VERSION ""

NS_ :

BS_:

BU_: PDCM EPB LBMS GW ExternalTool

BO_ 734 AC_OBD_alertMatrix1: 8 GW
 SG_ AC_OBD_f032_Reserved : 1|2@0+ (1,0) [0|2] ""  PDCM
 SG_ AC_OBD_f033_Reserved : 3|2@0+ (1,0) [0|2] ""  PDCM
 SG_ AC_OBD_f034_HVWHforHC_LostCom : 5|2@0+ (1,0) [0|2] ""  PDCM
 SG_ AC_OBD_f035_HVWHforHC_OveVol : 7|2@0+ (1,0) [0|2] ""  PDCM
 SG_ AC_OBD_f036_HVWHforHC_UndVol : 9|2@0+ (1,0) [0|2] ""  PDCM
 SG_ AC_OBD_f037_HVWHforHC_BoiErr : 11|2@0+ (1,0) [0|2] ""  PDCM
 SG_ AC_OBD_f038_HVWHforHC_CirErr : 13|2@0+ (1,0) [0|2] ""  PDCM
 SG_ AC_OBD_f039_WaterPumpHC : 15|2@0+ (1,0) [0|2] ""  PDCM
 SG_ AC_OBD_f040_3WayValForBat_LosCom : 17|2@0+ (1,0) [0|2] ""  PDCM
 SG_ AC_OBD_f041_3WayValForBat_ResErr : 19|2@0+ (1,0) [0|2] ""  PDCM
 SG_ AC_OBD_f042_3WayValForBat_ActErr : 21|2@0+ (1,0) [0|2] ""  PDCM
 SG_ AC_OBD_f043_3WayValForBat_VolErr : 23|2@0+ (1,0) [0|2] ""  PDCM
 SG_ AC_OBD_f044_ECU_IntFau : 25|2@0+ (1,0) [0|2] ""  PDCM
 SG_ AC_OBD_f045_AMBSensor_SBOL : 27|2@0+ (1,0) [0|2] ""  PDCM
 SG_ AC_OBD_f046_AMBSensor_SG : 29|2@0+ (1,0) [0|2] ""  PDCM
 SG_ AC_OBD_f047_AMBSensor_OutRanLo : 31|2@0+ (1,0) [0|2] ""  PDCM
 SG_ AC_OBD_f048_AMBSensor_OutRanHi : 33|2@0+ (1,0) [0|2] ""  PDCM
 SG_ AC_OBD_f049_AMBSensor_RatFau : 35|2@0+ (1,0) [0|2] ""  PDCM
 SG_ AC_OBD_f050_UnderBatVol : 37|2@0+ (1,0) [0|2] ""  PDCM
 SG_ AC_OBD_f051_OverBatVol : 39|2@0+ (1,0) [0|2] ""  PDCM
 SG_ AC_OBD_f052_ComCANBusOff : 41|2@0+ (1,0) [0|2] ""  PDCM
 SG_ AC_OBD_f053_GW_NoCom : 43|2@0+ (1,0) [0|2] ""  PDCM
 SG_ AC_OBD_FaultClrsts : 47|1@0+ (1,0) [0|1] ""  PDCM
 SG_ AC_EDC_HV_Voltage : 55|8@0+ (5,0) [0|1270] "V"  PDCM
 SG_ AC_HVWH_Bat_HV_Voltage : 63|8@0+ (5,0) [0|500] "V"  PDCM

BO_ 731 AC_OBD_CVN: 8 GW
 SG_ AC_OBDCVNByte0 : 7|8@0+ (1,0) [0|255] ""  PDCM
 SG_ AC_OBDCVNByte1 : 15|8@0+ (1,0) [0|255] ""  PDCM
 SG_ AC_OBDCVNByte2 : 23|8@0+ (1,0) [0|255] ""  PDCM
 SG_ AC_OBDCVNByte3 : 31|8@0+ (1,0) [0|255] ""  PDCM
 SG_ AC_OBD_Comp_OverpPhaseCurrentError : 33|2@0+ (1,0) [0|2] ""  PDCM
 SG_ AC_OBD_Comp_TemperatureSensorError : 35|2@0+ (1,0) [0|2] ""  PDCM
 SG_ AC_OBD_Comp_CurrentSamplingError : 37|2@0+ (1,0) [0|2] ""  PDCM
 SG_ AC_OBD_Comp_DriverError : 39|2@0+ (1,0) [0|2] ""  PDCM
 SG_ AC_OBD_Comp_StartupError : 41|2@0+ (1,0) [0|2] ""  PDCM
 SG_ AC_OBD_Comp_OvertemperatureError : 43|2@0+ (1,0) [0|2] ""  PDCM
 SG_ AC_OBD_Comp_ECU_InternalError : 45|2@0+ (1,0) [0|2] ""  PDCM
 SG_ AC_OBD_Comp_StallError : 47|2@0+ (1,0) [0|2] ""  PDCM
 SG_ AC_OBD_Comp_Hv_UnderVoltageError : 49|2@0+ (1,0) [0|2] ""  PDCM
 SG_ AC_OBD_Comp_Hv_OverVoltageError : 51|2@0+ (1,0) [0|2] ""  PDCM
 SG_ AC_OBD_Comp_Lv_VoltageError : 53|2@0+ (1,0) [0|2] ""  PDCM
 SG_ AC_OBD_EDCStopError : 54|1@0+ (1,0) [0|1] ""  PDCM
 SG_ AC_OBD_PTC_BStopError : 55|1@0+ (1,0) [0|1] ""  PDCM
 SG_ AC_OBD_PTC_CStopError : 56|1@0+ (1,0) [0|1] ""  PDCM

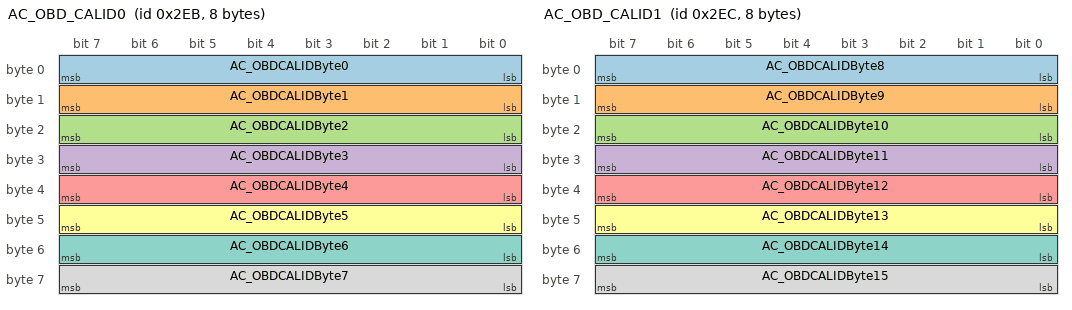
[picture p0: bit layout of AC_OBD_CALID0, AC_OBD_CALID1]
BO_ 747 AC_OBD_CALID0: 8 GW
 SG_ AC_OBDCALIDByte0 : 7|8@0+ (1,0) [0|255] ""  PDCM
 SG_ AC_OBDCALIDByte1 : 15|8@0+ (1,0) [0|255] ""  PDCM
 SG_ AC_OBDCALIDByte2 : 23|8@0+ (1,0) [0|255] ""  PDCM
 SG_ AC_OBDCALIDByte3 : 31|8@0+ (1,0) [0|255] ""  PDCM
 SG_ AC_OBDCALIDByte4 : 39|8@0+ (1,0) [0|255] ""  PDCM
 SG_ AC_OBDCALIDByte5 : 47|8@0+ (1,0) [0|255] ""  PDCM
 SG_ AC_OBDCALIDByte6 : 55|8@0+ (1,0) [0|255] ""  PDCM
 SG_ AC_OBDCALIDByte7 : 63|8@0+ (1,0) [0|255] ""  PDCM

BO_ 748 AC_OBD_CALID1: 8 GW
 SG_ AC_OBDCALIDByte8 : 7|8@0+ (1,0) [0|255] ""  PDCM
 SG_ AC_OBDCALIDByte9 : 15|8@0+ (1,0) [0|255] ""  PDCM
 SG_ AC_OBDCALIDByte10 : 23|8@0+ (1,0) [0|255] ""  PDCM
 SG_ AC_OBDCALIDByte11 : 31|8@0+ (1,0) [0|255] ""  PDCM
 SG_ AC_OBDCALIDByte12 : 39|8@0+ (1,0) [0|255] ""  PDCM
 SG_ AC_OBDCALIDByte13 : 47|8@0+ (1,0) [0|255] ""  PDCM
 SG_ AC_OBDCALIDByte14 : 55|8@0+ (1,0) [0|255] ""  PDCM
 SG_ AC_OBDCALIDByte15 : 63|8@0+ (1,0) [0|255] ""  PDCM

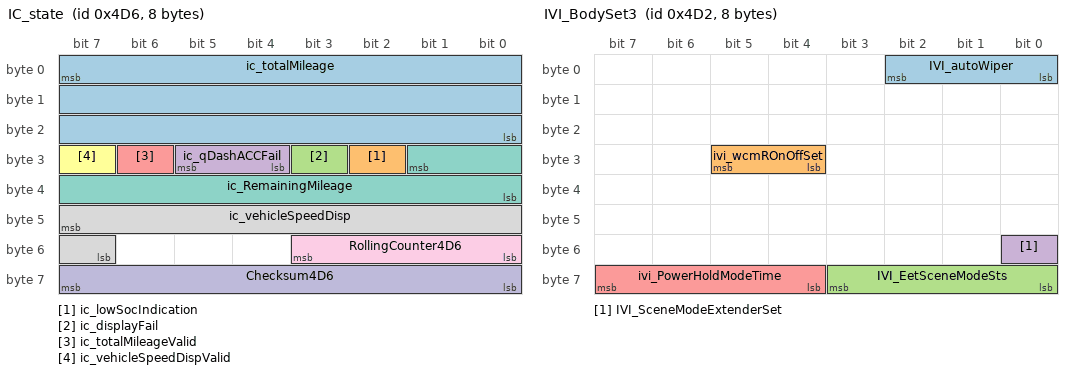
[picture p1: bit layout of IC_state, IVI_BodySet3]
BO_ 1238 IC_state: 8 PDCM
 SG_ ic_totalMileage : 7|24@0+ (0.1,0) [0|1677721.3] "km"  EPB,LBMS,GW
 SG_ ic_lowSocIndication : 26|1@0+ (1,0) [0|1] ""  GW
 SG_ ic_displayFail : 27|1@0+ (1,0) [0|1] ""  GW
 SG_ ic_qDashACCFail : 29|2@0+ (1,0) [0|3] ""  GW
 SG_ ic_totalMileageValid : 30|1@0+ (1,0) [0|1] ""  EPB,LBMS,GW
 SG_ ic_vehicleSpeedDispValid : 31|1@0+ (1,0) [0|1] ""  GW
 SG_ ic_RemainingMileage : 25|10@0+ (1,0) [0|1022] "km"  GW
 SG_ ic_vehicleSpeedDisp : 47|9@0+ (1,0) [0|280] "KPH"  GW
 SG_ RollingCounter4D6 : 51|4@0+ (1,0) [0|15] ""  EPB,LBMS,GW
 SG_ Checksum4D6 : 63|8@0+ (1,0) [0|255] ""  EPB,LBMS,GW

BO_ 1234 IVI_BodySet3: 8 GW
 SG_ IVI_autoWiper : 2|3@0+ (1,0) [0|7] ""  PDCM
 SG_ ivi_wcmROnOffSet : 29|2@0+ (1,0) [0|3] ""  PDCM
 SG_ IVI_EetSceneModeSts : 59|4@0+ (1,0) [0|15] ""  PDCM
 SG_ IVI_SceneModeExtenderSet : 48|1@0+ (1,0) [0|1] ""  PDCM
 SG_ ivi_PowerHoldModeTime : 63|4@0+ (1,0) [0|15] ""  PDCM

BO_ 896 ACU_state: 8 GW
 SG_ acu_warningLampSts : 1|2@0+ (1,0) [0|3] ""  Vector__XXX
 SG_ acu_crashOutputStsValid : 3|2@0+ (1,0) [0|3] ""  LBMS
 SG_ acu_driverSeatBeltSts : 8|1@0+ (1,0) [0|1] ""  Vector__XXX
 SG_ acu_driverSeatBeltStsValid : 9|1@0+ (1,0) [0|1] ""  Vector__XXX
 SG_ acu_passengerSeatBeltSts : 10|1@0+ (1,0) [0|1] ""  Vector__XXX
 SG_ acu_passengerSeatBeltStsValid : 11|1@0+ (1,0) [0|1] ""  Vector__XXX
 SG_ acu_passengerAirbagSts : 13|2@0+ (1,0) [0|3] ""  Vector__XXX
 SG_ acu_secondLeftSeatBeltSts : 14|1@0+ (1,0) [0|1] ""  Vector__XXX
 SG_ acu_secondMiddleSeatBeltSts : 15|1@0+ (1,0) [0|1] ""  Vector__XXX
 SG_ acu_secondRightSeatBeltSts : 16|1@0+ (1,0) [0|1] ""  Vector__XXX
 SG_ acu_passengerSts : 17|1@0+ (1,0) [0|1] ""  Vector__XXX
 SG_ acu_secondLeftSts : 18|1@0+ (1,0) [0|1] ""  Vector__XXX
 SG_ acu_secondMiddleSts : 19|1@0+ (1,0) [0|1] ""  Vector__XXX
 SG_ acu_secondRightSts : 20|1@0+ (1,0) [0|1] ""  Vector__XXX
 SG_ acu_crashOutputSts : 31|8@0+ (1,0) [0|255] ""  LBMS
 SG_ RollingCounter380 : 51|4@0+ (1,0) [0|15] ""  LBMS
 SG_ Checksum380 : 63|8@0+ (1,0) [0|255] ""  LBMS

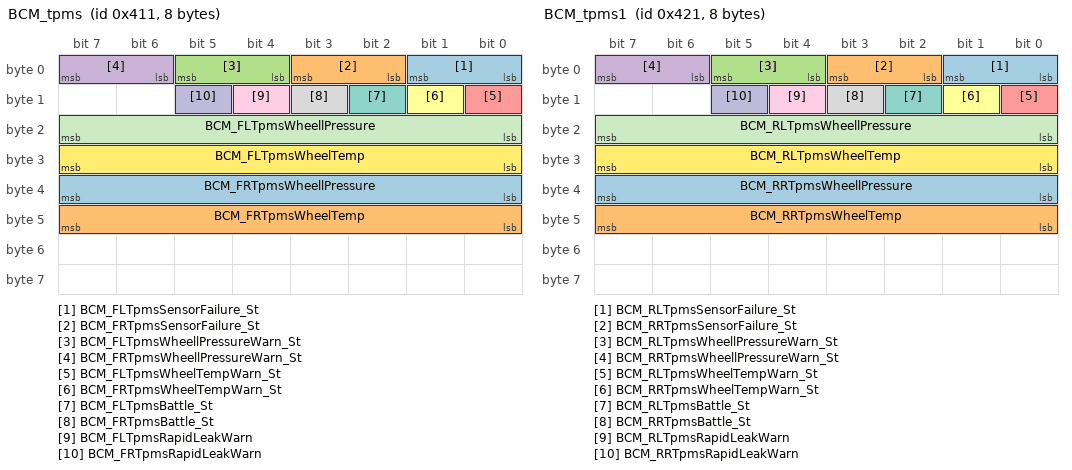
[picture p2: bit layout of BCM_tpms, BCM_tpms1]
BO_ 1041 BCM_tpms: 8 PDCM
 SG_ BCM_FLTpmsSensorFailure_St : 1|2@0+ (1,0) [0|3] ""  Vector__XXX
 SG_ BCM_FRTpmsSensorFailure_St : 3|2@0+ (1,0) [0|3] ""  Vector__XXX
 SG_ BCM_FLTpmsWheellPressureWarn_St : 5|2@0+ (1,0) [0|3] ""  Vector__XXX
 SG_ BCM_FRTpmsWheellPressureWarn_St : 7|2@0+ (1,0) [0|3] ""  Vector__XXX
 SG_ BCM_FLTpmsWheelTempWarn_St : 8|1@0+ (1,0) [0|1] ""  Vector__XXX
 SG_ BCM_FRTpmsWheelTempWarn_St : 9|1@0+ (1,0) [0|1] ""  Vector__XXX
 SG_ BCM_FLTpmsBattle_St : 10|1@0+ (1,0) [0|1] ""  Vector__XXX
 SG_ BCM_FRTpmsBattle_St : 11|1@0+ (1,0) [0|1] ""  Vector__XXX
 SG_ BCM_FLTpmsRapidLeakWarn : 12|1@0+ (1,0) [0|1] ""  Vector__XXX
 SG_ BCM_FRTpmsRapidLeakWarn : 13|1@0+ (1,0) [0|1] ""  Vector__XXX
 SG_ BCM_FLTpmsWheellPressure : 23|8@0+ (0.1,0) [0|7] ""  Vector__XXX
 SG_ BCM_FLTpmsWheelTemp : 31|8@0+ (1,-61) [-61|193] ""  Vector__XXX
 SG_ BCM_FRTpmsWheellPressure : 39|8@0+ (0.1,0) [0|7] ""  Vector__XXX
 SG_ BCM_FRTpmsWheelTemp : 47|8@0+ (1,-61) [-61|193] ""  Vector__XXX

BO_ 1057 BCM_tpms1: 8 PDCM
 SG_ BCM_RLTpmsSensorFailure_St : 1|2@0+ (1,0) [0|3] ""  Vector__XXX
 SG_ BCM_RRTpmsSensorFailure_St : 3|2@0+ (1,0) [0|3] ""  Vector__XXX
 SG_ BCM_RLTpmsWheellPressureWarn_St : 5|2@0+ (1,0) [0|3] ""  Vector__XXX
 SG_ BCM_RRTpmsWheellPressureWarn_St : 7|2@0+ (1,0) [0|3] ""  Vector__XXX
 SG_ BCM_RLTpmsWheelTempWarn_St : 8|1@0+ (1,0) [0|1] ""  Vector__XXX
 SG_ BCM_RRTpmsWheelTempWarn_St : 9|1@0+ (1,0) [0|1] ""  Vector__XXX
 SG_ BCM_RLTpmsBattle_St : 10|1@0+ (1,0) [0|1] ""  Vector__XXX
 SG_ BCM_RRTpmsBattle_St : 11|1@0+ (1,0) [0|1] ""  Vector__XXX
 SG_ BCM_RLTpmsRapidLeakWarn : 12|1@0+ (1,0) [0|1] ""  Vector__XXX
 SG_ BCM_RRTpmsRapidLeakWarn : 13|1@0+ (1,0) [0|1] ""  Vector__XXX
 SG_ BCM_RLTpmsWheellPressure : 23|8@0+ (0.1,0) [0|7] ""  Vector__XXX
 SG_ BCM_RLTpmsWheelTemp : 31|8@0+ (1,-61) [-61|193] ""  Vector__XXX
 SG_ BCM_RRTpmsWheellPressure : 39|8@0+ (0.1,0) [0|7] ""  Vector__XXX
 SG_ BCM_RRTpmsWheelTemp : 47|8@0+ (1,-61) [-61|193] ""  Vector__XXX

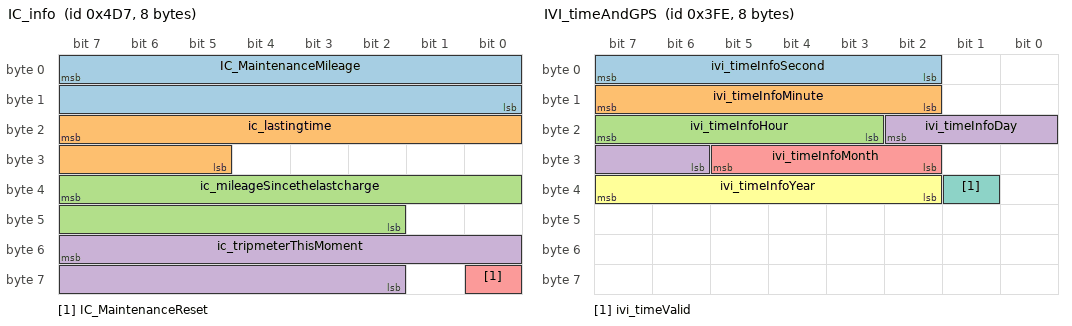
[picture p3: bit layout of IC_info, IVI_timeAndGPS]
BO_ 1239 IC_info: 8 PDCM
 SG_ IC_MaintenanceMileage : 7|16@0+ (1,0) [0|50000] "km"  GW
 SG_ ic_lastingtime : 23|11@0+ (1,0) [0|1440] "min"  GW
 SG_ ic_mileageSincethelastcharge : 39|14@0+ (0.1,0) [0|999.9] "km"  GW
 SG_ ic_tripmeterThisMoment : 55|14@0+ (0.1,0) [0|999.9] "km"  GW
 SG_ IC_MaintenanceReset : 56|1@0+ (1,0) [0|1] ""  GW

BO_ 1235 IC_info1: 8 PDCM
 SG_ ic_totalMileageRev : 7|24@0+ (0.1,0) [0|1677721.3] "km"  GW

BO_ 1022 IVI_timeAndGPS: 8 GW
 SG_ ivi_timeInfoSecond : 7|6@0+ (1,0) [0|59] ""  PDCM,EPB,LBMS
 SG_ ivi_timeInfoMinute : 15|6@0+ (1,0) [0|59] ""  PDCM,EPB,LBMS
 SG_ ivi_timeInfoHour : 23|5@0+ (1,0) [0|23] ""  PDCM,EPB,LBMS
 SG_ ivi_timeInfoDay : 18|5@0+ (1,0) [1|31] ""  PDCM,EPB,LBMS
 SG_ ivi_timeInfoMonth : 29|4@0+ (1,0) [1|12] ""  PDCM,EPB,LBMS
 SG_ ivi_timeInfoYear : 39|6@0+ (1,2000) [2000|2059] ""  PDCM,EPB,LBMS
 SG_ ivi_timeValid : 33|1@0+ (1,0) [0|1] ""  PDCM,EPB,LBMS

BO_ 117 IVI_control: 8 GW
 SG_ ivi_hoodUnlockCtrl : 1|2@0+ (1,0) [0|3] ""  Vector__XXX
 SG_ IVI_SOCmodeSet : 3|2@0+ (1,0) [0|3] ""  PDCM
 SG_ ivi_gloveBoxUnlockCtrl : 5|2@0+ (1,0) [0|3] ""  Vector__XXX
 SG_ IVI_EVonlymodereq_HW : 7|2@0+ (1,0) [0|3] ""  PDCM
 SG_ ivi_v2vChrgOnOffSet : 13|2@0+ (1,0) [0|3] ""  PDCM
 SG_ ivi_obcDschrgOnOffSet : 17|2@0+ (1,0) [0|3] ""  PDCM
 SG_ ivi_modememory : 19|2@0+ (1,0) [0|3] ""  Vector__XXX
 SG_ ivi_gunUnlockCtrlReq : 20|1@0+ (1,0) [0|1] ""  PDCM
 SG_ IVI_apaOnOffSet : 24|1@0+ (1,0) [0|1] ""  Vector__XXX
 SG_ IVI_AVMOnOffSet : 25|1@0+ (1,0) [0|1] ""  Vector__XXX
 SG_ IVI_PDCOnOffSet : 26|1@0+ (1,0) [0|1] ""  Vector__XXX
 SG_ IVI_V2LMinSocSet : 30|4@0+ (5,5) [5|60] "%"  PDCM
 SG_ IVI_UserPrivacyModeSts : 33|2@0+ (1,0) [0|3] ""  Vector__XXX
 SG_ IVI_SelfHeatingAllow : 35|2@0+ (1,0) [0|3] ""  PDCM
 SG_ ivi_ExhibitionSet : 38|3@0+ (1,0) [0|7] ""  PDCM
 SG_ ivi_v2vChrgOptCurntSet : 47|4@0+ (1,0) [0|15] "A"  PDCM
 SG_ ivi_BatteryCondition : 49|2@0+ (1,0) [0|3] ""  Vector__XXX
 SG_ IVI_SREVSOCset : 53|4@0+ (5,25) [25|80] "%"  PDCM
 SG_ IVI_SREVSOCset_HW : 59|4@0+ (1,0) [0|15] ""  PDCM
 SG_ IVI_EVonlymodereq : 61|1@0+ (1,0) [0|1] ""  PDCM
 SG_ ivi_lowVoltPowerCtrl : 63|2@0+ (1,0) [0|3] ""  Vector__XXX

BO_ 165 IVI_pwrSet: 8 GW
 SG_ ivi_MaxFuelConsumptionSW : 1|2@0+ (1,0) [0|3] ""  PDCM
 SG_ ivi_maxChargeCurrentSet : 7|6@0+ (1,5) [5|67] "A"  PDCM
 SG_ ivi_ChargeCancel : 8|1@0+ (1,0) [0|1] ""  PDCM
 SG_ ivi_RegenModeSet : 11|3@0+ (1,0) [0|7] ""  PDCM
 SG_ ivi_MaxFuelConsumptionModeSW : 13|2@0+ (1,0) [0|3] ""  PDCM
 SG_ ivi_propModeSet : 15|2@0+ (1,0) [0|3] ""  PDCM
 SG_ ivi_maxChrgSocSet : 23|8@0+ (1,0) [0|100] "%"  PDCM
 SG_ ivi_startRevSOCSet : 29|6@0+ (1,19) [19|80] "%"  PDCM
 SG_ ivi_ChargeEndTimeHalfDay : 30|1@0+ (1,0) [0|1] ""  PDCM
 SG_ ivi_ChargeStartTimeHalfDay : 31|1@0+ (1,0) [0|1] ""  PDCM
 SG_ ivi_ChargeEndTimeHour : 35|4@0+ (1,0) [0|15] ""  PDCM
 SG_ ivi_ChargeStartTimeHour : 39|4@0+ (1,0) [0|15] ""  PDCM
 SG_ ivi_chargeFormSet : 41|2@0+ (1,0) [0|3] ""  PDCM
 SG_ ivi_ChargeEndTimeMinute : 47|6@0+ (1,0) [0|59] ""  PDCM
 SG_ ivi_ChargeStartTimeMinute : 53|6@0+ (1,0) [0|59] ""  PDCM
 SG_ ivi_ChargeEnable : 54|1@0+ (1,0) [0|1] ""  PDCM
 SG_ ivi_chargeSetValid : 55|1@0+ (1,0) [0|1] ""  PDCM
 SG_ ivi_ResetCurrentTrip : 57|1@0+ (1,0) [0|1] ""  PDCM
 SG_ ivi_ChargeEndTimeValid : 58|1@0+ (1,0) [0|1] ""  PDCM
 SG_ ivi_ChargeStartTimeValid : 59|1@0+ (1,0) [0|1] ""  PDCM
 SG_ ivi_driveModeSet : 62|3@0+ (1,0) [0|7] ""  PDCM

BO_ 476 IVI_BodySet1: 8 GW
 SG_ ivi_centralLockCtrl : 1|2@0+ (1,0) [0|3] ""  PDCM
 SG_ ivi_fuelPortCapOpenCtrl : 3|2@0+ (1,0) [0|3] ""  PDCM
 SG_ ivi_chrgPortCapOpenCtrl : 5|2@0+ (1,0) [0|3] ""  PDCM
 SG_ ivi_antiTheftAlarmFormSet : 7|2@0+ (1,0) [0|3] ""  PDCM
 SG_ ivi_approachingUnlockCtrl : 9|2@0+ (1,0) [0|3] ""  PDCM
 SG_ ivi_awayLockCtrl : 11|2@0+ (1,0) [0|3] ""  PDCM
 SG_ ivi_parkAutoCloseDRLCtrl : 13|2@0+ (1,0) [0|3] ""  PDCM
 SG_ ivi_welcomeSetEnable : 15|2@0+ (1,0) [0|3] ""  PDCM
 SG_ ivi_welcomeOnOffSet : 19|4@0+ (1,0) [0|15] ""  PDCM
 SG_ ivi_followMeHomeSet : 22|3@0+ (1,0) [0|7] ""  PDCM
 SG_ ivi_WiperMaintenanceCtrl : 25|2@0+ (1,0) [0|3] ""  PDCM
 SG_ ivi_lockAutoCloseWinCtrl : 27|2@0+ (1,0) [0|3] ""  PDCM
 SG_ IVI_Backlightadjust : 31|4@0+ (1,0) [0|10] ""  PDCM
 SG_ IVI_Sunroof_HorizontalControl : 38|7@0+ (1,0) [0|100] "%"  PDCM
 SG_ ivi_VehiclePowerOFF : 39|1@0+ (1,0) [0|1] ""  PDCM
 SG_ ivi_sunroofGlassCmd : 42|3@0+ (1,0) [0|7] ""  PDCM
 SG_ ivi_sunroofRollshadeCtrlSelect : 45|2@0+ (1,0) [0|3] ""  PDCM
 SG_ ivi_tailgateCtrl : 47|2@0+ (1,0) [0|3] ""  PDCM
 SG_ IVI_FLReadLightReq : 49|2@0+ (1,0) [0|3] ""  PDCM
 SG_ IVI_FRReadLightReq : 51|2@0+ (1,0) [0|3] ""  PDCM
 SG_ IVI_RLReadLightReq : 53|2@0+ (1,0) [0|3] ""  PDCM
 SG_ IVI_RReadLightReq : 55|2@0+ (1,0) [0|3] ""  PDCM
 SG_ IVI_ITLToplampReq : 57|2@0+ (1,0) [0|3] ""  PDCM
 SG_ ivi_languageSet : 59|2@0+ (1,0) [0|3] ""  PDCM
 SG_ ivi_unitSet : 61|2@0+ (1,0) [0|3] ""  PDCM
 SG_ ivi_OutsideLockAlarmFormSet : 63|2@0+ (1,0) [0|3] ""  PDCM

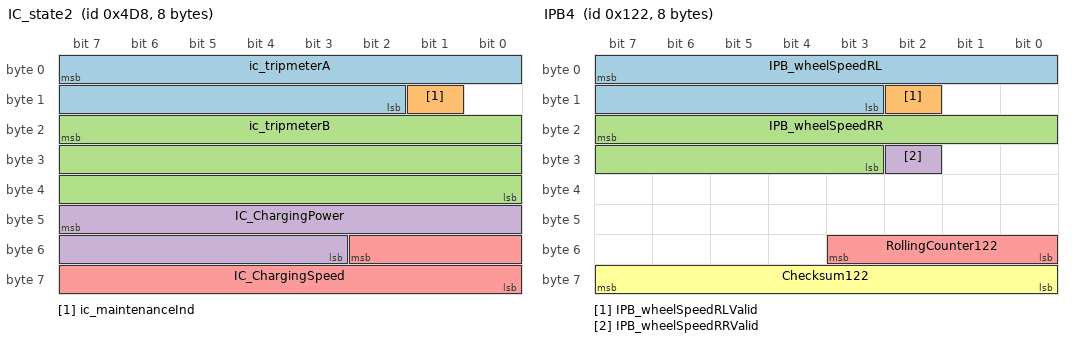
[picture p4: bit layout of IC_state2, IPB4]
BO_ 1240 IC_state2: 8 PDCM
 SG_ ic_tripmeterA : 7|14@0+ (0.1,0) [0|1000] "km"  GW
 SG_ ic_maintenanceInd : 9|1@0+ (1,0) [0|1] ""  GW
 SG_ ic_tripmeterB : 23|24@0+ (0.1,0) [0|99999.9] "km"  GW
 SG_ IC_ChargingPower : 47|13@0+ (0.1,0) [0|500] "kW"  GW
 SG_ IC_ChargingSpeed : 50|11@0+ (1,0) [0|2000] "km/h"  GW

BO_ 290 IPB4: 8 GW
 SG_ IPB_wheelSpeedRL : 7|13@0+ (0.05625,0) [0|270] "km/h"  EPB
 SG_ IPB_wheelSpeedRLValid : 10|1@0+ (1,0) [0|1] ""  EPB
 SG_ IPB_wheelSpeedRR : 23|13@0+ (0.05625,0) [0|270] "km/h"  EPB
 SG_ IPB_wheelSpeedRRValid : 26|1@0+ (1,0) [0|1] ""  EPB
 SG_ RollingCounter122 : 51|4@0+ (1,0) [0|15] ""  EPB
 SG_ Checksum122 : 63|8@0+ (1,0) [0|255] ""  EPB

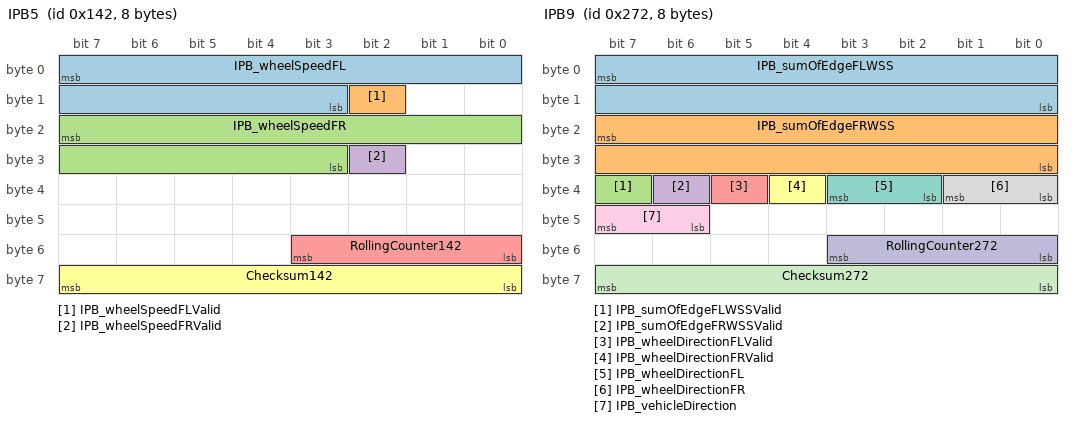
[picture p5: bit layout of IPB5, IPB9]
BO_ 322 IPB5: 8 GW
 SG_ IPB_wheelSpeedFL : 7|13@0+ (0.05625,0) [0|270] "km/h"  EPB
 SG_ IPB_wheelSpeedFLValid : 10|1@0+ (1,0) [0|1] ""  EPB
 SG_ IPB_wheelSpeedFR : 23|13@0+ (0.05625,0) [0|270] "km/h"  EPB
 SG_ IPB_wheelSpeedFRValid : 26|1@0+ (1,0) [0|1] ""  EPB
 SG_ RollingCounter142 : 51|4@0+ (1,0) [0|15] ""  EPB
 SG_ Checksum142 : 63|8@0+ (1,0) [0|255] ""  EPB

BO_ 160 IPB7: 8 GW
 SG_ IPB_vehicleSpeed : 7|13@0+ (0.05625,0) [0|270] "km/h"  EPB,LBMS
 SG_ IPB_vehicleSpeedValid : 10|1@0+ (1,0) [0|1] ""  EPB,LBMS
 SG_ IPB_absFault : 9|1@0+ (1,0) [0|1] ""  Vector__XXX
 SG_ IPB_absActive : 8|1@0+ (1,0) [0|1] ""  Vector__XXX
 SG_ IPB_vdcActive : 16|1@0+ (1,0) [0|1] ""  Vector__XXX
 SG_ IPB_tcsActive : 17|1@0+ (1,0) [0|1] ""  Vector__XXX
 SG_ IPB_avhModeWSts : 19|2@0+ (1,0) [0|3] ""  Vector__XXX
 SG_ IPB_avhAvailable : 20|1@0+ (1,0) [0|1] ""  Vector__XXX
 SG_ IPB_cdpActive : 21|1@0+ (1,0) [0|1] ""  Vector__XXX
 SG_ IPB_cdpAvailable : 22|1@0+ (1,0) [0|1] ""  Vector__XXX
 SG_ IPB_hdcAvailable : 23|1@0+ (1,0) [0|1] ""  Vector__XXX
 SG_ IPB_epbRequest : 25|2@0+ (1,0) [0|3] ""  EPB
 SG_ IPB_vehicleStandstill : 27|2@0+ (1,0) [0|3] ""  Vector__XXX
 SG_ IPB_vehicleStandstillValid : 28|1@0+ (1,0) [0|1] ""  Vector__XXX
 SG_ IPB_ModeSts : 29|1@0+ (1,0) [0|1] ""  Vector__XXX
 SG_ IPB_brakelightRequest : 30|1@0+ (1,0) [0|1] ""  Vector__XXX
 SG_ IPB_hdcSts : 34|3@0+ (1,0) [0|3] ""  Vector__XXX
 SG_ IPB_hhcActive : 35|1@0+ (1,0) [0|1] ""  Vector__XXX
 SG_ IPB_hhcAvailable : 36|1@0+ (1,0) [0|1] ""  Vector__XXX
 SG_ IPB_ebdFault : 37|1@0+ (1,0) [0|1] ""  Vector__XXX
 SG_ IPB_ebd_active : 38|1@0+ (1,0) [0|1] ""  Vector__XXX
 SG_ IPB_ESCoffSts : 39|1@0+ (1,0) [0|1] ""  Vector__XXX
 SG_ IPB_escFault : 40|1@0+ (1,0) [0|1] ""  Vector__XXX
 SG_ IPB_haz_active : 41|1@0+ (1,0) [0|1] ""  Vector__XXX
 SG_ IPB_hazErrorSt : 42|1@0+ (1,0) [0|1] ""  Vector__XXX
 SG_ IPB_hba_active : 43|1@0+ (1,0) [0|1] ""  Vector__XXX
 SG_ IPB_dtcActive : 44|1@0+ (1,0) [0|1] ""  Vector__XXX
 SG_ IPB_esclampdisplay : 46|2@0+ (1,0) [0|2] ""  Vector__XXX
 SG_ IPB_BDWActive : 52|1@0+ (1,0) [0|1] ""  Vector__XXX
 SG_ IPB_HRBActive : 53|1@0+ (1,0) [0|1] ""  Vector__XXX
 SG_ RollingCounter0A0 : 51|4@0+ (1,0) [0|15] ""  LBMS
 SG_ Checksum0A0 : 63|8@0+ (1,0) [0|255] ""  LBMS

BO_ 626 IPB9: 8 GW
 SG_ IPB_sumOfEdgeFLWSS : 7|16@0+ (1,0) [0|65535] ""  EPB
 SG_ IPB_sumOfEdgeFRWSS : 23|16@0+ (1,0) [0|65535] ""  EPB
 SG_ IPB_sumOfEdgeFLWSSValid : 39|1@0+ (1,0) [0|1] ""  EPB
 SG_ IPB_sumOfEdgeFRWSSValid : 38|1@0+ (1,0) [0|1] ""  EPB
 SG_ IPB_wheelDirectionFLValid : 37|1@0+ (1,0) [0|1] ""  EPB
 SG_ IPB_wheelDirectionFRValid : 36|1@0+ (1,0) [0|1] ""  EPB
 SG_ IPB_wheelDirectionFL : 35|2@0+ (1,0) [0|3] ""  EPB
 SG_ IPB_wheelDirectionFR : 33|2@0+ (1,0) [0|3] ""  EPB
 SG_ IPB_vehicleDirection : 47|2@0+ (1,0) [0|3] ""  Vector__XXX
 SG_ RollingCounter272 : 51|4@0+ (1,0) [0|15] ""  EPB
 SG_ Checksum272 : 63|8@0+ (1,0) [0|255] ""  EPB

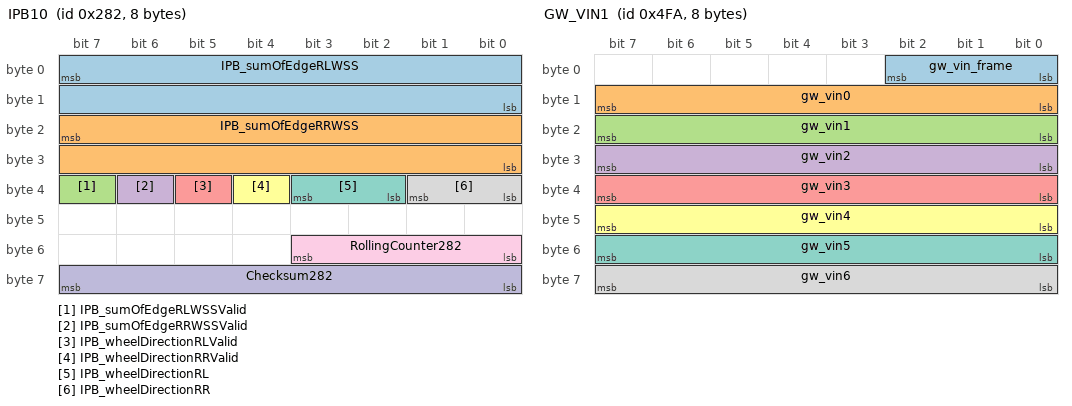
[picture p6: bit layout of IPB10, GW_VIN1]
BO_ 642 IPB10: 8 GW
 SG_ IPB_sumOfEdgeRLWSS : 7|16@0+ (1,0) [0|65535] ""  EPB
 SG_ IPB_sumOfEdgeRRWSS : 23|16@0+ (1,0) [0|65535] ""  EPB
 SG_ IPB_sumOfEdgeRLWSSValid : 39|1@0+ (1,0) [0|1] ""  EPB
 SG_ IPB_sumOfEdgeRRWSSValid : 38|1@0+ (1,0) [0|1] ""  EPB
 SG_ IPB_wheelDirectionRLValid : 37|1@0+ (1,0) [0|1] ""  EPB
 SG_ IPB_wheelDirectionRRValid : 36|1@0+ (1,0) [0|1] ""  EPB
 SG_ IPB_wheelDirectionRL : 35|2@0+ (1,0) [0|3] ""  EPB
 SG_ IPB_wheelDirectionRR : 33|2@0+ (1,0) [0|3] ""  EPB
 SG_ RollingCounter282 : 51|4@0+ (1,0) [0|15] ""  EPB
 SG_ Checksum282 : 63|8@0+ (1,0) [0|255] ""  EPB

BO_ 1274 GW_VIN1: 8 GW
 SG_ gw_vin_frame : 2|3@0+ (1,0) [0|7] ""  ExternalTool
 SG_ gw_vin0 : 15|8@0+ (1,0) [0|255] ""  ExternalTool
 SG_ gw_vin1 : 23|8@0+ (1,0) [0|255] ""  ExternalTool
 SG_ gw_vin2 : 31|8@0+ (1,0) [0|255] ""  ExternalTool
 SG_ gw_vin3 : 39|8@0+ (1,0) [0|255] ""  ExternalTool
 SG_ gw_vin4 : 47|8@0+ (1,0) [0|255] ""  ExternalTool
 SG_ gw_vin5 : 55|8@0+ (1,0) [0|255] ""  ExternalTool
 SG_ gw_vin6 : 63|8@0+ (1,0) [0|255] ""  ExternalTool

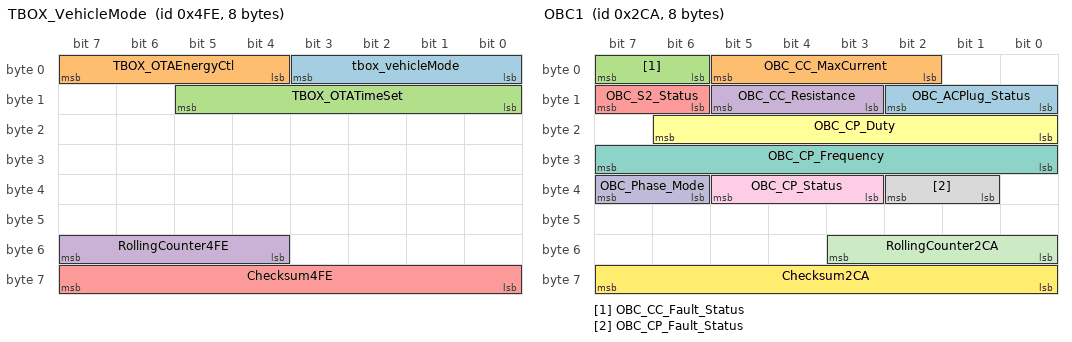
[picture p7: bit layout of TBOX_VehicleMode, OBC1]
BO_ 1278 TBOX_VehicleMode: 8 GW
 SG_ tbox_vehicleMode : 3|4@0+ (1,0) [0|15] ""  PDCM,EPB,LBMS
 SG_ TBOX_OTAEnergyCtl : 7|4@0+ (1,0) [0|15] ""  PDCM
 SG_ TBOX_OTATimeSet : 13|6@0+ (5,0) [0|180] "min"  PDCM
 SG_ RollingCounter4FE : 55|4@0+ (1,0) [0|15] ""  PDCM,EPB,LBMS
 SG_ Checksum4FE : 63|8@0+ (1,0) [0|255] ""  PDCM,EPB,LBMS

BO_ 126 TBOX_chargeSet: 8 GW
 SG_ tbox_reservationChargeMode : 0|1@0+ (1,0) [0|1] ""  PDCM
 SG_ tbox_SysErSt : 2|2@0+ (1,0) [0|3] ""  PDCM
 SG_ TBOX_ChargeContinueSta : 6|2@0+ (1,0) [0|3] ""  Vector__XXX
 SG_ TBOX_ChargeStart : 3|1@0+ (1,0) [0|1] ""  PDCM
 SG_ tbox_chargeSetValid_Reserved : 7|1@0+ (1,0) [0|1] ""  PDCM
 SG_ tbox_MaxChargeCurrentSet : 13|6@0+ (1,5) [5|67] "A"  PDCM
 SG_ tbox_ChargeFormSet : 15|2@0+ (1,0) [0|3] ""  PDCM
 SG_ tbox_ChargeEndTimeHalfDay : 16|1@0+ (1,0) [0|1] ""  PDCM
 SG_ tbox_ChargeEndTimeHour : 20|4@0+ (1,0) [0|15] ""  PDCM
 SG_ tbox_remoteVehicleForbiddenStart : 22|2@0+ (1,0) [0|3] ""  PDCM
 SG_ tbox_ChargeEndTimeMinute : 29|6@0+ (1,0) [0|59] ""  PDCM
 SG_ tbox_ChargeCancel : 30|1@0+ (1,0) [0|1] ""  PDCM
 SG_ tbox_ChargeEnable : 31|1@0+ (1,0) [0|1] ""  PDCM
 SG_ tbox_ChargeStartTimeHalfDay : 32|1@0+ (1,0) [0|1] ""  PDCM
 SG_ tbox_ChargeStartTimeHour : 36|4@0+ (1,0) [0|15] ""  PDCM
 SG_ tbox_EmergencyHvOffReq : 37|1@0+ (1,0) [0|1] ""  PDCM
 SG_ tbox_eCallSts : 39|2@0+ (1,0) [0|3] ""  Vector__XXX
 SG_ tbox_ChargeStartTimeMinute : 45|6@0+ (1,0) [0|59] ""  PDCM
 SG_ tbox_BatteryCondition_Reserved : 46|1@0+ (1,0) [0|1] ""  PDCM
 SG_ tbox_MaxChargeSOCSet : 54|7@0+ (1,0) [0|100] "%"  PDCM
 SG_ tbox_ChargeEndTimeValid : 56|1@0+ (1,0) [0|1] ""  PDCM
 SG_ tbox_ChargeStartTimeValid : 57|1@0+ (1,0) [0|1] ""  PDCM
 SG_ tbox_ChargeSetEnable : 58|1@0+ (1,0) [0|1] ""  PDCM
 SG_ tbox_remoteengStartCmd : 59|1@0+ (1,0) [0|1] ""  PDCM
 SG_ SENTRY_VedioSwitchSet : 63|3@0+ (1,0) [0|7] ""  Vector__XXX
 SG_ tbox_ultrasocengStartCmd : 60|1@0+ (1,0) [0|1] ""  PDCM

BO_ 714 OBC1: 8 PDCM
 SG_ OBC_ACPlug_Status : 10|3@0+ (1,0) [0|7] ""  GW
 SG_ OBC_CC_MaxCurrent : 5|4@0+ (1,0) [0|15] ""  GW
 SG_ OBC_CC_Fault_Status : 7|2@0+ (1,0) [0|3] ""  GW
 SG_ OBC_CC_Resistance : 13|3@0+ (1,0) [0|7] ""  GW
 SG_ OBC_S2_Status : 15|2@0+ (1,0) [0|3] ""  GW
 SG_ OBC_CP_Duty : 22|7@0+ (1,0) [0|127] ""  GW
 SG_ OBC_CP_Frequency : 31|8@0+ (1,900) [900|1155] "Hz"  GW
 SG_ OBC_CP_Fault_Status : 34|2@0+ (1,0) [0|3] ""  GW
 SG_ OBC_CP_Status : 37|3@0+ (1,0) [0|7] ""  GW
 SG_ OBC_Phase_Mode : 39|2@0+ (1,0) [0|3] ""  GW
 SG_ RollingCounter2CA : 51|4@0+ (1,0) [0|15] ""  GW
 SG_ Checksum2CA : 63|8@0+ (1,0) [0|255] ""  GW

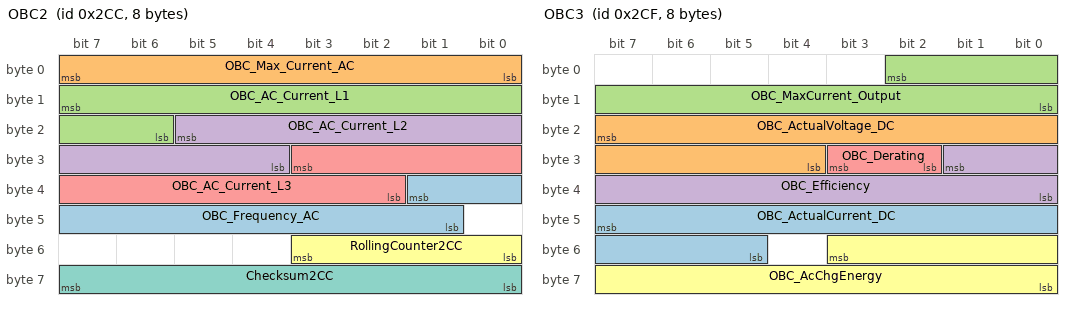
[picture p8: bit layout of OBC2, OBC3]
BO_ 716 OBC2: 8 PDCM
 SG_ OBC_Frequency_AC : 33|9@0+ (0.1,40) [40|80] "Hz"  GW
 SG_ OBC_Max_Current_AC : 7|8@0+ (0.2,0) [0|50] "A"  GW
 SG_ OBC_AC_Current_L1 : 15|10@0+ (0.1,-50) [-50|52.3] "A"  GW
 SG_ OBC_AC_Current_L2 : 21|10@0+ (0.1,-50) [-50|52.3] "A"  GW
 SG_ OBC_AC_Current_L3 : 27|10@0+ (0.1,-50) [-50|52.3] "A"  GW
 SG_ RollingCounter2CC : 51|4@0+ (1,0) [0|15] ""  GW
 SG_ Checksum2CC : 63|8@0+ (1,0) [0|255] ""  GW

BO_ 719 OBC3: 8 PDCM
 SG_ OBC_ActualCurrent_DC : 47|11@0+ (0.1,-100) [-100|104.5] "A"  GW
 SG_ OBC_ActualVoltage_DC : 23|12@0+ (0.25,0) [0|1000] "V"  GW
 SG_ OBC_MaxCurrent_Output : 2|11@0+ (0.1,-100) [-100|104.5] "A"  GW
 SG_ OBC_Efficiency : 25|10@0+ (0.1,0) [0|100] ""  GW
 SG_ OBC_Derating : 27|2@0+ (1,0) [0|3] ""  GW
 SG_ OBC_AcChgEnergy : 51|12@0+ (0.1,0) [0|200] "kwh"  GW

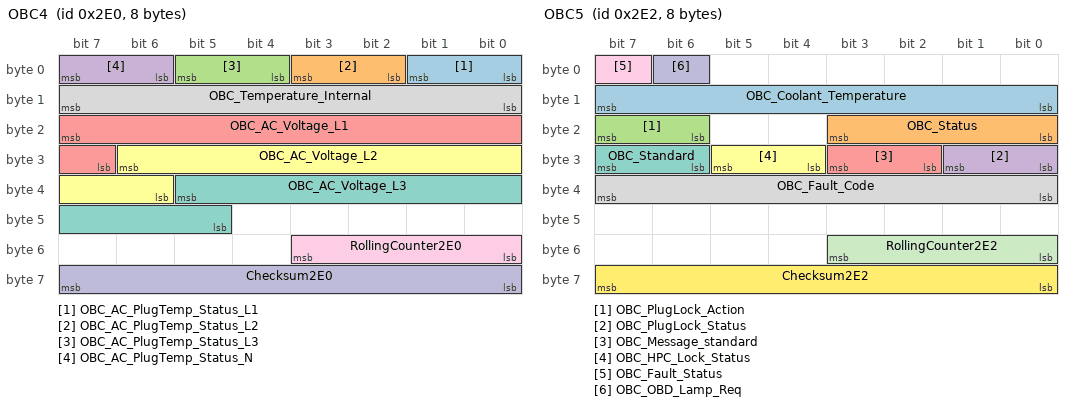
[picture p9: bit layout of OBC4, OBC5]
BO_ 736 OBC4: 8 PDCM
 SG_ OBC_AC_PlugTemp_Status_L1 : 1|2@0+ (1,0) [0|3] ""  GW
 SG_ OBC_AC_PlugTemp_Status_L2 : 3|2@0+ (1,0) [0|3] ""  GW
 SG_ OBC_AC_PlugTemp_Status_L3 : 5|2@0+ (1,0) [0|3] ""  GW
 SG_ OBC_AC_PlugTemp_Status_N : 7|2@0+ (1,0) [0|3] ""  GW
 SG_ OBC_AC_Voltage_L1 : 23|9@0+ (1,0) [0|500] "V"  GW
 SG_ OBC_AC_Voltage_L2 : 30|9@0+ (1,0) [0|500] "V"  GW
 SG_ OBC_AC_Voltage_L3 : 37|9@0+ (1,0) [0|500] "V"  GW
 SG_ OBC_Temperature_Internal : 15|8@0+ (1,-40) [-40|210] "℃"  GW
 SG_ RollingCounter2E0 : 51|4@0+ (1,0) [0|15] ""  GW
 SG_ Checksum2E0 : 63|8@0+ (1,0) [0|255] ""  GW

BO_ 738 OBC5: 8 PDCM
 SG_ OBC_Coolant_Temperature : 15|8@0+ (1,-40) [-40|210] "℃"  GW
 SG_ OBC_Status : 19|4@0+ (1,0) [0|15] ""  GW
 SG_ OBC_PlugLock_Action : 23|2@0+ (1,0) [0|3] ""  GW
 SG_ OBC_PlugLock_Status : 25|2@0+ (1,0) [0|3] ""  GW
 SG_ OBC_Message_standard : 27|2@0+ (1,0) [0|3] ""  GW
 SG_ OBC_HPC_Lock_Status : 29|2@0+ (1,0) [0|3] ""  GW
 SG_ OBC_Standard : 31|2@0+ (1,0) [0|3] ""  GW
 SG_ OBC_Fault_Code : 39|8@0+ (1,0) [0|255] ""  GW
 SG_ OBC_Fault_Status : 7|1@0+ (1,0) [0|1] ""  GW
 SG_ OBC_OBD_Lamp_Req : 6|1@0+ (1,0) [0|1] ""  GW
 SG_ RollingCounter2E2 : 51|4@0+ (1,0) [0|15] ""  GW
 SG_ Checksum2E2 : 63|8@0+ (1,0) [0|255] ""  GW

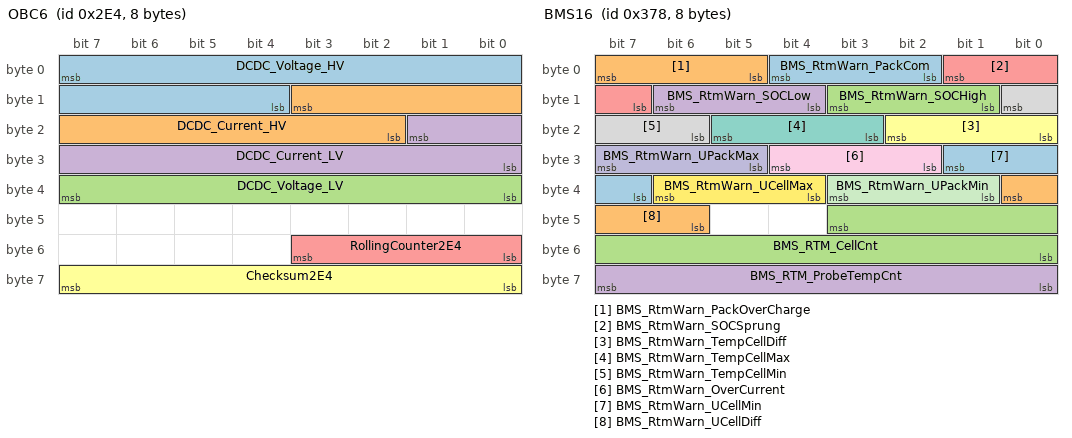
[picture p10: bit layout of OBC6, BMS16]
BO_ 740 OBC6: 8 PDCM
 SG_ DCDC_Voltage_HV : 7|12@0+ (0.25,0) [0|1023.25] "V"  GW
 SG_ DCDC_Current_HV : 11|10@0+ (0.1,-51.1) [-51.1|51] "A"  GW
 SG_ DCDC_Voltage_LV : 39|8@0+ (0.1,0) [0|25.3] "V"  LBMS,GW
 SG_ DCDC_Current_LV : 17|10@0+ (1,-511) [-511|510] "A"  LBMS,GW
 SG_ RollingCounter2E4 : 51|4@0+ (1,0) [0|15] ""  LBMS,GW
 SG_ Checksum2E4 : 63|8@0+ (1,0) [0|255] ""  LBMS,GW

BO_ 865 OBC9: 8 PDCM
 SG_ OBC_AC_PlugTemp_L1 : 7|8@0+ (1,-40) [-40|210] "℃"  GW
 SG_ OBC_AC_PlugTemp_L2 : 15|8@0+ (1,-40) [-40|210] "℃"  GW
 SG_ OBC_AC_PlugTemp_L3 : 23|8@0+ (1,-40) [-40|210] "℃"  GW
 SG_ OBC_AC_PlugTemp_N : 31|8@0+ (1,-40) [-40|210] "℃"  GW

BO_ 888 BMS16: 8 PDCM
 SG_ BMS_RtmWarn_PackCom : 4|3@0+ (1,0) [0|7] ""  GW
 SG_ BMS_RtmWarn_PackOverCharge : 7|3@0+ (1,0) [0|7] ""  GW
 SG_ BMS_RtmWarn_SOCHigh : 11|3@0+ (1,0) [0|7] ""  GW
 SG_ BMS_RtmWarn_SOCLow : 14|3@0+ (1,0) [0|7] ""  GW
 SG_ BMS_RtmWarn_SOCSprung : 1|3@0+ (1,0) [0|7] ""  GW
 SG_ BMS_RtmWarn_TempCellDiff : 18|3@0+ (1,0) [0|7] ""  GW
 SG_ BMS_RtmWarn_TempCellMax : 21|3@0+ (1,0) [0|7] ""  GW
 SG_ BMS_RtmWarn_TempCellMin : 8|3@0+ (1,0) [0|7] ""  GW
 SG_ BMS_RtmWarn_OverCurrent : 28|3@0+ (1,0) [0|7] ""  GW
 SG_ BMS_RtmWarn_UPackMax : 31|3@0+ (1,0) [0|7] ""  GW
 SG_ BMS_RtmWarn_UPackMin : 35|3@0+ (1,0) [0|7] ""  GW
 SG_ BMS_RtmWarn_UCellMax : 38|3@0+ (1,0) [0|7] ""  GW
 SG_ BMS_RtmWarn_UCellMin : 25|3@0+ (1,0) [0|7] ""  GW
 SG_ BMS_RtmWarn_UCellDiff : 32|3@0+ (1,0) [0|7] ""  GW
 SG_ BMS_RTM_CellCnt : 43|12@0+ (1,0) [0|1000] ""  GW
 SG_ BMS_RTM_ProbeTempCnt : 63|8@0+ (1,0) [0|127] ""  GW

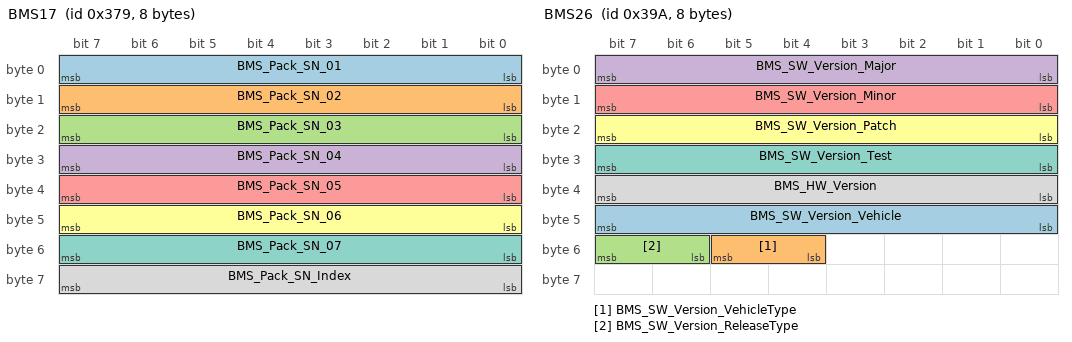
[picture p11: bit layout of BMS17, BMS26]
BO_ 889 BMS17: 8 PDCM
 SG_ BMS_Pack_SN_01 : 7|8@0+ (1,0) [0|255] ""  GW
 SG_ BMS_Pack_SN_02 : 15|8@0+ (1,0) [0|255] ""  GW
 SG_ BMS_Pack_SN_03 : 23|8@0+ (1,0) [0|255] ""  GW
 SG_ BMS_Pack_SN_04 : 31|8@0+ (1,0) [0|255] ""  GW
 SG_ BMS_Pack_SN_05 : 39|8@0+ (1,0) [0|255] ""  GW
 SG_ BMS_Pack_SN_06 : 47|8@0+ (1,0) [0|255] ""  GW
 SG_ BMS_Pack_SN_07 : 55|8@0+ (1,0) [0|255] ""  GW
 SG_ BMS_Pack_SN_Index : 63|8@0+ (1,0) [1|4] ""  GW

BO_ 890 BMS18: 8 PDCM
 SG_ BMS_ChargeEnergy_Total : 7|32@0+ (0.1,0) [0|429496729.5] ""  GW
 SG_ BMS_ChargeCapacity_Total : 39|32@0+ (0.1,0) [0|429496729.5] ""  GW

BO_ 922 BMS26: 8 PDCM
 SG_ BMS_SW_Version_Vehicle : 47|8@0+ (1,0) [0|255] ""  GW
 SG_ BMS_SW_Version_VehicleType : 53|2@0+ (1,0) [0|3] ""  GW
 SG_ BMS_SW_Version_ReleaseType : 55|2@0+ (1,0) [0|3] ""  GW
 SG_ BMS_SW_Version_Major : 7|8@0+ (1,0) [0|255] ""  GW
 SG_ BMS_SW_Version_Minor : 15|8@0+ (1,0) [0|255] ""  GW
 SG_ BMS_SW_Version_Patch : 23|8@0+ (1,0) [0|255] ""  GW
 SG_ BMS_SW_Version_Test : 31|8@0+ (1,0) [0|255] ""  GW
 SG_ BMS_HW_Version : 39|8@0+ (1,0) [0|255] ""  GW

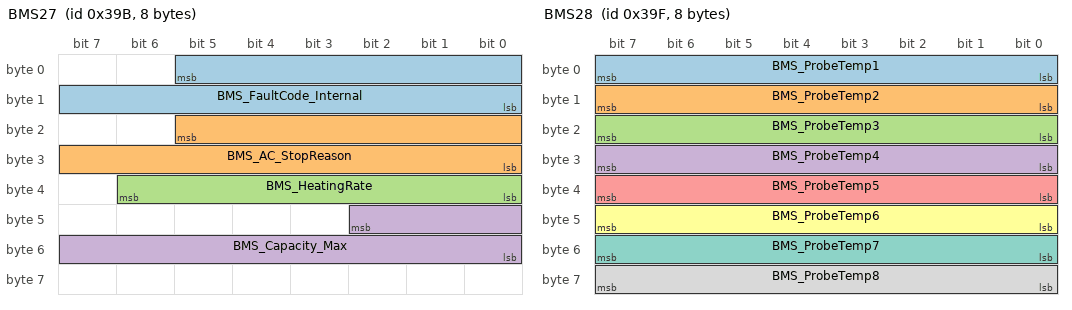
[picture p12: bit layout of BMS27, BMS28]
BO_ 923 BMS27: 8 PDCM
 SG_ BMS_FaultCode_Internal : 5|14@0+ (1,0) [0|16382] ""  GW
 SG_ BMS_AC_StopReason : 21|14@0+ (1,0) [0|16382] ""  GW
 SG_ BMS_HeatingRate : 38|7@0+ (0.1,0) [0|10] "℃/min"  GW
 SG_ BMS_Capacity_Max : 42|11@0+ (0.2,0) [0|400] "Unit_AmperHour"  GW

BO_ 927 BMS28: 8 PDCM
 SG_ BMS_ProbeTemp1 : 7|8@0+ (1,-40) [-40|125] "℃"  GW
 SG_ BMS_ProbeTemp2 : 15|8@0+ (1,-40) [-40|125] "℃"  GW
 SG_ BMS_ProbeTemp3 : 23|8@0+ (1,-40) [-40|125] "℃"  GW
 SG_ BMS_ProbeTemp4 : 31|8@0+ (1,-40) [-40|125] "℃"  GW
 SG_ BMS_ProbeTemp5 : 39|8@0+ (1,-40) [-40|125] "℃"  GW
 SG_ BMS_ProbeTemp6 : 47|8@0+ (1,-40) [-40|125] "℃"  GW
 SG_ BMS_ProbeTemp7 : 55|8@0+ (1,-40) [-40|125] "℃"  GW
 SG_ BMS_ProbeTemp8 : 63|8@0+ (1,-40) [-40|125] "℃"  GW

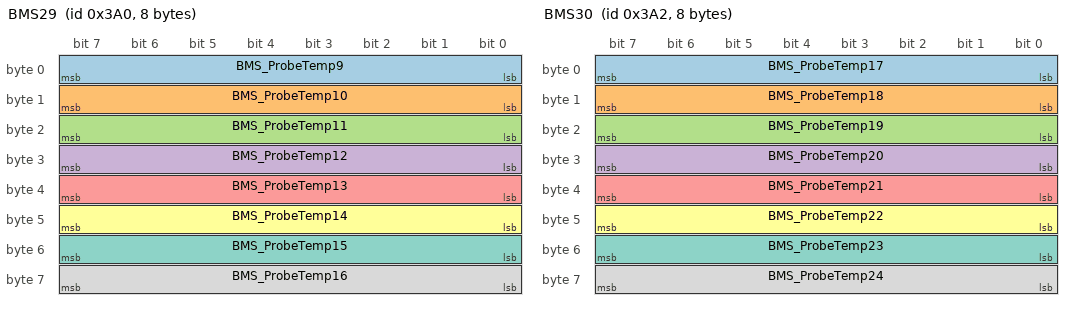
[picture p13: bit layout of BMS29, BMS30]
BO_ 928 BMS29: 8 PDCM
 SG_ BMS_ProbeTemp9 : 7|8@0+ (1,-40) [-40|125] "℃"  GW
 SG_ BMS_ProbeTemp10 : 15|8@0+ (1,-40) [-40|125] "℃"  GW
 SG_ BMS_ProbeTemp11 : 23|8@0+ (1,-40) [-40|125] "℃"  GW
 SG_ BMS_ProbeTemp12 : 31|8@0+ (1,-40) [-40|125] "℃"  GW
 SG_ BMS_ProbeTemp13 : 39|8@0+ (1,-40) [-40|125] "℃"  GW
 SG_ BMS_ProbeTemp14 : 47|8@0+ (1,-40) [-40|125] "℃"  GW
 SG_ BMS_ProbeTemp15 : 55|8@0+ (1,-40) [-40|125] "℃"  GW
 SG_ BMS_ProbeTemp16 : 63|8@0+ (1,-40) [-40|125] "℃"  GW

BO_ 930 BMS30: 8 PDCM
 SG_ BMS_ProbeTemp17 : 7|8@0+ (1,-40) [-40|125] "℃"  GW
 SG_ BMS_ProbeTemp18 : 15|8@0+ (1,-40) [-40|125] "℃"  GW
 SG_ BMS_ProbeTemp19 : 23|8@0+ (1,-40) [-40|125] "℃"  GW
 SG_ BMS_ProbeTemp20 : 31|8@0+ (1,-40) [-40|125] "℃"  GW
 SG_ BMS_ProbeTemp21 : 39|8@0+ (1,-40) [-40|125] "℃"  GW
 SG_ BMS_ProbeTemp22 : 47|8@0+ (1,-40) [-40|125] "℃"  GW
 SG_ BMS_ProbeTemp23 : 55|8@0+ (1,-40) [-40|125] "℃"  GW
 SG_ BMS_ProbeTemp24 : 63|8@0+ (1,-40) [-40|125] "℃"  GW

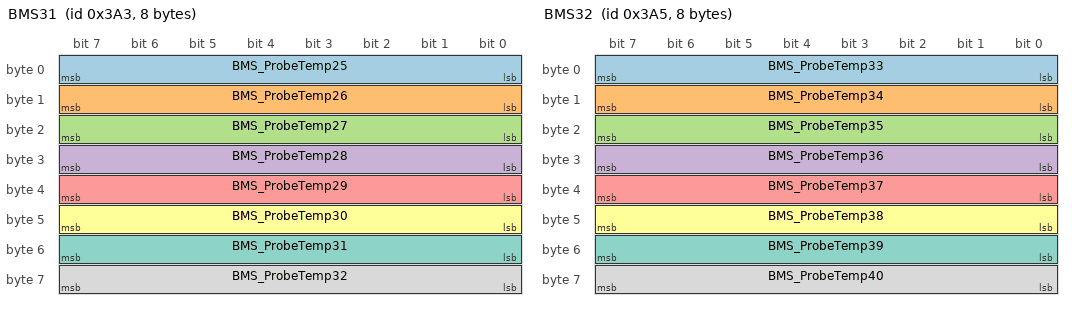
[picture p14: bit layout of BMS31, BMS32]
BO_ 931 BMS31: 8 PDCM
 SG_ BMS_ProbeTemp25 : 7|8@0+ (1,-40) [-40|125] "℃"  GW
 SG_ BMS_ProbeTemp26 : 15|8@0+ (1,-40) [-40|125] "℃"  GW
 SG_ BMS_ProbeTemp27 : 23|8@0+ (1,-40) [-40|125] "℃"  GW
 SG_ BMS_ProbeTemp28 : 31|8@0+ (1,-40) [-40|125] "℃"  GW
 SG_ BMS_ProbeTemp29 : 39|8@0+ (1,-40) [-40|125] "℃"  GW
 SG_ BMS_ProbeTemp30 : 47|8@0+ (1,-40) [-40|125] "℃"  GW
 SG_ BMS_ProbeTemp31 : 55|8@0+ (1,-40) [-40|125] "℃"  GW
 SG_ BMS_ProbeTemp32 : 63|8@0+ (1,-40) [-40|125] "℃"  GW

BO_ 933 BMS32: 8 PDCM
 SG_ BMS_ProbeTemp33 : 7|8@0+ (1,-40) [-40|125] "℃"  GW
 SG_ BMS_ProbeTemp34 : 15|8@0+ (1,-40) [-40|125] "℃"  GW
 SG_ BMS_ProbeTemp35 : 23|8@0+ (1,-40) [-40|125] "℃"  GW
 SG_ BMS_ProbeTemp36 : 31|8@0+ (1,-40) [-40|125] "℃"  GW
 SG_ BMS_ProbeTemp37 : 39|8@0+ (1,-40) [-40|125] "℃"  GW
 SG_ BMS_ProbeTemp38 : 47|8@0+ (1,-40) [-40|125] "℃"  GW
 SG_ BMS_ProbeTemp39 : 55|8@0+ (1,-40) [-40|125] "℃"  GW
 SG_ BMS_ProbeTemp40 : 63|8@0+ (1,-40) [-40|125] "℃"  GW

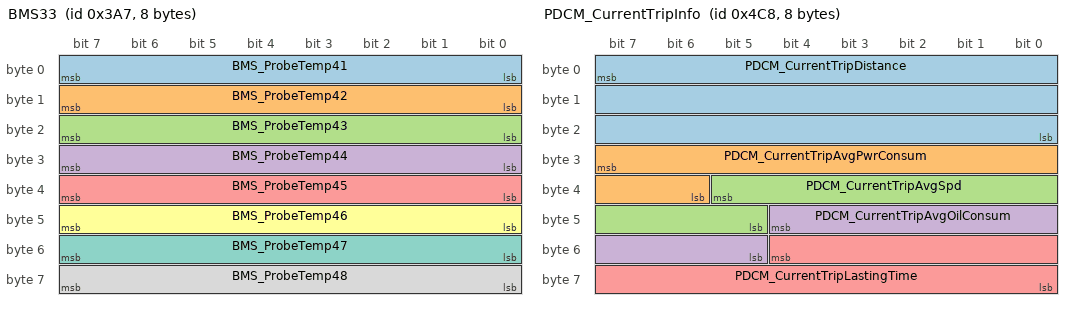
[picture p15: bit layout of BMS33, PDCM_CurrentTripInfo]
BO_ 935 BMS33: 8 PDCM
 SG_ BMS_ProbeTemp41 : 7|8@0+ (1,-40) [-40|125] "℃"  GW
 SG_ BMS_ProbeTemp42 : 15|8@0+ (1,-40) [-40|125] "℃"  GW
 SG_ BMS_ProbeTemp43 : 23|8@0+ (1,-40) [-40|125] "℃"  GW
 SG_ BMS_ProbeTemp44 : 31|8@0+ (1,-40) [-40|125] "℃"  GW
 SG_ BMS_ProbeTemp45 : 39|8@0+ (1,-40) [-40|125] "℃"  GW
 SG_ BMS_ProbeTemp46 : 47|8@0+ (1,-40) [-40|125] "℃"  GW
 SG_ BMS_ProbeTemp47 : 55|8@0+ (1,-40) [-40|125] "℃"  GW
 SG_ BMS_ProbeTemp48 : 63|8@0+ (1,-40) [-40|125] "℃"  GW

BO_ 940 BMS34: 8 PDCM
 SG_ BMS_BattCellVolt1 : 7|16@0+ (0.001,0) [0|5] "V"  GW
 SG_ BMS_BattCellVolt2 : 23|16@0+ (0.001,0) [0|5] "V"  GW
 SG_ BMS_BattCellVolt3 : 39|16@0+ (0.001,0) [0|5] "V"  GW
 SG_ BMS_BattCellVolt4 : 55|16@0+ (0.001,0) [0|5] "V"  GW

BO_ 939 BMS35: 8 PDCM
 SG_ BMS_BattCellVolt5 : 7|16@0+ (0.001,0) [0|5] "V"  GW
 SG_ BMS_BattCellVolt6 : 23|16@0+ (0.001,0) [0|5] "V"  GW
 SG_ BMS_BattCellVolt7 : 39|16@0+ (0.001,0) [0|5] "V"  GW
 SG_ BMS_BattCellVolt8 : 55|16@0+ (0.001,0) [0|5] "V"  GW

BO_ 943 BMS36: 8 PDCM
 SG_ BMS_BattCellVolt9 : 7|16@0+ (0.001,0) [0|5] "V"  GW
 SG_ BMS_BattCellVolt10 : 23|16@0+ (0.001,0) [0|5] "V"  GW
 SG_ BMS_BattCellVolt11 : 39|16@0+ (0.001,0) [0|5] "V"  GW
 SG_ BMS_BattCellVolt12 : 55|16@0+ (0.001,0) [0|5] "V"  GW

BO_ 942 BMS37: 8 PDCM
 SG_ BMS_BattCellVolt13 : 7|16@0+ (0.001,0) [0|5] "V"  GW
 SG_ BMS_BattCellVolt14 : 23|16@0+ (0.001,0) [0|5] "V"  GW
 SG_ BMS_BattCellVolt15 : 39|16@0+ (0.001,0) [0|5] "V"  GW
 SG_ BMS_BattCellVolt16 : 55|16@0+ (0.001,0) [0|5] "V"  GW

BO_ 945 BMS38: 8 PDCM
 SG_ BMS_BattCellVolt17 : 7|16@0+ (0.001,0) [0|5] "V"  GW
 SG_ BMS_BattCellVolt18 : 23|16@0+ (0.001,0) [0|5] "V"  GW
 SG_ BMS_BattCellVolt19 : 39|16@0+ (0.001,0) [0|5] "V"  GW
 SG_ BMS_BattCellVolt20 : 55|16@0+ (0.001,0) [0|5] "V"  GW

BO_ 947 BMS39: 8 PDCM
 SG_ BMS_BattCellVolt21 : 7|16@0+ (0.001,0) [0|5] "V"  GW
 SG_ BMS_BattCellVolt22 : 23|16@0+ (0.001,0) [0|5] "V"  GW
 SG_ BMS_BattCellVolt23 : 39|16@0+ (0.001,0) [0|5] "V"  GW
 SG_ BMS_BattCellVolt24 : 55|16@0+ (0.001,0) [0|5] "V"  GW

BO_ 948 BMS40: 8 PDCM
 SG_ BMS_BattCellVolt25 : 7|16@0+ (0.001,0) [0|5] "V"  GW
 SG_ BMS_BattCellVolt26 : 23|16@0+ (0.001,0) [0|5] "V"  GW
 SG_ BMS_BattCellVolt27 : 39|16@0+ (0.001,0) [0|5] "V"  GW
 SG_ BMS_BattCellVolt28 : 55|16@0+ (0.001,0) [0|5] "V"  GW

BO_ 951 BMS41: 8 PDCM
 SG_ BMS_BattCellVolt29 : 7|16@0+ (0.001,0) [0|5] "V"  GW
 SG_ BMS_BattCellVolt30 : 23|16@0+ (0.001,0) [0|5] "V"  GW
 SG_ BMS_BattCellVolt31 : 39|16@0+ (0.001,0) [0|5] "V"  GW
 SG_ BMS_BattCellVolt32 : 55|16@0+ (0.001,0) [0|5] "V"  GW

BO_ 953 BMS42: 8 PDCM
 SG_ BMS_BattCellVolt33 : 7|16@0+ (0.001,0) [0|5] "V"  GW
 SG_ BMS_BattCellVolt34 : 23|16@0+ (0.001,0) [0|5] "V"  GW
 SG_ BMS_BattCellVolt35 : 39|16@0+ (0.001,0) [0|5] "V"  GW
 SG_ BMS_BattCellVolt36 : 55|16@0+ (0.001,0) [0|5] "V"  GW

BO_ 954 BMS43: 8 PDCM
 SG_ BMS_BattCellVolt37 : 7|16@0+ (0.001,0) [0|5] "V"  GW
 SG_ BMS_BattCellVolt38 : 23|16@0+ (0.001,0) [0|5] "V"  GW
 SG_ BMS_BattCellVolt39 : 39|16@0+ (0.001,0) [0|5] "V"  GW
 SG_ BMS_BattCellVolt40 : 55|16@0+ (0.001,0) [0|5] "V"  GW

BO_ 956 BMS44: 8 PDCM
 SG_ BMS_BattCellVolt41 : 7|16@0+ (0.001,0) [0|5] "V"  GW
 SG_ BMS_BattCellVolt42 : 23|16@0+ (0.001,0) [0|5] "V"  GW
 SG_ BMS_BattCellVolt43 : 39|16@0+ (0.001,0) [0|5] "V"  GW
 SG_ BMS_BattCellVolt44 : 55|16@0+ (0.001,0) [0|5] "V"  GW

BO_ 958 BMS45: 8 PDCM
 SG_ BMS_BattCellVolt45 : 7|16@0+ (0.001,0) [0|5] "V"  GW
 SG_ BMS_BattCellVolt46 : 23|16@0+ (0.001,0) [0|5] "V"  GW
 SG_ BMS_BattCellVolt47 : 39|16@0+ (0.001,0) [0|5] "V"  GW
 SG_ BMS_BattCellVolt48 : 55|16@0+ (0.001,0) [0|5] "V"  GW

BO_ 959 BMS46: 8 PDCM
 SG_ BMS_BattCellVolt49 : 7|16@0+ (0.001,0) [0|5] "V"  GW
 SG_ BMS_BattCellVolt50 : 23|16@0+ (0.001,0) [0|5] "V"  GW
 SG_ BMS_BattCellVolt51 : 39|16@0+ (0.001,0) [0|5] "V"  GW
 SG_ BMS_BattCellVolt52 : 55|16@0+ (0.001,0) [0|5] "V"  GW

BO_ 961 BMS47: 8 PDCM
 SG_ BMS_BattCellVolt53 : 7|16@0+ (0.001,0) [0|5] "V"  GW
 SG_ BMS_BattCellVolt54 : 23|16@0+ (0.001,0) [0|5] "V"  GW
 SG_ BMS_BattCellVolt55 : 39|16@0+ (0.001,0) [0|5] "V"  GW
 SG_ BMS_BattCellVolt56 : 55|16@0+ (0.001,0) [0|5] "V"  GW

BO_ 963 BMS48: 8 PDCM
 SG_ BMS_BattCellVolt57 : 7|16@0+ (0.001,0) [0|5] "V"  GW
 SG_ BMS_BattCellVolt58 : 23|16@0+ (0.001,0) [0|5] "V"  GW
 SG_ BMS_BattCellVolt59 : 39|16@0+ (0.001,0) [0|5] "V"  GW
 SG_ BMS_BattCellVolt60 : 55|16@0+ (0.001,0) [0|5] "V"  GW

BO_ 965 BMS49: 8 PDCM
 SG_ BMS_BattCellVolt61 : 7|16@0+ (0.001,0) [0|5] "V"  GW
 SG_ BMS_BattCellVolt62 : 23|16@0+ (0.001,0) [0|5] "V"  GW
 SG_ BMS_BattCellVolt63 : 39|16@0+ (0.001,0) [0|5] "V"  GW
 SG_ BMS_BattCellVolt64 : 55|16@0+ (0.001,0) [0|5] "V"  GW

BO_ 967 BMS50: 8 PDCM
 SG_ BMS_BattCellVolt65 : 7|16@0+ (0.001,0) [0|5] "V"  GW
 SG_ BMS_BattCellVolt66 : 23|16@0+ (0.001,0) [0|5] "V"  GW
 SG_ BMS_BattCellVolt67 : 39|16@0+ (0.001,0) [0|5] "V"  GW
 SG_ BMS_BattCellVolt68 : 55|16@0+ (0.001,0) [0|5] "V"  GW

BO_ 969 BMS51: 8 PDCM
 SG_ BMS_BattCellVolt69 : 7|16@0+ (0.001,0) [0|5] "V"  GW
 SG_ BMS_BattCellVolt70 : 23|16@0+ (0.001,0) [0|5] "V"  GW
 SG_ BMS_BattCellVolt71 : 39|16@0+ (0.001,0) [0|5] "V"  GW
 SG_ BMS_BattCellVolt72 : 55|16@0+ (0.001,0) [0|5] "V"  GW

BO_ 970 BMS52: 8 PDCM
 SG_ BMS_BattCellVolt73 : 7|16@0+ (0.001,0) [0|5] "V"  GW
 SG_ BMS_BattCellVolt74 : 23|16@0+ (0.001,0) [0|5] "V"  GW
 SG_ BMS_BattCellVolt75 : 39|16@0+ (0.001,0) [0|5] "V"  GW
 SG_ BMS_BattCellVolt76 : 55|16@0+ (0.001,0) [0|5] "V"  GW

BO_ 972 BMS53: 8 PDCM
 SG_ BMS_BattCellVolt77 : 7|16@0+ (0.001,0) [0|5] "V"  GW
 SG_ BMS_BattCellVolt78 : 23|16@0+ (0.001,0) [0|5] "V"  GW
 SG_ BMS_BattCellVolt79 : 39|16@0+ (0.001,0) [0|5] "V"  GW
 SG_ BMS_BattCellVolt80 : 55|16@0+ (0.001,0) [0|5] "V"  GW

BO_ 974 BMS54: 8 PDCM
 SG_ BMS_BattCellVolt81 : 7|16@0+ (0.001,0) [0|5] "V"  GW
 SG_ BMS_BattCellVolt82 : 23|16@0+ (0.001,0) [0|5] "V"  GW
 SG_ BMS_BattCellVolt83 : 39|16@0+ (0.001,0) [0|5] "V"  GW
 SG_ BMS_BattCellVolt84 : 55|16@0+ (0.001,0) [0|5] "V"  GW

BO_ 975 BMS55: 8 PDCM
 SG_ BMS_BattCellVolt85 : 7|16@0+ (0.001,0) [0|5] "V"  GW
 SG_ BMS_BattCellVolt86 : 23|16@0+ (0.001,0) [0|5] "V"  GW
 SG_ BMS_BattCellVolt87 : 39|16@0+ (0.001,0) [0|5] "V"  GW
 SG_ BMS_BattCellVolt88 : 55|16@0+ (0.001,0) [0|5] "V"  GW

BO_ 977 BMS56: 8 PDCM
 SG_ BMS_BattCellVolt89 : 7|16@0+ (0.001,0) [0|5] "V"  GW
 SG_ BMS_BattCellVolt90 : 23|16@0+ (0.001,0) [0|5] "V"  GW
 SG_ BMS_BattCellVolt91 : 39|16@0+ (0.001,0) [0|5] "V"  GW
 SG_ BMS_BattCellVolt92 : 55|16@0+ (0.001,0) [0|5] "V"  GW

BO_ 979 BMS57: 8 PDCM
 SG_ BMS_BattCellVolt93 : 7|16@0+ (0.001,0) [0|5] "V"  GW
 SG_ BMS_BattCellVolt94 : 23|16@0+ (0.001,0) [0|5] "V"  GW
 SG_ BMS_BattCellVolt95 : 39|16@0+ (0.001,0) [0|5] "V"  GW
 SG_ BMS_BattCellVolt96 : 55|16@0+ (0.001,0) [0|5] "V"  GW

BO_ 981 BMS58: 8 PDCM
 SG_ BMS_BattCellVolt97 : 7|16@0+ (0.001,0) [0|5] "V"  GW
 SG_ BMS_BattCellVolt98 : 23|16@0+ (0.001,0) [0|5] "V"  GW
 SG_ BMS_BattCellVolt99 : 39|16@0+ (0.001,0) [0|5] "V"  GW
 SG_ BMS_BattCellVolt100 : 55|16@0+ (0.001,0) [0|5] "V"  GW

BO_ 984 BMS59: 8 PDCM
 SG_ BMS_BattCellVolt101 : 7|16@0+ (0.001,0) [0|5] "V"  GW
 SG_ BMS_BattCellVolt102 : 23|16@0+ (0.001,0) [0|5] "V"  GW
 SG_ BMS_BattCellVolt103 : 39|16@0+ (0.001,0) [0|5] "V"  GW
 SG_ BMS_BattCellVolt104 : 55|16@0+ (0.001,0) [0|5] "V"  GW

BO_ 989 BMS60: 8 PDCM
 SG_ BMS_BattCellVolt105 : 7|16@0+ (0.001,0) [0|5] "V"  GW
 SG_ BMS_BattCellVolt106 : 23|16@0+ (0.001,0) [0|5] "V"  GW
 SG_ BMS_BattCellVolt107 : 39|16@0+ (0.001,0) [0|5] "V"  GW
 SG_ BMS_BattCellVolt108 : 55|16@0+ (0.001,0) [0|5] "V"  GW

BO_ 986 BMS61: 8 PDCM
 SG_ BMS_BattCellVolt109 : 7|16@0+ (0.001,0) [0|5] "V"  GW
 SG_ BMS_BattCellVolt110 : 23|16@0+ (0.001,0) [0|5] "V"  GW
 SG_ BMS_BattCellVolt111 : 39|16@0+ (0.001,0) [0|5] "V"  GW
 SG_ BMS_BattCellVolt112 : 55|16@0+ (0.001,0) [0|5] "V"  GW

BO_ 1220 PDCM_EnergyInfo: 8 PDCM
 SG_ PDCM_BattEnergyAvaliable : 7|11@0+ (0.1,0) [0|200] "kWh"  GW
 SG_ PDCM_oilRemainingValue : 12|11@0+ (0.05,0) [0|100] "L"  GW
 SG_ PDCM_oilPercent : 17|11@0+ (0.1,0) [0|100] "Unit_Percent"  GW
 SG_ PDCM_oilPercentFail : 38|2@0+ (1,0) [0|3] ""  GW

BO_ 1221 PDCM_RemMileage: 8 PDCM
 SG_ PDCM_remainingMileageOil_Standard : 7|11@0+ (1,0) [0|2000] "km"  GW
 SG_ PDCM_remainingMileageOil_Real : 12|11@0+ (1,0) [0|2000] "km"  GW

BO_ 1222 PDCM_TripInfo: 16 PDCM
 SG_ PDCM_TripADistance : 7|24@0+ (0.1,0) [0|99999.9] "km"  GW
 SG_ PDCM_TripAAvgPwrConsum : 31|10@0+ (0.1,-19.9) [-19.9|40] "kWh/100km"  GW
 SG_ PDCM_TripAAvgSpeed : 37|9@0+ (1,0) [0|240] "km/h"  GW
 SG_ PDCM_TripAAvgOilConsum : 44|8@0+ (0.1,0) [0|19.9] "L/100Km"  GW
 SG_ PDCM_TripALastingTime : 52|13@0+ (1,0) [0|5999] "min"  GW
 SG_ PDCM_TripAOilDistance : 71|24@0+ (0.1,0) [0|99999.9] "km"  GW
 SG_ PDCM_TripAPwrDistance : 95|24@0+ (0.1,0) [0|99999.9] "km"  GW

BO_ 1223 PDCM_totalMileageInfo1: 8 PDCM
 SG_ PDCM_totalMilAvgPwrConsum : 31|10@0+ (0.1,-19.9) [-19.9|40] "kWh/100km"  GW
 SG_ PDCM_totalMilAvgSpd : 37|9@0+ (1,0) [0|240] "km/h"  GW
 SG_ PDCM_totalMilAvgOilConsum : 44|8@0+ (0.1,0) [0|19.9] "L/100Km"  GW
 SG_ PDCM_totalMilLastingTime : 52|13@0+ (1,0) [0|5999999] "h"  GW

BO_ 1224 PDCM_CurrentTripInfo: 8 PDCM
 SG_ PDCM_CurrentTripDistance : 7|24@0+ (0.1,0) [0|99999.9] "km"  GW
 SG_ PDCM_CurrentTripAvgPwrConsum : 31|10@0+ (0.1,-19.9) [-19.9|40] "kWh/100km"  GW
 SG_ PDCM_CurrentTripAvgSpd : 37|9@0+ (1,0) [0|240] "km/h"  GW
 SG_ PDCM_CurrentTripAvgOilConsum : 44|8@0+ (0.1,0) [0|19.9] "L/100Km"  GW
 SG_ PDCM_CurrentTripLastingTime : 52|13@0+ (1,0) [0|5999] "min"  GW

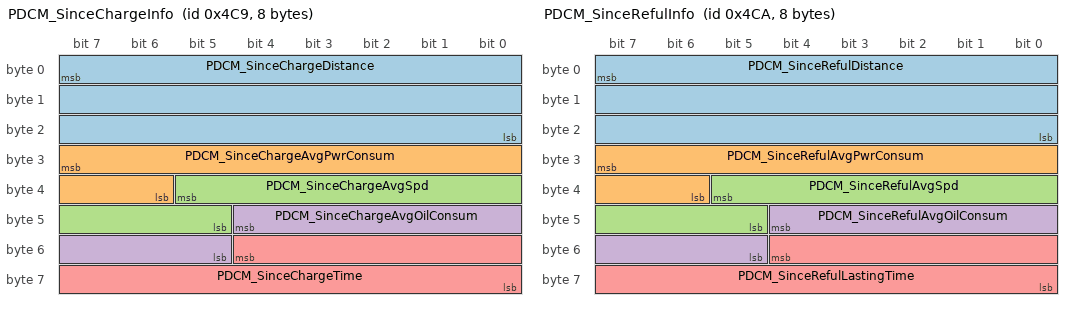
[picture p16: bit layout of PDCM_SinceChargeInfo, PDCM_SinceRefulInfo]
BO_ 1225 PDCM_SinceChargeInfo: 8 PDCM
 SG_ PDCM_SinceChargeDistance : 7|24@0+ (0.1,0) [0|99999.9] "km"  GW
 SG_ PDCM_SinceChargeAvgPwrConsum : 31|10@0+ (0.1,-19.9) [-19.9|40] "kWh/100km"  GW
 SG_ PDCM_SinceChargeAvgSpd : 37|9@0+ (1,0) [0|240] "km/h"  GW
 SG_ PDCM_SinceChargeAvgOilConsum : 44|8@0+ (0.1,0) [0|19.9] "L/100Km"  GW
 SG_ PDCM_SinceChargeTime : 52|13@0+ (1,0) [0|5999] "min"  GW

BO_ 1226 PDCM_SinceRefulInfo: 8 PDCM
 SG_ PDCM_SinceRefulDistance : 7|24@0+ (0.1,0) [0|99999.9] "km"  GW
 SG_ PDCM_SinceRefulAvgPwrConsum : 31|10@0+ (0.1,-19.9) [-19.9|40] "kWh/100km"  GW
 SG_ PDCM_SinceRefulAvgSpd : 37|9@0+ (1,0) [0|240] "km/h"  GW
 SG_ PDCM_SinceRefulAvgOilConsum : 44|8@0+ (0.1,0) [0|19.9] "L/100Km"  GW
 SG_ PDCM_SinceRefulLastingTime : 52|13@0+ (1,0) [0|5999] "min"  GW

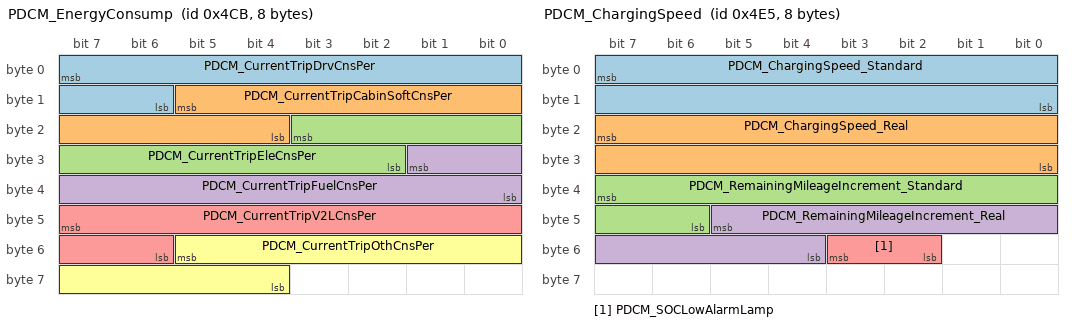
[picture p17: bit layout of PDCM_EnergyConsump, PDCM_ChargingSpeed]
BO_ 1227 PDCM_EnergyConsump: 8 PDCM
 SG_ PDCM_CurrentTripDrvCnsPer : 7|10@0+ (0.1,0) [0|100] "%"  GW
 SG_ PDCM_CurrentTripCabinSoftCnsPer : 13|10@0+ (0.1,0) [0|100] "%"  GW
 SG_ PDCM_CurrentTripEleCnsPer : 19|10@0+ (0.1,0) [0|100] "%"  GW
 SG_ PDCM_CurrentTripFuelCnsPer : 25|10@0+ (0.1,0) [0|100] "%"  GW
 SG_ PDCM_CurrentTripV2LCnsPer : 47|10@0+ (0.1,0) [0|100] "%"  GW
 SG_ PDCM_CurrentTripOthCnsPer : 53|10@0+ (0.1,0) [0|100] "%"  GW

BO_ 1228 PDCM_SelfCharging: 16 PDCM
 SG_ PDCM_SinceChargeDrvCnsPer : 7|10@0+ (0.1,0) [0|100] "%"  GW
 SG_ PDCM_SinceChargeCabinSoftCnsPer : 13|10@0+ (0.1,0) [0|100] "%"  GW
 SG_ PDCM_SinceChargeEleCnsPer : 19|10@0+ (0.1,0) [0|100] "%"  GW
 SG_ PDCM_SinceChargeFuelCnsPer : 25|10@0+ (0.1,0) [0|100] "%"  GW
 SG_ PDCM_SinceChargeV2LCnsPer : 47|10@0+ (0.1,0) [0|100] "%"  GW
 SG_ PDCM_SinceChargeOthCnsPer : 53|10@0+ (0.1,0) [0|100] "%"  GW
 SG_ PDCM_SinceChargeEVCnsPer : 59|10@0+ (0.1,0) [0|100] "%"  GW

BO_ 1229 PDCM_SelfRefueling: 16 PDCM
 SG_ PDCM_SinceRefulDrvCnsPer : 7|10@0+ (0.1,0) [0|100] "%"  GW
 SG_ PDCM_SinceRefulCabinSoftCnsPer : 13|10@0+ (0.1,0) [0|100] "%"  GW
 SG_ PDCM_SinceRefulEleCnsPer : 19|10@0+ (0.1,0) [0|100] "%"  GW
 SG_ PDCM_SinceRefulFuelCnsPer : 25|10@0+ (0.1,0) [0|100] "%"  GW
 SG_ PDCM_SinceRefulV2LCnsPer : 47|10@0+ (0.1,0) [0|100] "%"  GW
 SG_ PDCM_SinceRefulOthCnsPer : 53|10@0+ (0.1,0) [0|100] "%"  GW
 SG_ PDCM_SinceRefulSeriCnsPer : 59|10@0+ (0.1,0) [0|100] "%"  GW
 SG_ PDCM_SinceRefulParalCnsPer : 65|10@0+ (0.1,0) [0|100] "%"  GW

BO_ 1230 PDCM_SubtotalMileage: 16 PDCM
 SG_ PDCM_SinceTripADrvCnsPer : 7|10@0+ (0.1,0) [0|100] "%"  GW
 SG_ PDCM_SinceTripACabinSoftCnsPer : 13|10@0+ (0.1,0) [0|100] "%"  GW
 SG_ PDCM_SinceTripAEleCnsPer : 19|10@0+ (0.1,0) [0|100] "%"  GW
 SG_ PDCM_SinceTripAFuelCnsPer : 25|10@0+ (0.1,0) [0|100] "%"  GW
 SG_ PDCM_SinceTripAV2LCnsPer : 47|10@0+ (0.1,0) [0|100] "%"  GW
 SG_ PDCM_SinceTripAOthCnsPer : 53|10@0+ (0.1,0) [0|100] "%"  GW
 SG_ PDCM_SinceTripAEVCnsPer : 59|10@0+ (0.1,0) [0|100] "%"  GW
 SG_ PDCM_SinceTripASeriCnsPer : 65|10@0+ (0.1,0) [0|100] "%"  GW
 SG_ PDCM_SinceTripAParalCnsPer : 87|10@0+ (0.1,0) [0|100] "%"  GW

BO_ 1231 PDCM_DailyEnergyConsu: 8 PDCM
 SG_ PDCM_DayAvgOilConsum : 7|8@0+ (0.1,0) [0|19.9] "L/100Km"  GW
 SG_ PDCM_DayAvgPwrConsum : 15|10@0+ (0.1,-19.9) [-19.9|40] "kWh/100km"  GW

BO_ 1232 PDCM_InstanEnergyConsu: 8 PDCM
 SG_ PDCM_ConsumpRatioInstantDrv : 3|12@0+ (0.1,-40) [-40|99.9] "kW.h /km"  GW
 SG_ PDCM_ConsumpRatioInstantSt : 19|12@0+ (0.1,-40) [-40|99.9] "kW.h /h"  GW
 SG_ PDCM_FuelConsumpDrv : 35|12@0+ (0.1,0) [0|99.9] "L/100Km"  GW
 SG_ PDCM_FuelConsumpSt : 51|12@0+ (0.1,0) [0|99.9] "L/h"  GW

BO_ 1233 PDCM_totalMileageInfo2: 8 PDCM
 SG_ PDCM_totalMileage : 7|24@0+ (0.1,0) [0|1677721.3] "km"  EPB,GW
 SG_ PDCM_totalMileageValid : 24|1@0+ (1,0) [0|1] ""  EPB,GW
 SG_ PDCM_totalMileageRev : 39|24@0+ (0.1,0) [0|1677721.3] "km"  EPB,GW

BO_ 1253 PDCM_ChargingSpeed: 8 PDCM
 SG_ PDCM_ChargingSpeed_Standard : 7|16@0+ (0.1,0) [0|6553.5] "km/hr"  GW
 SG_ PDCM_ChargingSpeed_Real : 23|16@0+ (0.1,0) [0|6553.5] "km/hr"  GW
 SG_ PDCM_RemainingMileageIncrement_Standard : 39|10@0+ (1,0) [0|1023] "km"  GW
 SG_ PDCM_RemainingMileageIncrement_Real : 45|10@0+ (1,0) [0|1023] "km"  GW
 SG_ PDCM_SOCLowAlarmLamp : 51|2@0+ (1,0) [0|3] ""  GW

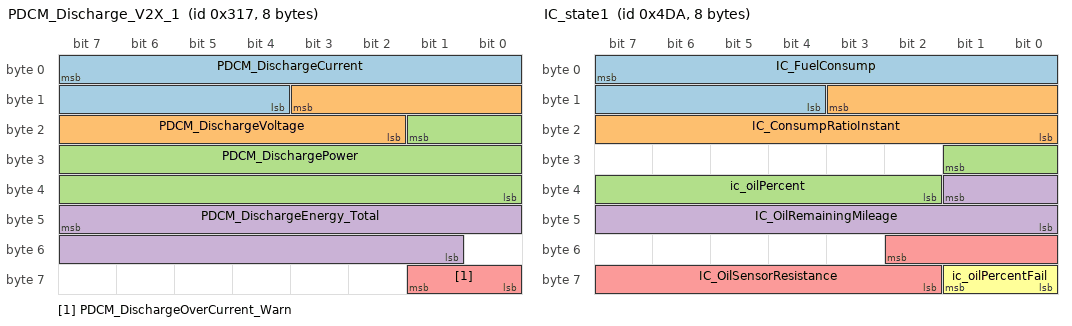
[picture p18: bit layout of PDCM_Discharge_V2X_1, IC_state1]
BO_ 791 PDCM_Discharge_V2X_1: 8 PDCM
 SG_ PDCM_DischargeCurrent : 7|12@0+ (0.1,0) [0|409.5] "A"  GW
 SG_ PDCM_DischargeVoltage : 11|10@0+ (1,0) [0|1023] "V"  GW
 SG_ PDCM_DischargePower : 17|18@0+ (1,0) [0|262143] "W"  GW
 SG_ PDCM_DischargeEnergy_Total : 47|15@0+ (0.01,0) [0|327.67] "kWh"  GW
 SG_ PDCM_DischargeOverCurrent_Warn : 57|2@0+ (1,0) [0|3] ""  GW

BO_ 792 PDCM_Discharge_V2X_2: 8 PDCM
 SG_ PDCM_ExternalLoadPwr : 7|16@0+ (1,0) [0|30000] "W"  GW

BO_ 1242 IC_state1: 8 PDCM
 SG_ IC_FuelConsump : 7|12@0+ (0.1,0) [0|99.9] "L/100Km"  GW
 SG_ IC_ConsumpRatioInstant : 11|12@0+ (0.1,0) [0|99.9] "kW.h /km"  GW
 SG_ ic_oilPercent : 25|8@0+ (1,0) [0|100] "%"  GW
 SG_ IC_OilRemainingMileage : 33|10@0+ (1,0) [0|999] "km"  GW
 SG_ IC_OilSensorResistance : 50|9@0+ (1,0) [0|300] "Ω"  GW
 SG_ ic_oilPercentFail : 57|2@0+ (1,0) [0|3] ""  GW

BO_ 837 LBMS_State1: 32 LBMS
 SG_ LBMS_CellU1 : 7|13@0+ (0.001,0) [0|5] "V"  PDCM,GW
 SG_ LBMS_CellU2 : 10|13@0+ (0.001,0) [0|5] "V"  PDCM,GW
 SG_ LBMS_CellU3 : 29|13@0+ (0.001,0) [0|5] "V"  PDCM,GW
 SG_ LBMS_CellU4 : 32|13@0+ (0.001,0) [0|5] "V"  PDCM,GW
 SG_ LBMS_Cell1UVld : 51|1@0+ (1,0) [0|1] ""  PDCM,GW
 SG_ LBMS_Cell2UVld : 50|1@0+ (1,0) [0|1] ""  PDCM,GW
 SG_ LBMS_Cell3UVld : 49|1@0+ (1,0) [0|1] ""  PDCM,GW
 SG_ LBMS_Cell4UVld : 48|1@0+ (1,0) [0|1] ""  PDCM,GW
 SG_ LBMS_PackCurrent : 63|21@0+ (0.001,-1000) [-1000|1000] "A"  PDCM,GW
 SG_ LBMS_PackIntU : 74|15@0+ (0.001,0) [0|20] "V"  PDCM,GW
 SG_ LBMS_PackExtU : 90|14@0+ (0.0009765625,3) [3|18] "V"  PDCM,GW
 SG_ LBMS_PackIntUVld : 108|1@0+ (1,0) [0|1] ""  PDCM,GW
 SG_ LBMS_PackExtUVld : 107|1@0+ (1,0) [0|1] ""  PDCM,GW
 SG_ LBMS_PackT1 : 106|8@0+ (1,-40) [-40|125] "degC"  PDCM,GW
 SG_ LBMS_PackT2 : 114|8@0+ (1,-40) [-40|125] "degC"  PDCM,GW
 SG_ LBMS_PackT3 : 122|8@0+ (1,-40) [-40|125] "degC"  PDCM,GW
 SG_ LBMS_PackT1Vld : 130|1@0+ (1,0) [0|1] ""  PDCM,GW
 SG_ LBMS_DisMOSReq : 144|1@0+ (1,0) [0|1] ""  PDCM,GW
 SG_ LBMS_PackIntUCal : 129|15@0+ (0.001,0) [0|20] "V"  PDCM,GW
 SG_ LBMS_PackIntUCalVld : 146|1@0+ (1,0) [0|1] ""  PDCM,GW
 SG_ LBMS_PackCurrentVld : 145|1@0+ (1,0) [0|1] ""  PDCM,GW
 SG_ LBMS_AHChrgTotlife : 159|32@0+ (0.001,0) [0|4294967.295] "Ah"  PDCM,GW
 SG_ LBMS_AHDisChrgTotlife : 191|32@0+ (0.001,0) [0|4294967.295] "Ah"  PDCM,GW
 SG_ LBMS_AHChrgVld : 223|1@0+ (1,0) [0|1] ""  PDCM,GW
 SG_ LBMS_AHDisChrgVld : 222|1@0+ (1,0) [0|1] ""  PDCM,GW
 SG_ LBMS_PackT2Vld : 221|1@0+ (1,0) [0|1] ""  PDCM,GW
 SG_ LBMS_PackT3Vld : 220|1@0+ (1,0) [0|1] ""  PDCM,GW
 SG_ LBMS_DischrgMOST : 231|8@0+ (1,-40) [-40|125] "degC"  PDCM,GW
 SG_ LBMS_ChrgCMOST : 239|8@0+ (1,-40) [-40|125] "degC"  PDCM,GW
 SG_ LBMS_BalanceTemp : 247|8@0+ (1,-40) [-40|125] "degC"  PDCM,GW
 SG_ LBMS_BuckT : 255|8@0+ (1,-40) [-40|125] "degC"  PDCM,GW

BO_ 838 LBMS_State2: 32 LBMS
 SG_ LBMS_SOCVld : 8|1@0+ (1,0) [0|1] ""  PDCM,GW
 SG_ LBMS_SOH : 39|7@0+ (1,0) [0|100] "%"  PDCM,GW
 SG_ LBMS_ChrgMosSt : 32|1@0+ (1,0) [0|1] ""  PDCM,GW
 SG_ LBMS_DischrgMosSt : 31|1@0+ (1,0) [0|1] ""  PDCM,GW
 SG_ LBMS_BuckStatus : 30|1@0+ (1,0) [0|1] ""  PDCM,GW
 SG_ LBMS_ReChrgReq : 29|3@0+ (1,0) [0|7] ""  PDCM,GW
 SG_ LBMS_WorkSt : 26|3@0+ (1,0) [0|7] ""  PDCM,GW
 SG_ LBMS_RealSOC : 23|7@0+ (1,0) [0|100] "%"  PDCM,GW
 SG_ LBMS_MOSForcedControlSt : 16|1@0+ (1,0) [0|1] ""  PDCM,GW
 SG_ LBMS_MaxAllwChrgU : 7|15@0+ (0.001,0) [0|20] "V"  PDCM,GW
 SG_ LBMS_ReqChrgU : 47|15@0+ (0.001,0) [0|20] "V"  PDCM,GW
 SG_ LBMS_MaxAllwChrgCurrent : 57|21@0+ (0.001,-1000) [-1000|1000] "A"  PDCM,GW
 SG_ LBMS_MaxAllwDischrgCurrent : 84|21@0+ (0.001,-1000) [-1000|1000] "A"  PDCM,GW
 SG_ LBMS_Cell1BalSt : 104|1@0+ (1,0) [0|1] ""  PDCM,GW
 SG_ LBMS_Cell2BalSt : 105|1@0+ (1,0) [0|1] ""  PDCM,GW
 SG_ LBMS_Cell3BalSt : 106|1@0+ (1,0) [0|1] ""  PDCM,GW
 SG_ LBMS_Cell4BalSt : 107|1@0+ (1,0) [0|1] ""  PDCM,GW
 SG_ LBMS_SOCCalMod : 110|3@0+ (1,0) [0|7] ""  PDCM,GW
 SG_ LBMS_LowSOCWakeupThre : 118|7@0+ (1,0) [0|100] "%"  PDCM,GW
 SG_ LBMS_LowUWakeupThre : 127|15@0+ (0.001,0) [0|20] "V"  PDCM,GW
 SG_ LBMS_ChrgReqCounter : 143|8@0+ (1,0) [0|255] ""  PDCM,GW
 SG_ LBMS_ChargMOSDriU : 151|8@0+ (1,0) [0|255] "V"  PDCM,GW
 SG_ LBMS_DisChargMOSDriU : 159|8@0+ (1,0) [0|255] "V"  PDCM,GW
 SG_ LBMS_SOC : 167|8@0+ (1,0) [0|100] "%"  PDCM,GW
 SG_ RollingCounter346 : 243|4@0+ (1,0) [0|15] ""  PDCM,GW
 SG_ Checksum346 : 255|8@0+ (1,0) [0|255] ""  PDCM,GW

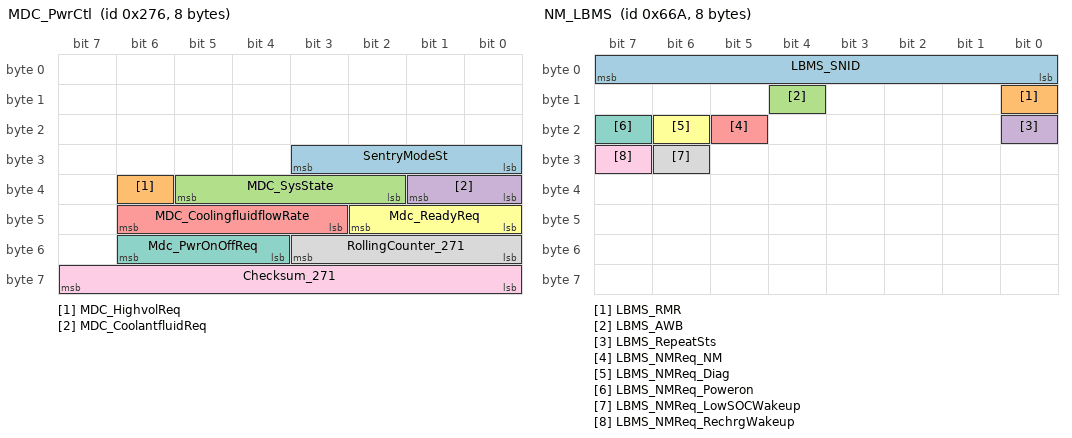
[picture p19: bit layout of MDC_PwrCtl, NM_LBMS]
BO_ 630 MDC_PwrCtl: 8 GW
 SG_ SentryModeSt : 27|4@0+ (1,0) [0|15] ""  PDCM
 SG_ MDC_HighvolReq : 38|1@0+ (1,0) [0|1] ""  PDCM
 SG_ MDC_SysState : 37|4@0+ (1,0) [0|15] ""  Vector__XXX
 SG_ MDC_CoolantfluidReq : 33|2@0+ (1,0) [0|3] ""  PDCM
 SG_ MDC_CoolingfluidflowRate : 46|4@0+ (1,0) [0|15] ""  PDCM
 SG_ Mdc_ReadyReq : 42|3@0+ (1,0) [0|7] ""  PDCM
 SG_ Mdc_PwrOnOffReq : 54|3@0+ (1,0) [0|7] ""  PDCM
 SG_ RollingCounter_271 : 51|4@0+ (1,0) [0|15] ""  PDCM
 SG_ Checksum_271 : 63|8@0+ (1,0) [0|255] ""  PDCM

BO_ 1585 NM_PDCM_PT: 8 PDCM
 SG_ PDCM_PT_RMR : 8|1@0+ (1,0) [0|1] ""  EPB,LBMS,GW
 SG_ PDCM_PT_AWB : 12|1@0+ (1,0) [0|1] ""  EPB,LBMS,GW

BO_ 1616 NM_EPB_PT: 8 EPB
 SG_ EPB_PT_RMR : 8|1@0+ (1,0) [0|1] ""  PDCM,LBMS,GW
 SG_ EPB_PT_AWB : 12|1@0+ (1,0) [0|1] ""  PDCM,LBMS,GW

BO_ 1642 NM_LBMS: 8 LBMS
 SG_ LBMS_SNID : 7|8@0+ (1,0) [0|255] ""  PDCM,EPB,GW
 SG_ LBMS_RMR : 8|1@0+ (1,0) [0|1] ""  PDCM,EPB,GW
 SG_ LBMS_AWB : 12|1@0+ (1,0) [0|1] ""  PDCM,EPB,GW
 SG_ LBMS_RepeatSts : 16|1@0+ (1,0) [0|1] ""  PDCM,EPB,GW
 SG_ LBMS_NMReq_NM : 21|1@0+ (1,0) [0|1] ""  PDCM,EPB,GW
 SG_ LBMS_NMReq_Diag : 22|1@0+ (1,0) [0|1] ""  PDCM,EPB,GW
 SG_ LBMS_NMReq_Poweron : 23|1@0+ (1,0) [0|1] ""  PDCM,EPB,GW
 SG_ LBMS_NMReq_LowSOCWakeup : 30|1@0+ (1,0) [0|1] ""  PDCM,EPB,GW
 SG_ LBMS_NMReq_RechrgWakeup : 31|1@0+ (1,0) [0|1] ""  PDCM,EPB,GW

BO_ 1614 NM_GW_PT: 8 GW
 SG_ GW_PT_RMR : 8|1@0+ (1,0) [0|1] ""  PDCM,EPB,LBMS
 SG_ GW_PT_AWB : 12|1@0+ (1,0) [0|1] ""  PDCM,EPB,LBMS

BO_ 992 GW_LIN_INFO: 8 GW
 SG_ ssm_ssPosition : 5|3@0+ (1,0) [0|7] ""  Vector__XXX
 SG_ srm_srOpenPosition : 14|7@0+ (1,0) [0|100] ""  Vector__XXX
 SG_ ssm_ssOpenPosition : 22|7@0+ (1,0) [0|100] ""  Vector__XXX

BO_ 2015 DiagReq_FUN: 8 GW
 SG_ FUN_DiagReq : 7|64@0+ (1,0) [0|1] ""  PDCM,EPB,LBMS

BO_ 1841 DiagReq_PDCM: 8 GW
 SG_ PDCM_DiagReq : 7|64@0+ (1,0) [0|1] ""  PDCM

BO_ 1969 DiagResp_PDCM: 8 PDCM
 SG_ PDCM_DiagResp : 7|64@0+ (1,0) [0|1] ""  GW

BO_ 2018 DiagReq_PDCM_OBD: 8 GW
 SG_ PDCM_DiagReq_OBD : 7|64@0+ (1,0) [0|1] ""  PDCM

BO_ 2026 DiagResp_PDCM_OBD: 8 PDCM
 SG_ PDCM_DiagResp_OBD : 7|64@0+ (1,0) [0|1] ""  GW

BO_ 1802 DiagReq_EPB_PT: 8 GW
 SG_ EPB_DiagReq_PT : 7|64@0+ (1,0) [0|1] ""  EPB

BO_ 1930 DiagResp_EPB_PT: 8 EPB
 SG_ EPB_DiagResp_PT : 7|64@0+ (1,0) [0|1] ""  GW

BO_ 2021 DiagReq_BMS: 8 GW
 SG_ BMS_DiagReq : 7|64@0+ (1,0) [0|1] ""  PDCM

BO_ 2029 DiagResp_BMS: 8 PDCM
 SG_ BMS_DiagResp : 7|64@0+ (1,0) [0|1] ""  GW

BO_ 1847 DiagReq_OBC1: 8 GW
 SG_ OBC1_DiagReq : 7|64@0+ (1,0) [0|1] ""  PDCM

BO_ 1975 DiagResp_OBC1: 8 PDCM
 SG_ OBC1_DiagResp : 7|64@0+ (1,0) [0|1] ""  GW

BO_ 2019 DiagReq_MCUF: 8 GW
 SG_ MCUF_DiagReq : 7|64@0+ (1,0) [0|1] ""  PDCM

BO_ 2027 DiagResp_MCUF: 8 PDCM
 SG_ MCUF_DiagResp : 7|64@0+ (1,0) [0|1] ""  GW

BO_ 2020 DiagReq_MCUR: 8 GW
 SG_ MCUR_DiagReq : 7|64@0+ (1,0) [0|1] ""  PDCM

BO_ 2028 DiagResp_MCUR: 8 PDCM
 SG_ MCUR_DiagResp : 7|64@0+ (1,0) [0|1] ""  GW

BO_ 2016 DiagReq_EMS: 8 GW
 SG_ EMS_DiagReq : 7|64@0+ (1,0) [0|1] ""  PDCM

BO_ 2024 DiagResp_EMS: 8 PDCM
 SG_ PEMS_DiagResp : 7|64@0+ (1,0) [0|1] ""  GW

BO_ 2022 DiagReq_GCU: 8 GW
 SG_ GCU_DiagReq : 7|64@0+ (1,0) [0|1] ""  PDCM

BO_ 2030 DiagResp_GCU: 8 PDCM
 SG_ GCU_DiagResp : 7|64@0+ (1,0) [0|1] ""  GW

BO_ 2017 DiagReq_TCU: 8 GW
 SG_ TCU_DiagReq : 7|64@0+ (1,0) [0|1] ""  PDCM

BO_ 2025 DiagResp_TCU: 8 PDCM
 SG_ TCU_DiagResp : 7|64@0+ (1,0) [0|1] ""  GW

BO_ 1817 DiagReq_SWM: 8 GW
 SG_ SWM_DiagReq : 7|64@0+ (1,0) [0|1] ""  PDCM

BO_ 1945 DiagResp_SWM: 8 PDCM
 SG_ SWM_DiagResp : 7|64@0+ (1,0) [0|1] ""  GW

BO_ 1870 DiagReq_LBMS: 8 GW
 SG_ LBMS_DiagReq : 7|64@0+ (1,0) [0|1] ""  LBMS

BO_ 1998 DiagResp_LBMS: 8 LBMS
 SG_ LBMS_DiagResp : 7|64@0+ (1,0) [0|1] ""  GW

CM_ SG_ 931 BMS_ProbeTemp31 "探针31温度值";
CM_ SG_ 931 BMS_ProbeTemp32 "探针32温度值";
CM_ SG_ 933 BMS_ProbeTemp33 "探针33温度值";
CM_ SG_ 933 BMS_ProbeTemp34 "探针34温度值";
CM_ SG_ 933 BMS_ProbeTemp35 "探针35温度值";
CM_ SG_ 933 BMS_ProbeTemp36 "探针36温度值";
CM_ SG_ 933 BMS_ProbeTemp37 "探针37温度值";
CM_ SG_ 933 BMS_ProbeTemp38 "探针38温度值";
CM_ SG_ 933 BMS_ProbeTemp39 "探针39温度值";
CM_ SG_ 933 BMS_ProbeTemp40 "探针40温度值";
CM_ SG_ 935 BMS_ProbeTemp41 "探针41温度值";
CM_ SG_ 935 BMS_ProbeTemp42 "探针42温度值";
CM_ SG_ 935 BMS_ProbeTemp43 "探针43温度值";
CM_ SG_ 935 BMS_ProbeTemp44 "探针44温度值";
CM_ SG_ 935 BMS_ProbeTemp45 "探针45温度值";
CM_ SG_ 935 BMS_ProbeTemp46 "探针46温度值";
CM_ SG_ 935 BMS_ProbeTemp47 "探针47温度值";
CM_ SG_ 935 BMS_ProbeTemp48 "探针48温度值";
CM_ SG_ 940 BMS_BattCellVolt1 "单体1电压";
CM_ SG_ 940 BMS_BattCellVolt2 "单体2电压";
CM_ SG_ 940 BMS_BattCellVolt3 "单体3电压";
CM_ SG_ 940 BMS_BattCellVolt4 "单体4电压";
CM_ SG_ 939 BMS_BattCellVolt5 "单体5电压";
CM_ SG_ 939 BMS_BattCellVolt6 "单体6电压";
CM_ SG_ 939 BMS_BattCellVolt7 "单体7电压";
CM_ SG_ 939 BMS_BattCellVolt8 "单体8电压";
CM_ SG_ 943 BMS_BattCellVolt9 "单体9电压";
CM_ SG_ 943 BMS_BattCellVolt10 "单体10电压";
CM_ SG_ 943 BMS_BattCellVolt11 "单体11电压";
CM_ SG_ 943 BMS_BattCellVolt12 "单体12电压";
CM_ SG_ 942 BMS_BattCellVolt13 "单体13电压";
CM_ SG_ 942 BMS_BattCellVolt14 "单体14电压";
CM_ SG_ 942 BMS_BattCellVolt15 "单体15电压";
CM_ SG_ 942 BMS_BattCellVolt16 "单体16电压";
CM_ SG_ 945 BMS_BattCellVolt17 "单体17电压";
CM_ SG_ 945 BMS_BattCellVolt18 "单体18电压";
CM_ SG_ 945 BMS_BattCellVolt19 "单体19电压";
CM_ SG_ 945 BMS_BattCellVolt20 "单体20电压";
CM_ SG_ 947 BMS_BattCellVolt21 "单体21电压";
CM_ SG_ 947 BMS_BattCellVolt22 "单体22电压";
CM_ SG_ 947 BMS_BattCellVolt23 "单体23电压";
CM_ SG_ 947 BMS_BattCellVolt24 "单体24电压";
CM_ SG_ 948 BMS_BattCellVolt25 "单体25电压";
CM_ SG_ 948 BMS_BattCellVolt26 "单体26电压";
CM_ SG_ 948 BMS_BattCellVolt27 "单体27电压";
CM_ SG_ 948 BMS_BattCellVolt28 "单体28电压";
CM_ SG_ 951 BMS_BattCellVolt29 "单体29电压";
CM_ SG_ 951 BMS_BattCellVolt30 "单体30电压";
CM_ SG_ 951 BMS_BattCellVolt31 "单体31电压";
CM_ SG_ 951 BMS_BattCellVolt32 "单体32电压";
CM_ SG_ 953 BMS_BattCellVolt33 "单体33电压";
CM_ SG_ 953 BMS_BattCellVolt34 "单体34电压";
CM_ SG_ 953 BMS_BattCellVolt35 "单体35电压";
CM_ SG_ 953 BMS_BattCellVolt36 "单体36电压";
CM_ SG_ 954 BMS_BattCellVolt37 "单体37电压";
CM_ SG_ 954 BMS_BattCellVolt38 "单体38电压";
CM_ SG_ 954 BMS_BattCellVolt39 "单体39电压";
CM_ SG_ 954 BMS_BattCellVolt40 "单体40电压";
CM_ SG_ 956 BMS_BattCellVolt41 "单体41电压";
CM_ SG_ 956 BMS_BattCellVolt42 "单体42电压";
CM_ SG_ 956 BMS_BattCellVolt43 "单体43电压";
CM_ SG_ 956 BMS_BattCellVolt44 "单体44电压";
CM_ SG_ 958 BMS_BattCellVolt45 "单体45电压";
CM_ SG_ 958 BMS_BattCellVolt46 "单体46电压";
CM_ SG_ 958 BMS_BattCellVolt47 "单体47电压";
CM_ SG_ 958 BMS_BattCellVolt48 "单体48电压";
CM_ SG_ 959 BMS_BattCellVolt49 "单体49电压";
CM_ SG_ 959 BMS_BattCellVolt50 "单体50电压";
CM_ SG_ 959 BMS_BattCellVolt51 "单体51电压";
CM_ SG_ 959 BMS_BattCellVolt52 "单体52电压";
CM_ SG_ 961 BMS_BattCellVolt53 "单体53电压";
CM_ SG_ 961 BMS_BattCellVolt54 "单体54电压";
CM_ SG_ 961 BMS_BattCellVolt55 "单体55电压";
CM_ SG_ 961 BMS_BattCellVolt56 "单体56电压";
CM_ SG_ 963 BMS_BattCellVolt57 "单体57电压";
CM_ SG_ 963 BMS_BattCellVolt58 "单体58电压";
CM_ SG_ 963 BMS_BattCellVolt59 "单体59电压";
CM_ SG_ 963 BMS_BattCellVolt60 "单体60电压";
CM_ SG_ 965 BMS_BattCellVolt61 "单体61电压";
CM_ SG_ 965 BMS_BattCellVolt62 "单体62电压";
CM_ SG_ 965 BMS_BattCellVolt63 "单体63电压";
CM_ SG_ 965 BMS_BattCellVolt64 "单体64电压";
CM_ SG_ 967 BMS_BattCellVolt65 "单体65电压";
CM_ SG_ 967 BMS_BattCellVolt66 "单体66电压";
CM_ SG_ 967 BMS_BattCellVolt67 "单体67电压";
CM_ SG_ 967 BMS_BattCellVolt68 "单体68电压";
CM_ SG_ 969 BMS_BattCellVolt69 "单体69电压";
CM_ SG_ 969 BMS_BattCellVolt70 "单体70电压";
CM_ SG_ 969 BMS_BattCellVolt71 "单体71电压";
CM_ SG_ 969 BMS_BattCellVolt72 "单体72电压";
CM_ SG_ 970 BMS_BattCellVolt73 "单体73电压";
CM_ SG_ 970 BMS_BattCellVolt74 "单体74电压";
CM_ SG_ 970 BMS_BattCellVolt75 "单体75电压";
CM_ SG_ 970 BMS_BattCellVolt76 "单体76电压";
CM_ SG_ 972 BMS_BattCellVolt77 "单体77电压";
CM_ SG_ 972 BMS_BattCellVolt78 "单体78电压";
CM_ SG_ 972 BMS_BattCellVolt79 "单体79电压";
CM_ SG_ 972 BMS_BattCellVolt80 "单体80电压";
CM_ SG_ 974 BMS_BattCellVolt81 "单体81电压";
CM_ SG_ 974 BMS_BattCellVolt82 "单体82电压";
CM_ SG_ 974 BMS_BattCellVolt83 "单体83电压";
CM_ SG_ 974 BMS_BattCellVolt84 "单体84电压";
CM_ SG_ 975 BMS_BattCellVolt85 "单体85电压";
CM_ SG_ 975 BMS_BattCellVolt86 "单体86电压";
CM_ SG_ 975 BMS_BattCellVolt87 "单体87电压";
CM_ SG_ 975 BMS_BattCellVolt88 "单体88电压";
CM_ SG_ 977 BMS_BattCellVolt89 "单体89电压";
CM_ SG_ 977 BMS_BattCellVolt90 "单体90电压";
CM_ SG_ 977 BMS_BattCellVolt91 "单体91电压";
CM_ SG_ 977 BMS_BattCellVolt92 "单体92电压";
CM_ SG_ 979 BMS_BattCellVolt93 "单体93电压";
CM_ SG_ 979 BMS_BattCellVolt94 "单体94电压";
CM_ SG_ 979 BMS_BattCellVolt95 "单体95电压";
CM_ SG_ 979 BMS_BattCellVolt96 "单体96电压";
CM_ SG_ 981 BMS_BattCellVolt97 "单体97电压";
CM_ SG_ 981 BMS_BattCellVolt98 "单体98电压";
CM_ SG_ 981 BMS_BattCellVolt99 "单体99电压";
CM_ SG_ 981 BMS_BattCellVolt100 "单体100电压";
CM_ SG_ 984 BMS_BattCellVolt101 "单体101电压";
CM_ SG_ 984 BMS_BattCellVolt102 "单体102电压";
CM_ SG_ 984 BMS_BattCellVolt103 "单体103电压";
CM_ SG_ 984 BMS_BattCellVolt104 "单体104电压";
CM_ SG_ 989 BMS_BattCellVolt105 "单体105电压";
CM_ SG_ 989 BMS_BattCellVolt106 "单体106电压";
CM_ SG_ 989 BMS_BattCellVolt107 "单体107电压";
CM_ SG_ 989 BMS_BattCellVolt108 "单体108电压";
CM_ SG_ 986 BMS_BattCellVolt109 "单体109电压";
CM_ SG_ 986 BMS_BattCellVolt110 "单体110电压";
CM_ SG_ 986 BMS_BattCellVolt111 "单体111电压";
CM_ SG_ 986 BMS_BattCellVolt112 "单体112电压";
CM_ SG_ 1220 PDCM_BattEnergyAvaliable "电池可用能量";
CM_ SG_ 1220 PDCM_oilRemainingValue "剩余油量";
CM_ SG_ 1220 PDCM_oilPercent "剩余油量百分比";
CM_ SG_ 1220 PDCM_oilPercentFail "油量百分比错误";
CM_ SG_ 1221 PDCM_remainingMileageOil_Standard "燃油剩余公告续航";
CM_ SG_ 1221 PDCM_remainingMileageOil_Real "燃油剩余真实续航";
CM_ SG_ 1222 PDCM_TripADistance "自启动起行驶里程";
CM_ SG_ 1222 PDCM_TripAAvgPwrConsum "TripA平均电耗";
CM_ SG_ 1222 PDCM_TripAAvgSpeed "TripA平均车速";
CM_ SG_ 1222 PDCM_TripAAvgOilConsum "TripA平均油耗";
CM_ SG_ 1222 PDCM_TripALastingTime "TripA行驶时间";
CM_ SG_ 1222 PDCM_TripAOilDistance "小计里程A燃油行驶里程";
CM_ SG_ 1222 PDCM_TripAPwrDistance "小计里程A纯电行驶里程";
CM_ SG_ 1223 PDCM_totalMilAvgPwrConsum "总里程平均电耗";
CM_ SG_ 1223 PDCM_totalMilAvgSpd "总里程平均车速";
CM_ SG_ 1223 PDCM_totalMilAvgOilConsum "总里程平均油耗";
CM_ SG_ 1223 PDCM_totalMilLastingTime "总里程行驶时间";
CM_ SG_ 1224 PDCM_CurrentTripDistance "自启动起行驶里程";
CM_ SG_ 1224 PDCM_CurrentTripAvgPwrConsum "自启动平均电耗";
CM_ SG_ 1224 PDCM_CurrentTripAvgSpd "自启动平均车速";
CM_ SG_ 1224 PDCM_CurrentTripAvgOilConsum "自启动平均油耗";
CM_ SG_ 1224 PDCM_CurrentTripLastingTime "自启动起行驶时间";
CM_ SG_ 1225 PDCM_SinceChargeDistance "自充电起行驶里程";
CM_ SG_ 1225 PDCM_SinceChargeAvgPwrConsum "自上次充电平均电耗";
CM_ SG_ 1225 PDCM_SinceChargeAvgSpd "自上次充电平均车速";
CM_ SG_ 1225 PDCM_SinceChargeAvgOilConsum "自启动平均油耗";
CM_ SG_ 1225 PDCM_SinceChargeTime "自上次充电行驶时间";
CM_ SG_ 1226 PDCM_SinceRefulDistance "自加油起行驶里程";
CM_ SG_ 1226 PDCM_SinceRefulAvgPwrConsum "自加油起平均电耗";
CM_ SG_ 1226 PDCM_SinceRefulAvgSpd "自加油起平均车速";
CM_ SG_ 1226 PDCM_SinceRefulAvgOilConsum "自加油起平均油耗";
CM_ SG_ 1226 PDCM_SinceRefulLastingTime "自加油起行驶时间";
CM_ SG_ 1227 PDCM_CurrentTripDrvCnsPer "自启动驱动能耗占比";
CM_ SG_ 1227 PDCM_CurrentTripCabinSoftCnsPer "自启动空调能耗占比";
CM_ SG_ 1227 PDCM_CurrentTripEleCnsPer "自启动电器能耗占比";
CM_ SG_ 1227 PDCM_CurrentTripFuelCnsPer "自启动燃油发电能耗占比";
CM_ SG_ 1227 PDCM_CurrentTripV2LCnsPer "自启动对外放电能耗占比";
CM_ SG_ 1227 PDCM_CurrentTripOthCnsPer "自启动其他能耗占比";
CM_ SG_ 1228 PDCM_SinceChargeDrvCnsPer "自充电驱动能耗占比";
CM_ SG_ 1228 PDCM_SinceChargeCabinSoftCnsPer "自充电空调能耗占比";
CM_ SG_ 1228 PDCM_SinceChargeEleCnsPer "自充电电器能耗占比";
CM_ SG_ 1228 PDCM_SinceChargeFuelCnsPer "自充电燃油发电能耗占比";
CM_ SG_ 1228 PDCM_SinceChargeV2LCnsPer "自充电对外放电能耗占比";
CM_ SG_ 1228 PDCM_SinceChargeOthCnsPer "自充电其他能耗占比";
CM_ SG_ 1228 PDCM_SinceChargeEVCnsPer "自充电纯电工况占比";
CM_ SG_ 1229 PDCM_SinceRefulDrvCnsPer "自加油驱动能耗占比";
CM_ SG_ 1229 PDCM_SinceRefulCabinSoftCnsPer "自加油空调能耗占比";
CM_ SG_ 1229 PDCM_SinceRefulEleCnsPer "自加油电器能耗占比";
CM_ SG_ 1229 PDCM_SinceRefulFuelCnsPer "自加油燃油发电能耗占比";
CM_ SG_ 1229 PDCM_SinceRefulV2LCnsPer "自加油对外放电能耗占比";
CM_ SG_ 1229 PDCM_SinceRefulOthCnsPer "自加油其他能耗占比";
CM_ SG_ 1229 PDCM_SinceRefulSeriCnsPer "自加油增程工况占比";
CM_ SG_ 1229 PDCM_SinceRefulParalCnsPer "自加油直驱工况占比";
CM_ SG_ 1230 PDCM_SinceTripADrvCnsPer "小计里程A驱动能耗占比";
CM_ SG_ 1230 PDCM_SinceTripACabinSoftCnsPer "小计里程A空调能耗占比";
CM_ SG_ 1230 PDCM_SinceTripAEleCnsPer "小计里程A电器能耗占比";
CM_ SG_ 1230 PDCM_SinceTripAFuelCnsPer "小计里程A燃油发电能耗占比";
CM_ SG_ 1230 PDCM_SinceTripAV2LCnsPer "小计里程A对外放电能耗占比";
CM_ SG_ 1230 PDCM_SinceTripAOthCnsPer "小计里程A其他能耗占比";
CM_ SG_ 1230 PDCM_SinceTripAEVCnsPer "小计里程A纯电工况占比";
CM_ SG_ 1230 PDCM_SinceTripASeriCnsPer "小计里程A增程工况占比";
CM_ SG_ 1230 PDCM_SinceTripAParalCnsPer "小计里程A直驱工况占比";
CM_ SG_ 1231 PDCM_DayAvgOilConsum "当日平均油耗";
CM_ SG_ 1231 PDCM_DayAvgPwrConsum "当日平均电耗";
CM_ SG_ 1232 PDCM_ConsumpRatioInstantDrv "瞬时电耗动态";
CM_ SG_ 1232 PDCM_ConsumpRatioInstantSt "瞬时电耗静态";
CM_ SG_ 1232 PDCM_FuelConsumpDrv "瞬时油耗动态";
CM_ SG_ 1232 PDCM_FuelConsumpSt "瞬时油耗静态";
CM_ SG_ 1233 PDCM_totalMileage "总里程";
CM_ SG_ 1233 PDCM_totalMileageValid "总里程有效";
CM_ SG_ 1233 PDCM_totalMileageRev "发动机运行总里程";
CM_ SG_ 1253 PDCM_ChargingSpeed_Standard "标准工况充电速度";
CM_ SG_ 1253 PDCM_ChargingSpeed_Real "真实工况充电速度";
CM_ SG_ 1253 PDCM_RemainingMileageIncrement_Standard "标准工况纯电续航增量";
CM_ SG_ 1253 PDCM_RemainingMileageIncrement_Real "真实工况纯电续航增量";
CM_ SG_ 1253 PDCM_SOCLowAlarmLamp "动力电池SOC低报警（仅H56C适用）";
CM_ SG_ 791 PDCM_DischargeCurrent "V2X（V2L/V2V/V2G/V2C）放电电流";
CM_ SG_ 791 PDCM_DischargeVoltage "V2X（V2L/V2V/V2G/V2C）放电电压";
CM_ SG_ 791 PDCM_DischargePower "V2X（V2L/V2V/V2G/V2C）放电功率";
CM_ SG_ 791 PDCM_DischargeEnergy_Total "V2X（V2L/V2V/V2G/V2C）累计放电电量";
CM_ SG_ 791 PDCM_DischargeOverCurrent_Warn "V2X（V2L/V2V/V2G/V2C）放电过流状态";
CM_ SG_ 792 PDCM_ExternalLoadPwr "附件总功率";
CM_ SG_ 1242 IC_FuelConsump "瞬时油耗";
CM_ SG_ 1242 IC_ConsumpRatioInstant "瞬时电耗";
CM_ SG_ 1242 ic_oilPercent "Oil tank percent
 0xFF: SENSOR_FAULT_OIL";
CM_ SG_ 1242 IC_OilRemainingMileage "燃油续航里程（增程车）";
CM_ SG_ 1242 IC_OilSensorResistance "oil sensor resistance";
CM_ SG_ 1242 ic_oilPercentFail "oil percent sensor error.";
CM_ SG_ 837 LBMS_CellU1 "电芯电压1";
CM_ SG_ 837 LBMS_CellU2 "电芯电压2";
CM_ SG_ 837 LBMS_CellU3 "电芯电压3";
CM_ SG_ 837 LBMS_CellU4 "电芯电压4";
CM_ SG_ 837 LBMS_Cell1UVld "单体1电压是否有效";
CM_ SG_ 837 LBMS_Cell2UVld "单体2电压是否有效";
CM_ SG_ 837 LBMS_Cell3UVld "单体3电压是否有效";
CM_ SG_ 837 LBMS_Cell4UVld "单体4电压是否有效";
CM_ SG_ 837 LBMS_PackCurrent "电池电流(充电为正，放电为负)";
CM_ SG_ 837 LBMS_PackIntU "电芯总压(MOS内侧电压)";
CM_ SG_ 837 LBMS_PackExtU "Pack电压(MOS外侧电压)";
CM_ SG_ 837 LBMS_PackIntUVld "电芯总压是否有效";
CM_ SG_ 837 LBMS_PackExtUVld "Pack电压是否有效";
CM_ SG_ 837 LBMS_PackT1 "Pack温度1";
CM_ SG_ 837 LBMS_PackT2 "Pack温度2";
CM_ SG_ 837 LBMS_PackT3 "Pack温度3";
CM_ SG_ 837 LBMS_PackT1Vld "Pack温度1是否有效";
CM_ SG_ 837 LBMS_DisMOSReq "锁电断MOS提示";
CM_ SG_ 837 LBMS_PackIntUCal "电池4个单体电压计算累计值";
CM_ SG_ 837 LBMS_PackIntUCalVld "电池4个单体电压计算累计值是否有效";
CM_ SG_ 837 LBMS_PackCurrentVld "电池电流是否有效";
CM_ SG_ 837 LBMS_AHChrgTotlife "整个生命周期充电AH数";
CM_ SG_ 837 LBMS_AHDisChrgTotlife "整个生命周期放电AH数";
CM_ SG_ 837 LBMS_AHChrgVld "整个生命周期充电AH数是否有效";
CM_ SG_ 837 LBMS_AHDisChrgVld "整个生命周期充电AH数是否有效";
CM_ SG_ 837 LBMS_PackT2Vld "Pack温度2是否有效";
CM_ SG_ 837 LBMS_PackT3Vld "Pack温度3是否有效";
CM_ SG_ 837 LBMS_DischrgMOST "放电MOS温度";
CM_ SG_ 837 LBMS_ChrgCMOST "充电MOS温度";
CM_ SG_ 837 LBMS_BalanceTemp "均衡温度";
CM_ SG_ 837 LBMS_BuckT "限流模块温度";
CM_ SG_ 838 LBMS_SOCVld "SOC是否有效";
CM_ SG_ 838 LBMS_SOH "SOH";
CM_ SG_ 838 LBMS_ChrgMosSt "充电MOS状态";
CM_ SG_ 838 LBMS_DischrgMosSt "放电MOS状态";
CM_ SG_ 838 LBMS_BuckStatus "充电BUCK状态";
CM_ SG_ 838 LBMS_ReChrgReq "低压蓄电池补电请求";
CM_ SG_ 838 LBMS_WorkSt "低压电池工作状态";
CM_ SG_ 838 LBMS_RealSOC "真实SOC";
CM_ SG_ 838 LBMS_MOSForcedControlSt "MOS强控状态";
CM_ SG_ 838 LBMS_MaxAllwChrgU "最大允许的充电电压（安全值）";
CM_ SG_ 838 LBMS_ReqChrgU "充电请求电压";
CM_ SG_ 838 LBMS_MaxAllwChrgCurrent "最大允许的充电电流(5S)";
CM_ SG_ 838 LBMS_MaxAllwDischrgCurrent "最大允许的放电电流(5S)";
CM_ SG_ 838 LBMS_Cell1BalSt "电芯1均衡状态";
CM_ SG_ 838 LBMS_Cell2BalSt "电芯2均衡状态";
CM_ SG_ 838 LBMS_Cell3BalSt "电芯3均衡状态";
CM_ SG_ 838 LBMS_Cell4BalSt "电芯4均衡状态";
CM_ SG_ 838 LBMS_SOCCalMod "本次SOC校准方式";
CM_ SG_ 838 LBMS_LowSOCWakeupThre "低SOC请求补电的阈值反馈";
CM_ SG_ 838 LBMS_LowUWakeupThre "低压请求补电电压的阈值反馈";
CM_ SG_ 838 LBMS_ChrgReqCounter "24小时内LBMS请求补电的次数";
CM_ SG_ 838 LBMS_ChargMOSDriU "充电MOS驱动电压";
CM_ SG_ 838 LBMS_DisChargMOSDriU "放电MOS驱动电压";
CM_ SG_ 838 LBMS_SOC "SOC";
CM_ SG_ 838 RollingCounter346 "every message increments the counter.";
CM_ SG_ 838 Checksum346 "CRC8, message checksum.";
CM_ SG_ 630 SentryModeSt "哨兵模式状态";
CM_ SG_ 630 MDC_HighvolReq "表示MDC请求上电高压，MDC唤醒SOC后会请求高压上电（Request），避免蓄电池馈电；MDC休眠SOC后停止请求高压上电（NO Request）";
CM_ SG_ 630 MDC_SysState "MDC唤醒后反馈系统状态";
CM_ SG_ 630 MDC_CoolantfluidReq "表示MDC有液冷需求，MDC在SOC运行状态会发送液冷需求，整车基于该信号维持液冷输出";
CM_ SG_ 630 MDC_CoolingfluidflowRate "MDC启动后，根据单板温度请求冷却液流速";
CM_ SG_ 630 Mdc_ReadyReq "MDC泊车上下ready请求";
CM_ SG_ 630 Mdc_PwrOnOffReq "MDC泊车上下电请求";
CM_ SG_ 630 RollingCounter_271 "every message increments the counter.";
CM_ SG_ 630 Checksum_271 "CRC8, message checksum.";
CM_ SG_ 1585 PDCM_PT_RMR "Repeat Message Request";
CM_ SG_ 1585 PDCM_PT_AWB "Active Wakeup Bit";
CM_ SG_ 1616 EPB_PT_RMR "Repeat Message Request";
CM_ SG_ 1616 EPB_PT_AWB "Active Wakeup Bit";
CM_ SG_ 1642 LBMS_SNID "源节点ID";
CM_ SG_ 1642 LBMS_RMR "Repeat Message Request
重复报文请求位";
CM_ SG_ 1642 LBMS_AWB "Active Wakeup Bit
主动唤醒标志位";
CM_ SG_ 1642 LBMS_RepeatSts "重复报文状态";
CM_ SG_ 1642 LBMS_NMReq_NM "因被NM报文唤醒请求网络";
CM_ SG_ 1642 LBMS_NMReq_Diag "因诊断请求网络";
CM_ SG_ 1642 LBMS_NMReq_Poweron "因唤醒硬线ON请求网络";
CM_ SG_ 1642 LBMS_NMReq_LowSOCWakeup "因LBMS断电处理功能需求请求网络";
CM_ SG_ 1642 LBMS_NMReq_RechrgWakeup "因智能补电需求唤醒请求网络";
CM_ SG_ 1614 GW_PT_RMR "Repeat Message Request";
CM_ SG_ 1614 GW_PT_AWB "Active Wakeup Bit";
CM_ SG_ 992 ssm_ssPosition "Sunshade status.";
CM_ SG_ 992 srm_srOpenPosition "valid value from 0 to 100,which means 0~100%";
CM_ SG_ 992 ssm_ssOpenPosition "valid value from 0 to 100,which means 0~100%";
CM_ SG_ 2015 FUN_DiagReq "Diagnostic request";
CM_ SG_ 1841 PDCM_DiagReq "Diagnostic request";
CM_ SG_ 1969 PDCM_DiagResp "Diagnostic response";
CM_ SG_ 2018 PDCM_DiagReq_OBD "Diagnostic request";
CM_ SG_ 2026 PDCM_DiagResp_OBD "Diagnostic response";
CM_ SG_ 1802 EPB_DiagReq_PT "Diagnostic request";
CM_ SG_ 1930 EPB_DiagResp_PT "Diagnostic response";
CM_ SG_ 2021 BMS_DiagReq "Diagnostic request";
CM_ SG_ 2029 BMS_DiagResp "Diagnostic response";
CM_ SG_ 1847 OBC1_DiagReq "Diagnostic request";
CM_ SG_ 1975 OBC1_DiagResp "Diagnostic response";
CM_ SG_ 2019 MCUF_DiagReq "Diagnostic request";
CM_ SG_ 2027 MCUF_DiagResp "Diagnostic response";
CM_ SG_ 2020 MCUR_DiagReq "Diagnostic request";
CM_ SG_ 2028 MCUR_DiagResp "Diagnostic response";
CM_ SG_ 2016 EMS_DiagReq "Diagnostic request";
CM_ SG_ 2024 PEMS_DiagResp "Diagnostic response";
CM_ SG_ 2022 GCU_DiagReq "Diagnostic request";
CM_ SG_ 2030 GCU_DiagResp "Diagnostic response";
CM_ SG_ 2017 TCU_DiagReq "Diagnostic request";
CM_ SG_ 2025 TCU_DiagResp "Diagnostic response";
CM_ SG_ 1817 SWM_DiagReq "Diagnostic request";
CM_ SG_ 1945 SWM_DiagResp "Diagnostic response";
CM_ SG_ 1870 LBMS_DiagReq "Diagnostic request";
CM_ SG_ 1998 LBMS_DiagResp "Diagnostic response";

BA_DEF_ BO_  "NmMessage" ENUM "No","Yes";
BA_DEF_ BO_  "DiagState" ENUM  "No","Yes";
BA_DEF_ BO_  "GenMsgSendType" ENUM  "Cyclic","Event","IfActive","CE","CA","NoMsgSendType";
BA_DEF_ BO_  "GenMsgCycleTime" INT 0 0;
BA_DEF_ SG_  "GenSigSendType" ENUM  "Cyclic","OnChange","OnWrite","IfActive","OnChangeWithRepetition","OnWriteWithRepetition","IfActiveWithRepetition","NoSigSendType","OnChangeAndIfActive","OnChangeAndIfActiveWithRepetition","CA","CE","Event";
BA_DEF_ SG_  "GenSigStartValue" INT 0 0;
BA_DEF_ SG_  "GenSigInactiveValue" INT 0 0;
BA_DEF_ BO_  "GenMsgCycleTimeFast" INT 0 0;
BA_DEF_ BO_  "GenMsgNrOfRepetition" INT 0 0;
BA_DEF_ BO_  "GenMsgDelayTime" INT 0 0;
BA_DEF_ BO_  "CANFD_BRS" ENUM  "0","1";
BA_DEF_ BO_  "VFrameFormat" ENUM  "StandardCAN","ExtendedCAN","reserved","reserved","reserved","reserved","reserved","reserved","reserved","reserved","reserved","reserved","reserved","reserved","StandardCAN_FD","ExtendedCAN_FD";
BA_DEF_DEF_  "NmMessage" "No";
BA_DEF_DEF_  "DiagState" "No";
BA_DEF_DEF_  "GenMsgSendType" "Cyclic";
BA_DEF_DEF_  "GenMsgCycleTime" 0;
BA_DEF_DEF_  "GenSigSendType" "Cyclic";
BA_DEF_DEF_  "GenSigStartValue" 0;
BA_DEF_DEF_  "GenSigInactiveValue" 0;
BA_DEF_DEF_  "GenMsgCycleTimeFast" 0;
BA_DEF_DEF_  "GenMsgNrOfRepetition" 0;
BA_DEF_DEF_  "GenMsgDelayTime" 0;
BA_DEF_DEF_  "CANFD_BRS" "1";
BA_DEF_DEF_  "VFrameFormat" "StandardCAN_FD";
BA_ "GenMsgCycleTime" BO_ 734 50;
BA_ "GenMsgCycleTime" BO_ 731 100;
BA_ "GenMsgCycleTime" BO_ 747 100;
BA_ "GenMsgCycleTime" BO_ 748 100;
BA_ "GenMsgCycleTime" BO_ 1238 20;
BA_ "GenSigStartValue" SG_ 1238 ic_totalMileage 16777214;
BA_ "GenSigStartValue" SG_ 1238 ic_RemainingMileage 1023;
BA_ "GenMsgSendType" BO_ 1234 3;
BA_ "GenMsgCycleTime" BO_ 1234 100;
BA_ "CANFD_BRS" BO_ 1234 0;
BA_ "VFrameFormat" BO_ 1234 0;
BA_ "GenSigSendType" SG_ 1234 ivi_wcmROnOffSet 4;
BA_ "GenMsgCycleTime" BO_ 896 10;
BA_ "GenSigStartValue" SG_ 896 acu_warningLampSts 1;
BA_ "GenSigStartValue" SG_ 896 acu_crashOutputStsValid 1;
BA_ "GenSigStartValue" SG_ 896 acu_driverSeatBeltStsValid 1;
BA_ "GenSigStartValue" SG_ 896 acu_passengerSeatBeltStsValid 1;
BA_ "GenSigStartValue" SG_ 896 acu_passengerAirbagSts 1;
BA_ "GenMsgCycleTime" BO_ 1041 200;
BA_ "GenMsgCycleTime" BO_ 1057 200;
BA_ "GenMsgCycleTime" BO_ 1239 1000;
BA_ "GenSigStartValue" SG_ 1239 IC_MaintenanceMileage 65534;
BA_ "GenSigStartValue" SG_ 1239 ic_lastingtime 2046;
BA_ "GenSigStartValue" SG_ 1239 ic_mileageSincethelastcharge 16382;
BA_ "GenSigStartValue" SG_ 1239 ic_tripmeterThisMoment 16382;
BA_ "GenMsgCycleTime" BO_ 1235 1000;
BA_ "GenSigStartValue" SG_ 1235 ic_totalMileageRev 16777214;
BA_ "GenMsgCycleTime" BO_ 1022 100;
BA_ "GenSigStartValue" SG_ 1022 ivi_timeInfoDay 1;
BA_ "GenSigStartValue" SG_ 1022 ivi_timeInfoMonth 1;
BA_ "GenSigStartValue" SG_ 1022 ivi_timeValid 1;
BA_ "GenMsgCycleTime" BO_ 117 100;
BA_ "GenSigSendType" SG_ 117 IVI_EVonlymodereq_HW 1;
BA_ "GenSigStartValue" SG_ 117 IVI_V2LMinSocSet 1;
BA_ "GenMsgSendType" BO_ 165 3;
BA_ "GenMsgCycleTime" BO_ 165 100;
BA_ "GenMsgCycleTimeFast" BO_ 165 20;
BA_ "GenMsgNrOfRepetition" BO_ 165 3;
BA_ "GenMsgDelayTime" BO_ 165 20;
BA_ "GenSigSendType" SG_ 165 ivi_maxChargeCurrentSet 4;
BA_ "GenSigSendType" SG_ 165 ivi_RegenModeSet 4;
BA_ "GenSigSendType" SG_ 165 ivi_propModeSet 4;
BA_ "GenSigStartValue" SG_ 165 ivi_maxChrgSocSet 254;
BA_ "GenSigSendType" SG_ 165 ivi_startRevSOCSet 4;
BA_ "GenSigSendType" SG_ 165 ivi_ChargeEndTimeHalfDay 4;
BA_ "GenSigSendType" SG_ 165 ivi_ChargeStartTimeHalfDay 4;
BA_ "GenSigSendType" SG_ 165 ivi_ChargeEndTimeHour 4;
BA_ "GenSigSendType" SG_ 165 ivi_ChargeStartTimeHour 4;
BA_ "GenSigSendType" SG_ 165 ivi_chargeFormSet 4;
BA_ "GenSigSendType" SG_ 165 ivi_ChargeEndTimeMinute 4;
BA_ "GenSigSendType" SG_ 165 ivi_ChargeStartTimeMinute 4;
BA_ "GenSigSendType" SG_ 165 ivi_ChargeEnable 4;
BA_ "GenSigSendType" SG_ 165 ivi_chargeSetValid 4;
BA_ "GenSigSendType" SG_ 165 ivi_ResetCurrentTrip 4;
BA_ "GenSigSendType" SG_ 165 ivi_ChargeEndTimeValid 4;
BA_ "GenSigSendType" SG_ 165 ivi_ChargeStartTimeValid 4;
BA_ "GenSigSendType" SG_ 165 ivi_driveModeSet 4;
BA_ "GenMsgSendType" BO_ 476 3;
BA_ "GenMsgCycleTime" BO_ 476 100;
BA_ "GenMsgCycleTimeFast" BO_ 476 20;
BA_ "GenMsgNrOfRepetition" BO_ 476 3;
BA_ "GenMsgDelayTime" BO_ 476 20;
BA_ "GenSigSendType" SG_ 476 ivi_centralLockCtrl 4;
BA_ "GenSigSendType" SG_ 476 ivi_fuelPortCapOpenCtrl 4;
BA_ "GenSigSendType" SG_ 476 ivi_chrgPortCapOpenCtrl 4;
BA_ "GenSigSendType" SG_ 476 ivi_antiTheftAlarmFormSet 4;
BA_ "GenSigStartValue" SG_ 476 ivi_antiTheftAlarmFormSet 3;
BA_ "GenSigSendType" SG_ 476 ivi_approachingUnlockCtrl 4;
BA_ "GenSigSendType" SG_ 476 ivi_awayLockCtrl 4;
BA_ "GenSigSendType" SG_ 476 ivi_parkAutoCloseDRLCtrl 4;
BA_ "GenSigSendType" SG_ 476 ivi_welcomeSetEnable 4;
BA_ "GenSigSendType" SG_ 476 ivi_welcomeOnOffSet 4;
BA_ "GenSigSendType" SG_ 476 ivi_followMeHomeSet 4;
BA_ "GenSigSendType" SG_ 476 ivi_WiperMaintenanceCtrl 4;
BA_ "GenSigSendType" SG_ 476 ivi_lockAutoCloseWinCtrl 4;
BA_ "GenSigSendType" SG_ 476 IVI_Backlightadjust 4;
BA_ "GenSigSendType" SG_ 476 IVI_Sunroof_HorizontalControl 4;
BA_ "GenSigStartValue" SG_ 476 IVI_Sunroof_HorizontalControl 127;
BA_ "GenSigSendType" SG_ 476 ivi_VehiclePowerOFF 4;
BA_ "GenSigSendType" SG_ 476 ivi_sunroofGlassCmd 4;
BA_ "GenSigSendType" SG_ 476 ivi_sunroofRollshadeCtrlSelect 4;
BA_ "GenSigSendType" SG_ 476 ivi_tailgateCtrl 4;
BA_ "GenSigSendType" SG_ 476 IVI_FLReadLightReq 4;
BA_ "GenSigSendType" SG_ 476 IVI_FRReadLightReq 4;
BA_ "GenSigSendType" SG_ 476 IVI_RLReadLightReq 4;
BA_ "GenSigSendType" SG_ 476 IVI_RReadLightReq 4;
BA_ "GenSigSendType" SG_ 476 IVI_ITLToplampReq 4;
BA_ "GenSigSendType" SG_ 476 ivi_languageSet 4;
BA_ "GenSigStartValue" SG_ 476 ivi_languageSet 3;
BA_ "GenSigSendType" SG_ 476 ivi_unitSet 4;
BA_ "GenSigStartValue" SG_ 476 ivi_unitSet 2;
BA_ "GenSigSendType" SG_ 476 ivi_OutsideLockAlarmFormSet 4;
BA_ "GenMsgCycleTime" BO_ 1240 500;
BA_ "GenSigStartValue" SG_ 1240 ic_tripmeterA 16382;
BA_ "GenSigStartValue" SG_ 1240 ic_tripmeterB 16777214;
BA_ "GenSigStartValue" SG_ 1240 IC_ChargingPower 8190;
BA_ "GenSigStartValue" SG_ 1240 IC_ChargingSpeed 2046;
BA_ "GenMsgCycleTime" BO_ 290 20;
BA_ "GenSigStartValue" SG_ 290 IPB_wheelSpeedRL 8190;
BA_ "GenSigStartValue" SG_ 290 IPB_wheelSpeedRR 8190;
BA_ "GenMsgCycleTime" BO_ 322 20;
BA_ "GenSigStartValue" SG_ 322 IPB_wheelSpeedFL 8190;
BA_ "GenSigStartValue" SG_ 322 IPB_wheelSpeedFR 8190;
BA_ "GenMsgCycleTime" BO_ 160 20;
BA_ "GenSigStartValue" SG_ 160 IPB_vehicleSpeed 8190;
BA_ "GenSigStartValue" SG_ 160 IPB_absFault 1;
BA_ "GenSigStartValue" SG_ 160 IPB_avhAvailable 1;
BA_ "GenSigStartValue" SG_ 160 IPB_ebdFault 1;
BA_ "GenSigStartValue" SG_ 160 IPB_ESCoffSts 1;
BA_ "GenSigStartValue" SG_ 160 IPB_escFault 1;
BA_ "GenMsgCycleTime" BO_ 626 20;
BA_ "GenMsgCycleTime" BO_ 642 20;
BA_ "GenMsgCycleTime" BO_ 1274 1000;
BA_ "GenMsgCycleTime" BO_ 1278 1000;
BA_ "GenMsgCycleTime" BO_ 126 100;
BA_ "GenSigStartValue" SG_ 126 tbox_MaxChargeCurrentSet 63;
BA_ "GenSigStartValue" SG_ 126 tbox_MaxChargeSOCSet 127;
BA_ "GenMsgCycleTime" BO_ 714 100;
BA_ "GenSigStartValue" SG_ 714 OBC_CP_Duty 126;
BA_ "GenSigStartValue" SG_ 714 OBC_CP_Frequency 254;
BA_ "GenMsgCycleTime" BO_ 716 100;
BA_ "GenSigStartValue" SG_ 716 OBC_Frequency_AC 510;
BA_ "GenSigStartValue" SG_ 716 OBC_Max_Current_AC 254;
BA_ "GenSigStartValue" SG_ 716 OBC_AC_Current_L1 1022;
BA_ "GenSigStartValue" SG_ 716 OBC_AC_Current_L2 1022;
BA_ "GenSigStartValue" SG_ 716 OBC_AC_Current_L3 1022;
BA_ "GenMsgCycleTime" BO_ 719 50;
BA_ "GenSigStartValue" SG_ 719 OBC_ActualCurrent_DC 2046;
BA_ "GenSigStartValue" SG_ 719 OBC_ActualVoltage_DC 4094;
BA_ "GenSigStartValue" SG_ 719 OBC_MaxCurrent_Output 2046;
BA_ "GenSigStartValue" SG_ 719 OBC_Efficiency 1022;
BA_ "GenMsgCycleTime" BO_ 736 100;
BA_ "GenSigStartValue" SG_ 736 OBC_AC_Voltage_L1 510;
BA_ "GenSigStartValue" SG_ 736 OBC_AC_Voltage_L2 510;
BA_ "GenSigStartValue" SG_ 736 OBC_AC_Voltage_L3 510;
BA_ "GenSigStartValue" SG_ 736 OBC_Temperature_Internal 254;
BA_ "GenMsgCycleTime" BO_ 738 100;
BA_ "GenSigStartValue" SG_ 738 OBC_Coolant_Temperature 254;
BA_ "GenMsgCycleTime" BO_ 740 100;
BA_ "GenSigStartValue" SG_ 740 DCDC_Voltage_HV 4094;
BA_ "GenSigStartValue" SG_ 740 DCDC_Current_HV 1022;
BA_ "GenSigStartValue" SG_ 740 DCDC_Voltage_LV 254;
BA_ "GenSigStartValue" SG_ 740 DCDC_Current_LV 1022;
BA_ "GenMsgCycleTime" BO_ 865 500;
BA_ "GenSigStartValue" SG_ 865 OBC_AC_PlugTemp_L1 254;
BA_ "GenSigStartValue" SG_ 865 OBC_AC_PlugTemp_L2 254;
BA_ "GenSigStartValue" SG_ 865 OBC_AC_PlugTemp_L3 254;
BA_ "GenSigStartValue" SG_ 865 OBC_AC_PlugTemp_N 254;
BA_ "GenMsgCycleTime" BO_ 888 1000;
BA_ "GenMsgCycleTime" BO_ 889 1000;
BA_ "GenSigStartValue" SG_ 889 BMS_Pack_SN_01 255;
BA_ "GenSigStartValue" SG_ 889 BMS_Pack_SN_02 255;
BA_ "GenSigStartValue" SG_ 889 BMS_Pack_SN_03 255;
BA_ "GenSigStartValue" SG_ 889 BMS_Pack_SN_04 255;
BA_ "GenSigStartValue" SG_ 889 BMS_Pack_SN_05 255;
BA_ "GenSigStartValue" SG_ 889 BMS_Pack_SN_06 255;
BA_ "GenSigStartValue" SG_ 889 BMS_Pack_SN_07 255;
BA_ "GenMsgCycleTime" BO_ 890 1000;
BA_ "GenSigStartValue" SG_ 890 BMS_ChargeEnergy_Total 4294967295;
BA_ "GenSigStartValue" SG_ 890 BMS_ChargeCapacity_Total 4294967295;
BA_ "GenMsgCycleTime" BO_ 922 1000;
BA_ "GenMsgCycleTime" BO_ 923 100;
BA_ "GenSigStartValue" SG_ 923 BMS_Capacity_Max 2046;
BA_ "GenMsgCycleTime" BO_ 927 1000;
BA_ "GenSigStartValue" SG_ 927 BMS_ProbeTemp1 40;
BA_ "GenSigStartValue" SG_ 927 BMS_ProbeTemp2 40;
BA_ "GenSigStartValue" SG_ 927 BMS_ProbeTemp3 40;
BA_ "GenSigStartValue" SG_ 927 BMS_ProbeTemp4 40;
BA_ "GenSigStartValue" SG_ 927 BMS_ProbeTemp5 40;
BA_ "GenSigStartValue" SG_ 927 BMS_ProbeTemp6 40;
BA_ "GenSigStartValue" SG_ 927 BMS_ProbeTemp7 40;
BA_ "GenSigStartValue" SG_ 927 BMS_ProbeTemp8 40;
BA_ "GenMsgCycleTime" BO_ 928 1000;
BA_ "GenSigStartValue" SG_ 928 BMS_ProbeTemp9 40;
BA_ "GenSigStartValue" SG_ 928 BMS_ProbeTemp10 40;
BA_ "GenSigStartValue" SG_ 928 BMS_ProbeTemp11 40;
BA_ "GenSigStartValue" SG_ 928 BMS_ProbeTemp12 40;
BA_ "GenSigStartValue" SG_ 928 BMS_ProbeTemp13 40;
BA_ "GenSigStartValue" SG_ 928 BMS_ProbeTemp14 40;
BA_ "GenSigStartValue" SG_ 928 BMS_ProbeTemp15 40;
BA_ "GenSigStartValue" SG_ 928 BMS_ProbeTemp16 40;
BA_ "GenMsgCycleTime" BO_ 930 1000;
BA_ "GenSigStartValue" SG_ 930 BMS_ProbeTemp17 40;
BA_ "GenSigStartValue" SG_ 930 BMS_ProbeTemp18 40;
BA_ "GenSigStartValue" SG_ 930 BMS_ProbeTemp19 40;
BA_ "GenSigStartValue" SG_ 930 BMS_ProbeTemp20 40;
BA_ "GenSigStartValue" SG_ 930 BMS_ProbeTemp21 40;
BA_ "GenSigStartValue" SG_ 930 BMS_ProbeTemp22 40;
BA_ "GenSigStartValue" SG_ 930 BMS_ProbeTemp23 40;
BA_ "GenSigStartValue" SG_ 930 BMS_ProbeTemp24 40;
BA_ "GenMsgCycleTime" BO_ 931 1000;
BA_ "GenSigStartValue" SG_ 931 BMS_ProbeTemp25 40;
BA_ "GenSigStartValue" SG_ 931 BMS_ProbeTemp26 40;
BA_ "GenSigStartValue" SG_ 931 BMS_ProbeTemp27 40;
BA_ "GenSigStartValue" SG_ 931 BMS_ProbeTemp28 40;
BA_ "GenSigStartValue" SG_ 931 BMS_ProbeTemp29 40;
BA_ "GenSigStartValue" SG_ 931 BMS_ProbeTemp30 40;
BA_ "GenSigStartValue" SG_ 931 BMS_ProbeTemp31 40;
BA_ "GenSigStartValue" SG_ 931 BMS_ProbeTemp32 40;
BA_ "GenMsgCycleTime" BO_ 933 1000;
BA_ "GenSigStartValue" SG_ 933 BMS_ProbeTemp33 40;
BA_ "GenSigStartValue" SG_ 933 BMS_ProbeTemp34 40;
BA_ "GenSigStartValue" SG_ 933 BMS_ProbeTemp35 40;
BA_ "GenSigStartValue" SG_ 933 BMS_ProbeTemp36 40;
BA_ "GenSigStartValue" SG_ 933 BMS_ProbeTemp37 40;
BA_ "GenSigStartValue" SG_ 933 BMS_ProbeTemp38 40;
BA_ "GenSigStartValue" SG_ 933 BMS_ProbeTemp39 40;
BA_ "GenSigStartValue" SG_ 933 BMS_ProbeTemp40 40;
BA_ "GenMsgCycleTime" BO_ 935 1000;
BA_ "GenSigStartValue" SG_ 935 BMS_ProbeTemp41 40;
BA_ "GenSigStartValue" SG_ 935 BMS_ProbeTemp42 40;
BA_ "GenSigStartValue" SG_ 935 BMS_ProbeTemp43 40;
BA_ "GenSigStartValue" SG_ 935 BMS_ProbeTemp44 40;
BA_ "GenSigStartValue" SG_ 935 BMS_ProbeTemp45 40;
BA_ "GenSigStartValue" SG_ 935 BMS_ProbeTemp46 40;
BA_ "GenSigStartValue" SG_ 935 BMS_ProbeTemp47 40;
BA_ "GenSigStartValue" SG_ 935 BMS_ProbeTemp48 40;
BA_ "GenMsgCycleTime" BO_ 940 1000;
BA_ "GenMsgCycleTime" BO_ 939 1000;
BA_ "GenMsgCycleTime" BO_ 943 1000;
BA_ "GenMsgCycleTime" BO_ 942 1000;
BA_ "GenMsgCycleTime" BO_ 945 1000;
BA_ "GenMsgCycleTime" BO_ 947 1000;
BA_ "GenMsgCycleTime" BO_ 948 1000;
BA_ "GenMsgCycleTime" BO_ 951 1000;
BA_ "GenMsgCycleTime" BO_ 953 1000;
BA_ "GenMsgCycleTime" BO_ 954 1000;
BA_ "GenMsgCycleTime" BO_ 956 1000;
BA_ "GenMsgCycleTime" BO_ 958 1000;
BA_ "GenMsgCycleTime" BO_ 959 1000;
BA_ "GenMsgCycleTime" BO_ 961 1000;
BA_ "GenMsgCycleTime" BO_ 963 1000;
BA_ "GenMsgCycleTime" BO_ 965 1000;
BA_ "GenMsgCycleTime" BO_ 967 1000;
BA_ "GenMsgCycleTime" BO_ 969 1000;
BA_ "GenMsgCycleTime" BO_ 970 1000;
BA_ "GenMsgCycleTime" BO_ 972 1000;
BA_ "GenMsgCycleTime" BO_ 974 1000;
BA_ "GenMsgCycleTime" BO_ 975 1000;
BA_ "GenMsgCycleTime" BO_ 977 1000;
BA_ "GenMsgCycleTime" BO_ 979 1000;
BA_ "GenMsgCycleTime" BO_ 981 1000;
BA_ "GenMsgCycleTime" BO_ 984 1000;
BA_ "GenMsgCycleTime" BO_ 989 1000;
BA_ "GenMsgCycleTime" BO_ 986 1000;
BA_ "GenMsgCycleTime" BO_ 1220 100;
BA_ "GenSigStartValue" SG_ 1220 PDCM_BattEnergyAvaliable 2046;
BA_ "GenSigStartValue" SG_ 1220 PDCM_oilRemainingValue 2046;
BA_ "GenSigStartValue" SG_ 1220 PDCM_oilPercent 1006;
BA_ "GenMsgCycleTime" BO_ 1221 100;
BA_ "GenSigStartValue" SG_ 1221 PDCM_remainingMileageOil_Standard 2046;
BA_ "GenSigStartValue" SG_ 1221 PDCM_remainingMileageOil_Real 2046;
BA_ "GenMsgCycleTime" BO_ 1222 100;
BA_ "GenSigStartValue" SG_ 1222 PDCM_TripADistance 16777214;
BA_ "GenSigStartValue" SG_ 1222 PDCM_TripAAvgPwrConsum 1022;
BA_ "GenSigStartValue" SG_ 1222 PDCM_TripAAvgSpeed 510;
BA_ "GenSigStartValue" SG_ 1222 PDCM_TripAAvgOilConsum 254;
BA_ "GenSigStartValue" SG_ 1222 PDCM_TripALastingTime 8190;
BA_ "GenSigStartValue" SG_ 1222 PDCM_TripAOilDistance 16777214;
BA_ "GenSigStartValue" SG_ 1222 PDCM_TripAPwrDistance 16777214;
BA_ "GenMsgCycleTime" BO_ 1223 100;
BA_ "GenSigStartValue" SG_ 1223 PDCM_totalMilAvgPwrConsum 1022;
BA_ "GenSigStartValue" SG_ 1223 PDCM_totalMilAvgSpd 510;
BA_ "GenSigStartValue" SG_ 1223 PDCM_totalMilAvgOilConsum 254;
BA_ "GenSigStartValue" SG_ 1223 PDCM_totalMilLastingTime 8190;
BA_ "GenMsgCycleTime" BO_ 1224 100;
BA_ "GenSigStartValue" SG_ 1224 PDCM_CurrentTripDistance 16777214;
BA_ "GenSigStartValue" SG_ 1224 PDCM_CurrentTripAvgPwrConsum 1022;
BA_ "GenSigStartValue" SG_ 1224 PDCM_CurrentTripAvgSpd 510;
BA_ "GenSigStartValue" SG_ 1224 PDCM_CurrentTripAvgOilConsum 254;
BA_ "GenSigStartValue" SG_ 1224 PDCM_CurrentTripLastingTime 8190;
BA_ "GenMsgCycleTime" BO_ 1225 100;
BA_ "GenSigStartValue" SG_ 1225 PDCM_SinceChargeDistance 16777214;
BA_ "GenSigStartValue" SG_ 1225 PDCM_SinceChargeAvgPwrConsum 1022;
BA_ "GenSigStartValue" SG_ 1225 PDCM_SinceChargeAvgSpd 510;
BA_ "GenSigStartValue" SG_ 1225 PDCM_SinceChargeAvgOilConsum 254;
BA_ "GenSigStartValue" SG_ 1225 PDCM_SinceChargeTime 8190;
BA_ "GenMsgCycleTime" BO_ 1226 100;
BA_ "GenSigStartValue" SG_ 1226 PDCM_SinceRefulDistance 16777214;
BA_ "GenSigStartValue" SG_ 1226 PDCM_SinceRefulAvgPwrConsum 1022;
BA_ "GenSigStartValue" SG_ 1226 PDCM_SinceRefulAvgSpd 510;
BA_ "GenSigStartValue" SG_ 1226 PDCM_SinceRefulAvgOilConsum 254;
BA_ "GenSigStartValue" SG_ 1226 PDCM_SinceRefulLastingTime 8190;
BA_ "GenMsgCycleTime" BO_ 1227 100;
BA_ "GenSigStartValue" SG_ 1227 PDCM_CurrentTripDrvCnsPer 1022;
BA_ "GenSigStartValue" SG_ 1227 PDCM_CurrentTripCabinSoftCnsPer 1022;
BA_ "GenSigStartValue" SG_ 1227 PDCM_CurrentTripEleCnsPer 1022;
BA_ "GenSigStartValue" SG_ 1227 PDCM_CurrentTripFuelCnsPer 1022;
BA_ "GenSigStartValue" SG_ 1227 PDCM_CurrentTripV2LCnsPer 1022;
BA_ "GenSigStartValue" SG_ 1227 PDCM_CurrentTripOthCnsPer 1022;
BA_ "GenMsgCycleTime" BO_ 1228 100;
BA_ "GenSigStartValue" SG_ 1228 PDCM_SinceChargeDrvCnsPer 1022;
BA_ "GenSigStartValue" SG_ 1228 PDCM_SinceChargeCabinSoftCnsPer 1022;
BA_ "GenSigStartValue" SG_ 1228 PDCM_SinceChargeEleCnsPer 1022;
BA_ "GenSigStartValue" SG_ 1228 PDCM_SinceChargeFuelCnsPer 1022;
BA_ "GenSigStartValue" SG_ 1228 PDCM_SinceChargeV2LCnsPer 1022;
BA_ "GenSigStartValue" SG_ 1228 PDCM_SinceChargeOthCnsPer 1022;
BA_ "GenSigStartValue" SG_ 1228 PDCM_SinceChargeEVCnsPer 1022;
BA_ "GenMsgCycleTime" BO_ 1229 100;
BA_ "GenSigStartValue" SG_ 1229 PDCM_SinceRefulDrvCnsPer 1022;
BA_ "GenSigStartValue" SG_ 1229 PDCM_SinceRefulCabinSoftCnsPer 1022;
BA_ "GenSigStartValue" SG_ 1229 PDCM_SinceRefulEleCnsPer 1022;
BA_ "GenSigStartValue" SG_ 1229 PDCM_SinceRefulFuelCnsPer 1022;
BA_ "GenSigStartValue" SG_ 1229 PDCM_SinceRefulV2LCnsPer 1022;
BA_ "GenSigStartValue" SG_ 1229 PDCM_SinceRefulOthCnsPer 1022;
BA_ "GenSigStartValue" SG_ 1229 PDCM_SinceRefulSeriCnsPer 1022;
BA_ "GenSigStartValue" SG_ 1229 PDCM_SinceRefulParalCnsPer 1022;
BA_ "GenMsgCycleTime" BO_ 1230 100;
BA_ "GenSigStartValue" SG_ 1230 PDCM_SinceTripADrvCnsPer 1022;
BA_ "GenSigStartValue" SG_ 1230 PDCM_SinceTripACabinSoftCnsPer 1022;
BA_ "GenSigStartValue" SG_ 1230 PDCM_SinceTripAEleCnsPer 1022;
BA_ "GenSigStartValue" SG_ 1230 PDCM_SinceTripAFuelCnsPer 1022;
BA_ "GenSigStartValue" SG_ 1230 PDCM_SinceTripAV2LCnsPer 1022;
BA_ "GenSigStartValue" SG_ 1230 PDCM_SinceTripAOthCnsPer 1022;
BA_ "GenSigStartValue" SG_ 1230 PDCM_SinceTripAEVCnsPer 1022;
BA_ "GenSigStartValue" SG_ 1230 PDCM_SinceTripASeriCnsPer 1022;
BA_ "GenSigStartValue" SG_ 1230 PDCM_SinceTripAParalCnsPer 1022;
BA_ "GenMsgCycleTime" BO_ 1231 100;
BA_ "GenSigStartValue" SG_ 1231 PDCM_DayAvgOilConsum 254;
BA_ "GenSigStartValue" SG_ 1231 PDCM_DayAvgPwrConsum 1022;
BA_ "GenMsgCycleTime" BO_ 1232 100;
BA_ "GenSigStartValue" SG_ 1232 PDCM_ConsumpRatioInstantDrv 1534;
BA_ "GenSigStartValue" SG_ 1232 PDCM_ConsumpRatioInstantSt 1534;
BA_ "GenSigStartValue" SG_ 1232 PDCM_FuelConsumpDrv 1022;
BA_ "GenSigStartValue" SG_ 1232 PDCM_FuelConsumpSt 1022;
BA_ "GenMsgCycleTime" BO_ 1233 100;
BA_ "GenSigStartValue" SG_ 1233 PDCM_totalMileage 16777214;
BA_ "GenSigStartValue" SG_ 1233 PDCM_totalMileageRev 16777214;
BA_ "GenMsgCycleTime" BO_ 1253 100;
BA_ "GenMsgCycleTime" BO_ 791 100;
BA_ "GenMsgCycleTime" BO_ 792 100;
BA_ "GenMsgCycleTime" BO_ 1242 100;
BA_ "GenSigStartValue" SG_ 1242 IC_FuelConsump 1022;
BA_ "GenSigStartValue" SG_ 1242 IC_ConsumpRatioInstant 1022;
BA_ "GenSigStartValue" SG_ 1242 ic_oilPercent 254;
BA_ "GenSigStartValue" SG_ 1242 IC_OilRemainingMileage 1022;
BA_ "GenSigStartValue" SG_ 1242 IC_OilSensorResistance 510;
BA_ "GenMsgCycleTime" BO_ 837 100;
BA_ "GenSigStartValue" SG_ 837 LBMS_CellU1 8190;
BA_ "GenSigStartValue" SG_ 837 LBMS_CellU2 8190;
BA_ "GenSigStartValue" SG_ 837 LBMS_CellU3 8190;
BA_ "GenSigStartValue" SG_ 837 LBMS_CellU4 8190;
BA_ "GenSigStartValue" SG_ 837 LBMS_PackCurrent 1048574;
BA_ "GenSigStartValue" SG_ 837 LBMS_PackIntU 32766;
BA_ "GenSigStartValue" SG_ 837 LBMS_PackExtU 16383;
BA_ "GenSigStartValue" SG_ 837 LBMS_PackT1 254;
BA_ "GenSigStartValue" SG_ 837 LBMS_PackT2 254;
BA_ "GenSigStartValue" SG_ 837 LBMS_PackT3 254;
BA_ "GenSigStartValue" SG_ 837 LBMS_PackIntUCal 32766;
BA_ "GenSigStartValue" SG_ 837 LBMS_DischrgMOST 254;
BA_ "GenSigStartValue" SG_ 837 LBMS_ChrgCMOST 254;
BA_ "GenSigStartValue" SG_ 837 LBMS_BalanceTemp 254;
BA_ "GenSigStartValue" SG_ 837 LBMS_BuckT 254;
BA_ "GenMsgCycleTime" BO_ 838 100;
BA_ "GenSigStartValue" SG_ 838 LBMS_SOH 126;
BA_ "GenSigStartValue" SG_ 838 LBMS_BuckStatus 1;
BA_ "GenSigInactiveValue" SG_ 838 LBMS_BuckStatus 1;
BA_ "GenSigStartValue" SG_ 838 LBMS_RealSOC 126;
BA_ "GenSigStartValue" SG_ 838 LBMS_MaxAllwChrgU 32766;
BA_ "GenSigStartValue" SG_ 838 LBMS_ReqChrgU 32766;
BA_ "GenSigStartValue" SG_ 838 LBMS_MaxAllwChrgCurrent 1048574;
BA_ "GenSigStartValue" SG_ 838 LBMS_MaxAllwDischrgCurrent 1048574;
BA_ "GenSigStartValue" SG_ 838 LBMS_LowSOCWakeupThre 126;
BA_ "GenSigStartValue" SG_ 838 LBMS_LowUWakeupThre 32766;
BA_ "GenSigStartValue" SG_ 838 LBMS_SOC 255;
BA_ "GenMsgCycleTime" BO_ 630 100;
BA_ "NmMessage" BO_ 1585 1;
BA_ "GenMsgSendType" BO_ 1585 1;
BA_ "CANFD_BRS" BO_ 1585 0;
BA_ "VFrameFormat" BO_ 1585 0;
BA_ "GenSigSendType" SG_ 1585 PDCM_PT_RMR 2;
BA_ "GenSigSendType" SG_ 1585 PDCM_PT_AWB 2;
BA_ "NmMessage" BO_ 1616 1;
BA_ "GenMsgSendType" BO_ 1616 1;
BA_ "CANFD_BRS" BO_ 1616 0;
BA_ "VFrameFormat" BO_ 1616 0;
BA_ "GenSigSendType" SG_ 1616 EPB_PT_RMR 2;
BA_ "GenSigSendType" SG_ 1616 EPB_PT_AWB 2;
BA_ "NmMessage" BO_ 1642 1;
BA_ "GenMsgSendType" BO_ 1642 1;
BA_ "CANFD_BRS" BO_ 1642 0;
BA_ "VFrameFormat" BO_ 1642 0;
BA_ "GenSigSendType" SG_ 1642 LBMS_SNID 2;
BA_ "GenSigStartValue" SG_ 1642 LBMS_SNID 255;
BA_ "GenSigSendType" SG_ 1642 LBMS_RMR 2;
BA_ "GenSigSendType" SG_ 1642 LBMS_AWB 2;
BA_ "GenSigSendType" SG_ 1642 LBMS_RepeatSts 2;
BA_ "GenSigSendType" SG_ 1642 LBMS_NMReq_NM 2;
BA_ "GenSigSendType" SG_ 1642 LBMS_NMReq_Diag 2;
BA_ "GenSigSendType" SG_ 1642 LBMS_NMReq_Poweron 2;
BA_ "GenSigSendType" SG_ 1642 LBMS_NMReq_LowSOCWakeup 2;
BA_ "GenSigSendType" SG_ 1642 LBMS_NMReq_RechrgWakeup 2;
BA_ "NmMessage" BO_ 1614 1;
BA_ "GenMsgSendType" BO_ 1614 1;
BA_ "CANFD_BRS" BO_ 1614 0;
BA_ "VFrameFormat" BO_ 1614 0;
BA_ "GenSigSendType" SG_ 1614 GW_PT_RMR 2;
BA_ "GenSigSendType" SG_ 1614 GW_PT_AWB 2;
BA_ "GenMsgCycleTime" BO_ 992 100;
BA_ "GenSigStartValue" SG_ 992 srm_srOpenPosition 127;
BA_ "GenSigStartValue" SG_ 992 ssm_ssOpenPosition 127;
BA_ "DiagState" BO_ 2015 1;
BA_ "GenMsgSendType" BO_ 2015 1;
BA_ "CANFD_BRS" BO_ 2015 0;
BA_ "VFrameFormat" BO_ 2015 0;
BA_ "GenSigSendType" SG_ 2015 FUN_DiagReq 2;
BA_ "GenMsgSendType" BO_ 1841 1;
BA_ "CANFD_BRS" BO_ 1841 0;
BA_ "VFrameFormat" BO_ 1841 0;
BA_ "GenSigSendType" SG_ 1841 PDCM_DiagReq 2;
BA_ "GenMsgSendType" BO_ 1969 1;
BA_ "CANFD_BRS" BO_ 1969 0;
BA_ "VFrameFormat" BO_ 1969 0;
BA_ "GenSigSendType" SG_ 1969 PDCM_DiagResp 2;
BA_ "GenMsgSendType" BO_ 2018 1;
BA_ "CANFD_BRS" BO_ 2018 0;
BA_ "VFrameFormat" BO_ 2018 0;
BA_ "GenSigSendType" SG_ 2018 PDCM_DiagReq_OBD 2;
BA_ "GenMsgSendType" BO_ 2026 1;
BA_ "CANFD_BRS" BO_ 2026 0;
BA_ "VFrameFormat" BO_ 2026 0;
BA_ "GenSigSendType" SG_ 2026 PDCM_DiagResp_OBD 2;
BA_ "GenMsgSendType" BO_ 1802 1;
BA_ "CANFD_BRS" BO_ 1802 0;
BA_ "VFrameFormat" BO_ 1802 0;
BA_ "GenSigSendType" SG_ 1802 EPB_DiagReq_PT 2;
BA_ "GenMsgSendType" BO_ 1930 1;
BA_ "CANFD_BRS" BO_ 1930 0;
BA_ "VFrameFormat" BO_ 1930 0;
BA_ "GenSigSendType" SG_ 1930 EPB_DiagResp_PT 2;
BA_ "GenMsgSendType" BO_ 2021 1;
BA_ "CANFD_BRS" BO_ 2021 0;
BA_ "VFrameFormat" BO_ 2021 0;
BA_ "GenSigSendType" SG_ 2021 BMS_DiagReq 2;
BA_ "GenMsgSendType" BO_ 2029 1;
BA_ "CANFD_BRS" BO_ 2029 0;
BA_ "VFrameFormat" BO_ 2029 0;
BA_ "GenSigSendType" SG_ 2029 BMS_DiagResp 2;
BA_ "GenMsgSendType" BO_ 1847 1;
BA_ "CANFD_BRS" BO_ 1847 0;
BA_ "VFrameFormat" BO_ 1847 0;
BA_ "GenSigSendType" SG_ 1847 OBC1_DiagReq 2;
BA_ "GenMsgSendType" BO_ 1975 1;
BA_ "CANFD_BRS" BO_ 1975 0;
BA_ "VFrameFormat" BO_ 1975 0;
BA_ "GenSigSendType" SG_ 1975 OBC1_DiagResp 2;
BA_ "GenMsgSendType" BO_ 2019 1;
BA_ "CANFD_BRS" BO_ 2019 0;
BA_ "VFrameFormat" BO_ 2019 0;
BA_ "GenSigSendType" SG_ 2019 MCUF_DiagReq 2;
BA_ "GenMsgSendType" BO_ 2027 1;
BA_ "CANFD_BRS" BO_ 2027 0;
BA_ "VFrameFormat" BO_ 2027 0;
BA_ "GenSigSendType" SG_ 2027 MCUF_DiagResp 2;
BA_ "GenMsgSendType" BO_ 2020 1;
BA_ "CANFD_BRS" BO_ 2020 0;
BA_ "VFrameFormat" BO_ 2020 0;
BA_ "GenSigSendType" SG_ 2020 MCUR_DiagReq 2;
BA_ "GenMsgSendType" BO_ 2028 1;
BA_ "CANFD_BRS" BO_ 2028 0;
BA_ "VFrameFormat" BO_ 2028 0;
BA_ "GenSigSendType" SG_ 2028 MCUR_DiagResp 2;
BA_ "GenMsgSendType" BO_ 2016 1;
BA_ "CANFD_BRS" BO_ 2016 0;
BA_ "VFrameFormat" BO_ 2016 0;
BA_ "GenSigSendType" SG_ 2016 EMS_DiagReq 2;
BA_ "GenMsgSendType" BO_ 2024 1;
BA_ "CANFD_BRS" BO_ 2024 0;
BA_ "VFrameFormat" BO_ 2024 0;
BA_ "GenSigSendType" SG_ 2024 PEMS_DiagResp 2;
BA_ "GenMsgSendType" BO_ 2022 1;
BA_ "CANFD_BRS" BO_ 2022 0;
BA_ "VFrameFormat" BO_ 2022 0;
BA_ "GenSigSendType" SG_ 2022 GCU_DiagReq 2;
BA_ "GenMsgSendType" BO_ 2030 1;
BA_ "CANFD_BRS" BO_ 2030 0;
BA_ "VFrameFormat" BO_ 2030 0;
BA_ "GenSigSendType" SG_ 2030 GCU_DiagResp 2;
BA_ "GenMsgSendType" BO_ 2017 1;
BA_ "CANFD_BRS" BO_ 2017 0;
BA_ "VFrameFormat" BO_ 2017 0;
BA_ "GenSigSendType" SG_ 2017 TCU_DiagReq 2;
BA_ "GenMsgSendType" BO_ 2025 1;
BA_ "CANFD_BRS" BO_ 2025 0;
BA_ "VFrameFormat" BO_ 2025 0;
BA_ "GenSigSendType" SG_ 2025 TCU_DiagResp 2;
BA_ "GenMsgSendType" BO_ 1817 1;
BA_ "CANFD_BRS" BO_ 1817 0;
BA_ "VFrameFormat" BO_ 1817 0;
BA_ "GenSigSendType" SG_ 1817 SWM_DiagReq 2;
BA_ "GenMsgSendType" BO_ 1945 1;
BA_ "CANFD_BRS" BO_ 1945 0;
BA_ "VFrameFormat" BO_ 1945 0;
BA_ "GenSigSendType" SG_ 1945 SWM_DiagResp 2;
BA_ "GenMsgSendType" BO_ 1870 1;
BA_ "CANFD_BRS" BO_ 1870 0;
BA_ "VFrameFormat" BO_ 1870 0;
BA_ "GenSigSendType" SG_ 1870 LBMS_DiagReq 2;
BA_ "GenMsgSendType" BO_ 1998 1;
BA_ "CANFD_BRS" BO_ 1998 0;
BA_ "VFrameFormat" BO_ 1998 0;
BA_ "GenSigSendType" SG_ 1998 LBMS_DiagResp 2;
VAL_ 734 AC_OBD_f032_Reserved 2 "Diagnostic Failed" 1 "Diagnostic Passed" 0 "Diagnostic not finished" ;
VAL_ 734 AC_OBD_f033_Reserved 2 "Diagnostic Failed" 1 "Diagnostic Passed" 0 "Diagnostic not finished" ;
VAL_ 734 AC_OBD_f034_HVWHforHC_LostCom 2 "Diagnostic Failed" 1 "Diagnostic Passed" 0 "Diagnostic not finished" ;
VAL_ 734 AC_OBD_f035_HVWHforHC_OveVol 2 "Diagnostic Failed" 1 "Diagnostic Passed" 0 "Diagnostic not finished" ;
VAL_ 734 AC_OBD_f036_HVWHforHC_UndVol 2 "Diagnostic Failed" 1 "Diagnostic Passed" 0 "Diagnostic not finished" ;
VAL_ 734 AC_OBD_f037_HVWHforHC_BoiErr 2 "Diagnostic Failed" 1 "Diagnostic Passed" 0 "Diagnostic not finished" ;
VAL_ 734 AC_OBD_f038_HVWHforHC_CirErr 2 "Diagnostic Failed" 1 "Diagnostic Passed" 0 "Diagnostic not finished" ;
VAL_ 734 AC_OBD_f039_WaterPumpHC 2 "Diagnostic Failed" 1 "Diagnostic Passed" 0 "Diagnostic not finished" ;
VAL_ 734 AC_OBD_f040_3WayValForBat_LosCom 2 "Diagnostic Failed" 1 "Diagnostic Passed" 0 "Diagnostic not finished" ;
VAL_ 734 AC_OBD_f041_3WayValForBat_ResErr 2 "Diagnostic Failed" 1 "Diagnostic Passed" 0 "Diagnostic not finished" ;
VAL_ 734 AC_OBD_f042_3WayValForBat_ActErr 2 "Diagnostic Failed" 1 "Diagnostic Passed" 0 "Diagnostic not finished" ;
VAL_ 734 AC_OBD_f043_3WayValForBat_VolErr 2 "Diagnostic Failed" 1 "Diagnostic Passed" 0 "Diagnostic not finished" ;
VAL_ 734 AC_OBD_f044_ECU_IntFau 2 "Diagnostic Failed" 1 "Diagnostic Passed" 0 "Diagnostic not finished" ;
VAL_ 734 AC_OBD_f045_AMBSensor_SBOL 2 "Diagnostic Failed" 1 "Diagnostic Passed" 0 "Diagnostic not finished" ;
VAL_ 734 AC_OBD_f046_AMBSensor_SG 2 "Diagnostic Failed" 1 "Diagnostic Passed" 0 "Diagnostic not finished" ;
VAL_ 734 AC_OBD_f047_AMBSensor_OutRanLo 2 "Diagnostic Failed" 1 "Diagnostic Passed" 0 "Diagnostic not finished" ;
VAL_ 734 AC_OBD_f048_AMBSensor_OutRanHi 2 "Diagnostic Failed" 1 "Diagnostic Passed" 0 "Diagnostic not finished" ;
VAL_ 734 AC_OBD_f049_AMBSensor_RatFau 2 "Diagnostic Failed" 1 "Diagnostic Passed" 0 "Diagnostic not finished" ;
VAL_ 734 AC_OBD_f050_UnderBatVol 2 "Diagnostic Failed" 1 "Diagnostic Passed" 0 "Diagnostic not finished" ;
VAL_ 734 AC_OBD_f051_OverBatVol 2 "Diagnostic Failed" 1 "Diagnostic Passed" 0 "Diagnostic not finished" ;
VAL_ 734 AC_OBD_f052_ComCANBusOff 2 "Diagnostic Failed" 1 "Diagnostic Passed" 0 "Diagnostic not finished" ;
VAL_ 734 AC_OBD_f053_GW_NoCom 2 "Diagnostic Failed" 1 "Diagnostic Passed" 0 "Diagnostic not finished" ;
VAL_ 734 AC_OBD_FaultClrsts 1 "Complete" 0 "NO complete" ;
VAL_ 734 AC_EDC_HV_Voltage 255 "Invalid" 254 "1270" 0 "0" ;
VAL_ 734 AC_HVWH_Bat_HV_Voltage 255 "Invalid" 254 "Reserve" 253 "Reserve" 252 "Reserve" 251 "Reserve" 250 "Reserve" 249 "Reserve" 248 "Reserve" 247 "Reserve" 246 "Reserve" 245 "Reserve" 244 "Reserve" 243 "Reserve" 242 "Reserve" 241 "Reserve" 240 "Reserve" 239 "Reserve" 238 "Reserve" 237 "Reserve" 236 "Reserve" 235 "Reserve" 234 "Reserve" 233 "Reserve" 232 "Reserve" 231 "Reserve" 230 "Reserve" 229 "Reserve" 228 "Reserve" 227 "Reserve" 226 "Reserve" 225 "Reserve" 224 "Reserve" 223 "Reserve" 222 "Reserve" 221 "Reserve" 220 "Reserve" 219 "Reserve" 218 "Reserve" 217 "Reserve" 216 "Reserve" 215 "Reserve" 214 "Reserve" 213 "Reserve" 212 "Reserve" 211 "Reserve" 210 "Reserve" 209 "Reserve" 208 "Reserve" 207 "Reserve" 206 "Reserve" 205 "Reserve" 204 "Reserve" 203 "Reserve" 202 "Reserve" 201 "Reserve" 200 "Reserve" 199 "Reserve" 198 "Reserve" 197 "Reserve" 196 "Reserve" 195 "Reserve" 194 "Reserve" 193 "Reserve" 192 "Reserve" 191 "Reserve" 190 "Reserve" 189 "Reserve" 188 "Reserve" 187 "Reserve" 186 "Reserve" 185 "Reserve" 184 "Reserve" 183 "Reserve" 182 "Reserve" 181 "Reserve" 180 "Reserve" 179 "Reserve" 178 "Reserve" 177 "Reserve" 176 "Reserve" 175 "Reserve" 174 "Reserve" 173 "Reserve" 172 "Reserve" 171 "Reserve" 170 "Reserve" 169 "Reserve" 168 "Reserve" 167 "Reserve" 166 "Reserve" 165 "Reserve" 164 "Reserve" 163 "Reserve" 162 "Reserve" 161 "Reserve" 160 "Reserve" 159 "Reserve" 158 "Reserve" 157 "Reserve" 156 "Reserve" 155 "Reserve" 154 "Reserve" 153 "Reserve" 152 "Reserve" 151 "Reserve" 150 "Reserve" 149 "Reserve" 148 "Reserve" 147 "Reserve" 146 "Reserve" 145 "Reserve" 144 "Reserve" 143 "Reserve" 142 "Reserve" 141 "Reserve" 140 "Reserve" 139 "Reserve" 138 "Reserve" 137 "Reserve" 136 "Reserve" 135 "Reserve" 134 "Reserve" 133 "Reserve" 132 "Reserve" 131 "Reserve" 130 "Reserve" 129 "Reserve" 128 "Reserve" 127 "Reserve" 126 "Reserve" 125 "Reserve" 124 "Reserve" 123 "Reserve" 122 "Reserve" 121 "Reserve" 120 "Reserve" 119 "Reserve" 118 "Reserve" 117 "Reserve" 116 "Reserve" 115 "Reserve" 114 "Reserve" 113 "Reserve" 112 "Reserve" 111 "Reserve" 110 "Reserve" 109 "Reserve" 108 "Reserve" 107 "Reserve" 106 "Reserve" 105 "Reserve" 104 "Reserve" 103 "Reserve" 102 "Reserve" 101 "Reserve" 100 "500" 0 "0" ;
VAL_ 731 AC_OBD_Comp_OverpPhaseCurrentError 2 "Diagnostic Failed" 1 "Diagnostic Passed" 0 "Diagnostic not finished" ;
VAL_ 731 AC_OBD_Comp_TemperatureSensorError 2 "Diagnostic Failed" 1 "Diagnostic Passed" 0 "Diagnostic not finished" ;
VAL_ 731 AC_OBD_Comp_CurrentSamplingError 2 "Diagnostic Failed" 1 "Diagnostic Passed" 0 "Diagnostic not finished" ;
VAL_ 731 AC_OBD_Comp_DriverError 2 "Diagnostic Failed" 1 "Diagnostic Passed" 0 "Diagnostic not finished" ;
VAL_ 731 AC_OBD_Comp_StartupError 2 "Diagnostic Failed" 1 "Diagnostic Passed" 0 "Diagnostic not finished" ;
VAL_ 731 AC_OBD_Comp_OvertemperatureError 2 "Diagnostic Failed" 1 "Diagnostic Passed" 0 "Diagnostic not finished" ;
VAL_ 731 AC_OBD_Comp_ECU_InternalError 2 "Diagnostic Failed" 1 "Diagnostic Passed" 0 "Diagnostic not finished" ;
VAL_ 731 AC_OBD_Comp_StallError 2 "Diagnostic Failed" 1 "Diagnostic Passed" 0 "Diagnostic not finished" ;
VAL_ 731 AC_OBD_Comp_Hv_UnderVoltageError 2 "Diagnostic Failed" 1 "Diagnostic Passed" 0 "Diagnostic not finished" ;
VAL_ 731 AC_OBD_Comp_Hv_OverVoltageError 2 "Diagnostic Failed" 1 "Diagnostic Passed" 0 "Diagnostic not finished" ;
VAL_ 731 AC_OBD_Comp_Lv_VoltageError 2 "Diagnostic Failed" 1 "Diagnostic Passed" 0 "Diagnostic not finished" ;
VAL_ 731 AC_OBD_EDCStopError 1 "EDC stop Error" 0 "No error" ;
VAL_ 731 AC_OBD_PTC_BStopError 1 "PTC_B (Battery) stop" 0 "no error" ;
VAL_ 731 AC_OBD_PTC_CStopError 1 "PTC_C (Cabin)  stop" 0 "no error" ;
VAL_ 747 AC_OBDCALIDByte0 255 "Invalid" ;
VAL_ 747 AC_OBDCALIDByte1 255 "Invalid" ;
VAL_ 747 AC_OBDCALIDByte2 255 "Invalid" ;
VAL_ 747 AC_OBDCALIDByte3 255 "Invalid" ;
VAL_ 747 AC_OBDCALIDByte4 255 "Invalid" ;
VAL_ 747 AC_OBDCALIDByte5 255 "Invalid" ;
VAL_ 747 AC_OBDCALIDByte6 255 "Invalid" ;
VAL_ 747 AC_OBDCALIDByte7 255 "Invalid" ;
VAL_ 748 AC_OBDCALIDByte8 255 "Invalid" ;
VAL_ 748 AC_OBDCALIDByte9 255 "Invalid" ;
VAL_ 748 AC_OBDCALIDByte10 255 "Invalid" ;
VAL_ 748 AC_OBDCALIDByte11 255 "Invalid" ;
VAL_ 748 AC_OBDCALIDByte12 255 "Invalid" ;
VAL_ 748 AC_OBDCALIDByte13 255 "Invalid" ;
VAL_ 748 AC_OBDCALIDByte14 255 "Invalid" ;
VAL_ 748 AC_OBDCALIDByte15 255 "Invalid" ;
VAL_ 1238 ic_totalMileage 16777215 "Invalid" ;
VAL_ 1238 ic_lowSocIndication 1 "ACTIVE(20% SOC)" 0 "INACTIVE" ;
VAL_ 1238 ic_displayFail 1 "FAULT" 0 "NORMAL" ;
VAL_ 1238 ic_qDashACCFail 3 "Reserved" 2 "Reserved" 1 "ERROR" 0 "NO_ERROR" ;
VAL_ 1238 ic_totalMileageValid 1 "VALID" 0 "INVALID" ;
VAL_ 1238 ic_vehicleSpeedDispValid 1 "VALID" 0 "INVALID" ;
VAL_ 1238 ic_RemainingMileage 1023 "Invalid" ;
VAL_ 1234 IVI_autoWiper 4 "gear4" 3 "gear3" 2 "gear2" 1 "gear1" 0 "Default" ;
VAL_ 1234 ivi_wcmROnOffSet 3 "INVALID" 2 "ON" 1 "OFF" 0 "NO Request" ;
VAL_ 1234 IVI_EetSceneModeSts 15 "Reserved" 14 "Reserved" 13 "Reserved" 12 "Reserved" 11 "CampMode" 10 "MovieMode" 9 "NotPowerOffMode" 8 "WaitingMode" 7 "SelfCarWashMode" 6 "ReceptionMode" 5 "VitalityMode" 4 "RearRightNapMode" 3 "RearLeftNapMode" 2 "RearLeftRighNapMode" 1 "FrontNapMode" 0 "init" ;
VAL_ 1234 IVI_SceneModeExtenderSet 1 "enable" 0 "disable" ;
VAL_ 1234 ivi_PowerHoldModeTime 15 "不限时" 14 "reserved" 13 "reserved" 12 "reserved" 11 "reserved" 10 "reserved" 9 "reserved" 8 "reserved" 7 "reserved" 6 "3h" 5 "2.5h" 4 "2h" 3 "1.5h" 2 "1h" 1 "0.5h" 0 "No request" ;
VAL_ 896 acu_warningLampSts 3 "RESERVED" 2 "FLASH" 1 "ON" 0 "OFF" ;
VAL_ 896 acu_crashOutputStsValid 3 "RESERVED" 2 "RESERVED" 1 "VALID" 0 "INVALID" ;
VAL_ 896 acu_driverSeatBeltSts 1 "TIED" 0 "UNTIED" ;
VAL_ 896 acu_driverSeatBeltStsValid 1 "VALID" 0 "INVALID" ;
VAL_ 896 acu_passengerSeatBeltSts 1 "TIED" 0 "UNTIED" ;
VAL_ 896 acu_passengerSeatBeltStsValid 1 "VALID" 0 "INVALID" ;
VAL_ 896 acu_passengerAirbagSts 3 "RESERVED" 2 "CLOSED" 1 "NOT_CLOSE" 0 "RESERVED" ;
VAL_ 896 acu_secondLeftSeatBeltSts 1 "TIED" 0 "UNTIED" ;
VAL_ 896 acu_secondMiddleSeatBeltSts 1 "TIED" 0 "UNTIED" ;
VAL_ 896 acu_secondRightSeatBeltSts 1 "TIED" 0 "UNTIED" ;
VAL_ 896 acu_passengerSts 1 "OCCUPIED" 0 "UNOCCUPIED" ;
VAL_ 896 acu_secondLeftSts 1 "OCCUPIED" 0 "UNOCCUPIED" ;
VAL_ 896 acu_secondMiddleSts 1 "OCCUPIED" 0 "UNOCCUPIED" ;
VAL_ 896 acu_secondRightSts 1 "OCCUPIED" 0 "UNOCCUPIED" ;
VAL_ 896 acu_crashOutputSts 255 "Reserved" 254 "Reserved" 253 "Reserved" 252 "Reserved" 251 "Reserved" 250 "Reserved" 249 "Reserved" 248 "Reserved" 247 "Reserved" 246 "Reserved" 245 "Reserved" 244 "Reserved" 243 "Reserved" 242 "Reserved" 241 "Reserved" 240 "Reserved" 239 "Reserved" 238 "Reserved" 237 "Reserved" 236 "Reserved" 235 "Reserved" 234 "Reserved" 233 "Reserved" 232 "Reserved" 231 "Reserved" 230 "Reserved" 229 "Reserved" 228 "Reserved" 227 "Reserved" 226 "Reserved" 225 "Reserved" 224 "Reserved" 223 "Reserved" 222 "Reserved" 221 "Reserved" 220 "Reserved" 219 "Reserved" 218 "Reserved" 217 "Reserved" 216 "Reserved" 215 "Reserved" 214 "Reserved" 213 "Reserved" 212 "Reserved" 211 "Reserved" 210 "Reserved" 209 "Reserved" 208 "Reserved" 207 "Reserved" 206 "Reserved" 205 "Reserved" 204 "Reserved" 203 "Reserved" 202 "Reserved" 201 "Reserved" 200 "Reserved" 199 "Reserved" 198 "Reserved" 197 "Reserved" 196 "Reserved" 195 "Reserved" 194 "Reserved" 193 "Reserved" 192 "Reserved" 191 "Reserved" 190 "Reserved" 189 "Reserved" 188 "Reserved" 187 "Reserved" 186 "Reserved" 185 "Reserved" 184 "Reserved" 183 "Reserved" 182 "Reserved" 181 "Reserved" 180 "Reserved" 179 "Reserved" 178 "Reserved" 177 "Reserved" 176 "Reserved" 175 "Reserved" 174 "Reserved" 173 "Reserved" 172 "Reserved" 171 "Reserved" 170 "Reserved" 169 "Reserved" 168 "Reserved" 167 "Reserved" 166 "Reserved" 165 "Reserved" 164 "Reserved" 163 "Reserved" 162 "Reserved" 161 "Reserved" 160 "Reserved" 159 "Reserved" 158 "Reserved" 157 "Reserved" 156 "Reserved" 155 "Reserved" 154 "Reserved" 153 "Reserved" 152 "Reserved" 151 "Reserved" 150 "Reserved" 149 "Reserved" 148 "Reserved" 147 "Reserved" 146 "Reserved" 145 "Reserved" 144 "Reserved" 143 "Reserved" 142 "Reserved" 141 "Reserved" 140 "Reserved" 139 "Reserved" 138 "Reserved" 137 "Reserved" 136 "Reserved" 135 "Reserved" 134 "Reserved" 133 "Reserved" 132 "Reserved" 131 "Reserved" 130 "Reserved" 129 "Reserved" 128 "Reserved" 127 "Reserved" 126 "Reserved" 125 "Reserved" 124 "Reserved" 123 "Reserved" 122 "Reserved" 121 "Reserved" 120 "Reserved" 119 "Reserved" 118 "Reserved" 117 "Reserved" 116 "Reserved" 115 "Reserved" 114 "Reserved" 113 "Reserved" 112 "Reserved" 111 "Reserved" 110 "Reserved" 109 "Reserved" 108 "Reserved" 107 "Reserved" 106 "Reserved" 105 "Reserved" 104 "Reserved" 103 "Reserved" 102 "Reserved" 101 "Reserved" 100 "Reserved" 99 "Reserved" 98 "Reserved" 97 "Reserved" 96 "Reserved" 95 "Reserved" 94 "Reserved" 93 "Reserved" 92 "Reserved" 91 "Reserved" 90 "Reserved" 89 "Reserved" 88 "Reserved" 87 "Reserved" 86 "Reserved" 85 "Reserved" 84 "Reserved" 83 "Reserved" 82 "Reserved" 81 "Reserved" 80 "Reserved" 79 "Reserved" 78 "Reserved" 77 "Reserved" 76 "Reserved" 75 "Reserved" 74 "Reserved" 73 "Reserved" 72 "Reserved" 71 "Reserved" 70 "Reserved" 69 "Reserved" 68 "Reserved" 67 "Reserved" 66 "Reserved" 65 "Reserved" 64 "Reserved" 63 "Reserved" 62 "Reserved" 61 "Reserved" 60 "Reserved" 59 "Reserved" 58 "Reserved" 57 "Reserved" 56 "Reserved" 55 "Reserved" 54 "Reserved" 53 "Reserved" 52 "Reserved" 51 "Reserved" 50 "Reserved" 49 "Reserved" 48 "Reserved" 47 "Reserved" 46 "Reserved" 45 "Reserved" 44 "Reserved" 43 "Reserved" 42 "Reserved" 41 "Reserved" 40 "Reserved" 39 "Reserved" 38 "Reserved" 37 "Reserved" 36 "Reserved" 35 "Reserved" 34 "Reserved" 33 "Reserved" 32 "Reserved" 31 "Reserved" 30 "Reserved" 29 "Reserved" 28 "Reserved" 27 "Reserved" 26 "Reserved" 25 "Reserved" 24 "Reserved" 23 "Reserved" 22 "Reserved" 21 "Reserved" 20 "Reserved" 19 "Reserved" 18 "Reserved" 17 "Reserved" 16 "Reserved" 15 "Rear + Side + Front + BPT" 14 "Rear + Side + Front" 13 "Rear + Side + BPT" 12 "Rear + Side" 11 "Rear + Front + BPT" 10 "Rear + Front" 9 "Rear + BPT" 8 "Rear Crash" 7 "Side + Front + BPT" 6 "Side + Front" 5 "Side + BPT" 4 "Side Crash" 3 "Front + BPT" 2 "Front Crash" 1 "BPT Crash" 0 "No Crash" ;
VAL_ 1041 BCM_FLTpmsSensorFailure_St 3 "SENSOR_ERROR" 2 "SYS_ERROR" 1 "NORMAL_TPMS" 0 "INITIAL_TPMS" ;
VAL_ 1041 BCM_FRTpmsSensorFailure_St 3 "SENSOR_ERROR" 2 "SYS_ERROR" 1 "NORMAL_TPMS" 0 "INITIAL_TPMS" ;
VAL_ 1041 BCM_FLTpmsWheellPressureWarn_St 3 "Reserved" 2 "High pressure" 1 "Low pressure" 0 "Normal pressure" ;
VAL_ 1041 BCM_FRTpmsWheellPressureWarn_St 3 "Reserved" 2 "High pressure" 1 "Low pressure" 0 "Normal pressure" ;
VAL_ 1041 BCM_FLTpmsWheelTempWarn_St 1 "hight temperature" 0 "normal temperature" ;
VAL_ 1041 BCM_FRTpmsWheelTempWarn_St 1 "hight temperature" 0 "normal temperature" ;
VAL_ 1041 BCM_FLTpmsBattle_St 1 "Low voltage" 0 "Normal voltage" ;
VAL_ 1041 BCM_FRTpmsBattle_St 1 "Low voltage" 0 "Normal voltage" ;
VAL_ 1041 BCM_FLTpmsRapidLeakWarn 1 "Warning" 0 "No warning" ;
VAL_ 1041 BCM_FRTpmsRapidLeakWarn 1 "Warning" 0 "No warning" ;
VAL_ 1041 BCM_FLTpmsWheellPressure 255 "Invalid" ;
VAL_ 1041 BCM_FLTpmsWheelTemp 255 "Invalid" ;
VAL_ 1041 BCM_FRTpmsWheellPressure 255 "Invalid" ;
VAL_ 1041 BCM_FRTpmsWheelTemp 255 "Invalid" ;
VAL_ 1057 BCM_RLTpmsSensorFailure_St 3 "SENSOR_ERROR" 2 "SYS_ERROR" 1 "NORMAL_TPMS" 0 "INITIAL_TPMS" ;
VAL_ 1057 BCM_RRTpmsSensorFailure_St 3 "SENSOR_ERROR" 2 "SYS_ERROR" 1 "NORMAL_TPMS" 0 "INITIAL_TPMS" ;
VAL_ 1057 BCM_RLTpmsWheellPressureWarn_St 3 "Reserved" 2 "High pressure" 1 "Low pressure" 0 "Normal pressure" ;
VAL_ 1057 BCM_RRTpmsWheellPressureWarn_St 3 "Reserved" 2 "High pressure" 1 "Low pressure" 0 "Normal pressure" ;
VAL_ 1057 BCM_RLTpmsWheelTempWarn_St 1 "hight temperature" 0 "normal temperature" ;
VAL_ 1057 BCM_RRTpmsWheelTempWarn_St 1 "hight temperature" 0 "normal temperature" ;
VAL_ 1057 BCM_RLTpmsBattle_St 1 "Low voltage" 0 "Normal voltage" ;
VAL_ 1057 BCM_RRTpmsBattle_St 1 "Low voltage" 0 "Normal voltage" ;
VAL_ 1057 BCM_RLTpmsRapidLeakWarn 1 "Warning" 0 "No warning" ;
VAL_ 1057 BCM_RRTpmsRapidLeakWarn 1 "Warning" 0 "No warning" ;
VAL_ 1057 BCM_RLTpmsWheellPressure 255 "Invalid" ;
VAL_ 1057 BCM_RLTpmsWheelTemp 255 "Invalid" ;
VAL_ 1057 BCM_RRTpmsWheellPressure 255 "Invalid" ;
VAL_ 1057 BCM_RRTpmsWheelTemp 255 "Invalid" ;
VAL_ 1239 IC_MaintenanceMileage 65535 "Invalid" ;
VAL_ 1239 ic_lastingtime 2047 "Invalid" ;
VAL_ 1239 ic_mileageSincethelastcharge 16383 "Invalid" ;
VAL_ 1239 ic_tripmeterThisMoment 16383 "Invalid" ;
VAL_ 1239 IC_MaintenanceReset 1 "Request" 0 "No Request" ;
VAL_ 1235 ic_totalMileageRev 16777215 "Invalid" ;
VAL_ 1022 ivi_timeValid 1 "VALID" 0 "INVALID" ;
VAL_ 117 ivi_hoodUnlockCtrl 3 "INVALID" 2 "RESERVED" 1 "UNLOCK" 0 "NO_COMMAND" ;
VAL_ 117 IVI_SOCmodeSet 3 "HEV mode 保电模式（以前代表燃油优先）" 2 "EV mode 纯电优先" 1 "Smart Mode 油电混合" 0 "no request" ;
VAL_ 117 ivi_gloveBoxUnlockCtrl 3 "INVALID" 2 "RESERVED" 1 "UNLOCK" 0 "NO_COMMAND" ;
VAL_ 117 IVI_EVonlymodereq_HW 3 "无效" 2 "OFF" 1 "ON" 0 "No reuquest" ;
VAL_ 117 ivi_v2vChrgOnOffSet 3 "INVALID" 2 "ON" 1 "OFF" 0 "NO Request" ;
VAL_ 117 ivi_obcDschrgOnOffSet 3 "INVALID" 2 "ON" 1 "OFF" 0 "NO_COMMAND" ;
VAL_ 117 ivi_modememory 3 "INVALID" 2 "Memory" 1 "No_Memory" 0 "NO REQUEST" ;
VAL_ 117 ivi_gunUnlockCtrlReq 1 "Request" 0 "No Request" ;
VAL_ 117 IVI_apaOnOffSet 1 "Request" 0 "No Request" ;
VAL_ 117 IVI_AVMOnOffSet 1 "Request" 0 "No Request" ;
VAL_ 117 IVI_PDCOnOffSet 1 "Request" 0 "No Request" ;
VAL_ 117 IVI_V2LMinSocSet 15 "Invalid" ;
VAL_ 117 IVI_UserPrivacyModeSts 2 "ON" 1 "OFF" 0 "No request" ;
VAL_ 117 IVI_SelfHeatingAllow 2 "Not Allow" 1 "Allow" 0 "no request" ;
VAL_ 117 ivi_ExhibitionSet 7 "Invalid" 6 "reserved" 5 "reserved" 4 "reserved" 3 "Transport Mode" 2 "ExhibitionMode" 1 "NormalMode" 0 "NO Request" ;
VAL_ 117 ivi_v2vChrgOptCurntSet 15 "INVALID" 14 "Reserved" 13 "Reserved" 12 "Reserved" 11 "Reserved" 10 "Reserved" 9 "100" 8 "90" 7 "80" 6 "70" 5 "60" 4 "50" 3 "40" 2 "30" 1 "20" 0 "NO Request" ;
VAL_ 117 ivi_BatteryCondition 3 "INVALID" 2 "ON" 1 "OFF" 0 "NO REQUEST" ;
VAL_ 117 IVI_SREVSOCset 0 "Invalid" ;
VAL_ 117 IVI_SREVSOCset_HW 12 "25%~80%" 11 "25%~80%" 10 "25%~80%" 9 "25%~80%" 8 "25%~80%" 7 "25%~80%" 6 "25%~80%" 5 "25%~80%" 4 "25%~80%" 3 "25%~80%" 2 "25%~80%" 1 "25%~80%" 0 "No request" ;
VAL_ 117 IVI_EVonlymodereq 1 "ON" 0 "OFF" ;
VAL_ 117 ivi_lowVoltPowerCtrl 3 "INVALID" 2 "RESERVED" 1 "POWER_ON_REQUEST" 0 "NO_COMMAND" ;
VAL_ 165 ivi_MaxFuelConsumptionSW 3 "INVALID" 2 "ON" 1 "OFF" 0 "NO_COMMAND" ;
VAL_ 165 ivi_maxChargeCurrentSet 63 "Invalid" ;
VAL_ 165 ivi_ChargeCancel 1 "CANCEL" 0 "NO_REQUEST" ;
VAL_ 165 ivi_RegenModeSet 7 "Reserved" 6 "Reserved" 5 "Reserved" 4 "Strong Recovery" 3 "NORMAL" 2 "LOW" 1 "OFF" 0 "NO REQ" ;
VAL_ 165 ivi_MaxFuelConsumptionModeSW 3 "INVALID" 2 "Low Speed" 1 "High Speed" 0 "NO_COMMAND" ;
VAL_ 165 ivi_propModeSet 3 "SPORT" 2 "STANDARD" 1 "ECO" 0 "NO  Request" ;
VAL_ 165 ivi_maxChrgSocSet 255 "Invalid" 254 "No Request" ;
VAL_ 165 ivi_startRevSOCSet 63 "INVALID" 1 "20%~0x3D:80%" 0 "NO  Request" ;
VAL_ 165 ivi_ChargeEndTimeHalfDay 1 "AFTERNOON" 0 "MORNING" ;
VAL_ 165 ivi_ChargeStartTimeHalfDay 1 "AFTERNOON" 0 "MORNING" ;
VAL_ 165 ivi_ChargeEndTimeHour 15 "Invalid" 12 "12" 11 "11" 10 "10" 9 "9" 8 "8" 7 "7" 6 "6" 5 "5" 4 "4" 3 "3" 2 "2" 1 "1" 0 "Reserved" ;
VAL_ 165 ivi_ChargeStartTimeHour 15 "Invalid" 12 "12" 11 "11" 10 "10" 9 "9" 8 "8" 7 "7" 6 "6" 5 "5" 4 "4" 3 "3" 2 "2" 1 "1" 0 "No Request" ;
VAL_ 165 ivi_chargeFormSet 3 "RESERVE_CHRGFORM1" 2 "TIMING_CHARGE" 1 "IMMEDIATE_CHARGE" 0 "NO_REQUEST" ;
VAL_ 165 ivi_ChargeEndTimeMinute 63 "No Request" ;
VAL_ 165 ivi_ChargeStartTimeMinute 63 "No Request" ;
VAL_ 165 ivi_ChargeEnable 1 "ENABLE" 0 "NO_REQUEST" ;
VAL_ 165 ivi_chargeSetValid 1 "VALID" 0 "INVALID" ;
VAL_ 165 ivi_ResetCurrentTrip 1 "REQUEST" 0 "NO_REQUEST" ;
VAL_ 165 ivi_ChargeEndTimeValid 1 "VALID" 0 "INVALID" ;
VAL_ 165 ivi_ChargeStartTimeValid 1 "VALID" 0 "INVALID" ;
VAL_ 165 ivi_driveModeSet 7 "RESERVED" 6 "SNOW" 5 "All Road" 4 "INDIVIDUAL" 3 "SPORT" 2 "COMFORT" 1 "ECO" 0 "NO  Request" ;
VAL_ 476 ivi_centralLockCtrl 3 "INVALID" 2 "LOCK" 1 "UNLOCK" 0 "NO_COMMAND" ;
VAL_ 476 ivi_fuelPortCapOpenCtrl 3 "INVALID" 2 "RESERVED_FUELPORT" 1 "OPEN_FUELPORT" 0 "NO_COMMAND_FUELPORT" ;
VAL_ 476 ivi_chrgPortCapOpenCtrl 3 "INVALID" 2 "RESERVED" 1 "OPEN" 0 "NO_COMMAND" ;
VAL_ 476 ivi_antiTheftAlarmFormSet 3 "No Request" 2 "Reserved" 1 "Vision+Voice" 0 "Only Vision" ;
VAL_ 476 ivi_approachingUnlockCtrl 3 "INVALID" 2 "INACTIVE" 1 "ACTIVE" 0 "NO_COMMAND" ;
VAL_ 476 ivi_awayLockCtrl 3 "INVALID" 2 "INACTIVE" 1 "ACTIVE" 0 "NO_COMMAND" ;
VAL_ 476 ivi_parkAutoCloseDRLCtrl 3 "INVALID" 2 "Disable" 1 "Enable" 0 "No Request" ;
VAL_ 476 ivi_welcomeSetEnable 3 "INVALID" 2 "Enable" 1 "Disable" 0 "NO  Request" ;
VAL_ 476 ivi_welcomeOnOffSet 15 "Reserved" 14 "Reserved" 13 "Reserved" 12 "Reserved" 11 "Mode10" 10 "Mode9" 9 "Mode8" 8 "Mode7" 7 "Mode6" 6 "Mode5" 5 "Mode4" 4 "Mode3" 3 "Mode2" 2 "Mode1" 1 "OFF" 0 "Default" ;
VAL_ 476 ivi_followMeHomeSet 7 "INVALID" 4 "60S" 3 "30S" 2 "15S" 1 "OFF" 0 "NO_COMMAND" ;
VAL_ 476 ivi_WiperMaintenanceCtrl 2 "ON" 1 "OFF" 0 "No request" ;
VAL_ 476 ivi_lockAutoCloseWinCtrl 3 "INVALID" 2 "INACTIVE" 1 "ACTIVE" 0 "NO_COMMAND" ;
VAL_ 476 IVI_Backlightadjust 15 "Invalid" 14 "Reserved" 13 "Reserved" 12 "Reserved" 11 "Reserved" 10 "Level 10" 9 "Level 9" 8 "Level 8" 7 "Level 7" 6 "Level 6" 5 "Level 5" 4 "Level 4" 3 "Level 3" 2 "Level 2" 1 "Level 1" 0 "No Action" ;
VAL_ 476 ivi_VehiclePowerOFF 1 "Request" 0 "NO Request" ;
VAL_ 476 ivi_sunroofGlassCmd 7 "STOP_SUNSHADE" 6 "CLOSE_SUNSHAGE" 5 "OPEN_SUNSHADE" 4 "TILTUP_GLASS" 3 "STOP_GLASS" 2 "CLOSE_GLASS" 1 "OPEN_GLASS" 0 "NO_CMD" ;
VAL_ 476 ivi_sunroofRollshadeCtrlSelect 2 "Rollshade" 1 "Sunroof" 0 "NO Request" ;
VAL_ 476 ivi_tailgateCtrl 3 "STOP" 2 "OPEN" 1 "CLOSE" 0 "NO_COMMAND" ;
VAL_ 476 IVI_FLReadLightReq 2 "ON" 1 "OFF" 0 "No request" ;
VAL_ 476 IVI_FRReadLightReq 2 "ON" 1 "OFF" 0 "No request" ;
VAL_ 476 IVI_RLReadLightReq 2 "ON" 1 "OFF" 0 "No request" ;
VAL_ 476 IVI_RReadLightReq 2 "ON" 1 "OFF" 0 "No request" ;
VAL_ 476 IVI_ITLToplampReq 2 "ON" 1 "OFF" 0 "No request" ;
VAL_ 476 ivi_languageSet 3 "NO_COMMAND" 2 "RESERVED" 1 "ENGLISH" 0 "SIMPLIFIED_CHINESE" ;
VAL_ 476 ivi_unitSet 3 "INVALID" 2 "NO  Request" 1 "MILE" 0 "KM" ;
VAL_ 476 ivi_OutsideLockAlarmFormSet 3 "No Request" 2 "Reserved" 1 "Only Vision" 0 "Vision+Voice" ;
VAL_ 1240 ic_tripmeterA 16383 "Invalid" ;
VAL_ 1240 ic_maintenanceInd 1 "INDICATION" 0 "NO_INDICATION" ;
VAL_ 1240 ic_tripmeterB 16777215 "Invalid" ;
VAL_ 1240 IC_ChargingPower 8191 "Invalid" ;
VAL_ 1240 IC_ChargingSpeed 2047 "Invalid" ;
VAL_ 290 IPB_wheelSpeedRL 8191 "Invalid" ;
VAL_ 290 IPB_wheelSpeedRLValid 1 "VALID" 0 "INVALID" ;
VAL_ 290 IPB_wheelSpeedRR 8191 "Invalid" ;
VAL_ 290 IPB_wheelSpeedRRValid 1 "VALID" 0 "INVALID" ;
VAL_ 322 IPB_wheelSpeedFL 8191 "Invalid" ;
VAL_ 322 IPB_wheelSpeedFLValid 1 "VALID" 0 "INVALID" ;
VAL_ 322 IPB_wheelSpeedFR 8191 "Invalid" ;
VAL_ 322 IPB_wheelSpeedFRValid 1 "VALID" 0 "INVALID" ;
VAL_ 160 IPB_vehicleSpeed 8191 "Invalid" ;
VAL_ 160 IPB_vehicleSpeedValid 1 "VALID" 0 "INVALID" ;
VAL_ 160 IPB_absFault 1 "FAULT" 0 "NORMAL" ;
VAL_ 160 IPB_absActive 1 "ACTIVE" 0 "INACTIVE" ;
VAL_ 160 IPB_vdcActive 1 "ACTIVE" 0 "INACTIVE" ;
VAL_ 160 IPB_tcsActive 1 "ACTIVE" 0 "INACTIVE" ;
VAL_ 160 IPB_avhModeWSts 3 "SecondFootMode and Active" 2 "AutoHoldMode and Active" 1 "SecondFootMode and STANDBY" 0 "AutoHoldMode and STANDBY" ;
VAL_ 160 IPB_avhAvailable 1 "AVAILABLE" 0 "NOT_AVAILABLE" ;
VAL_ 160 IPB_cdpActive 1 "ACTIVE" 0 "INACTIVE" ;
VAL_ 160 IPB_cdpAvailable 1 "AVAILABLE" 0 "NOT_AVAILABLE" ;
VAL_ 160 IPB_hdcAvailable 1 "AVAILABLE" 0 "NOT_AVAILABLE" ;
VAL_ 160 IPB_epbRequest 2 "RELEASE" 1 "APPLY" 0 "NO_COMMAND" ;
VAL_ 160 IPB_vehicleStandstill 2 "RESERVED" 1 "STANDSTILL" 0 "NOT_STANDSTILL" ;
VAL_ 160 IPB_vehicleStandstillValid 1 "VALID" 0 "INVALID" ;
VAL_ 160 IPB_ModeSts 1 "SPORT" 0 "COMFORT" ;
VAL_ 160 IPB_brakelightRequest 1 "ILLUMINATE" 0 "NOT_ILLUMINATE" ;
VAL_ 160 IPB_hdcSts 3 "Reserved" 2 "On active braking" 1 "On not active braking" 0 "OFF" ;
VAL_ 160 IPB_hhcActive 1 "ACTIVE" 0 "INACTIVE" ;
VAL_ 160 IPB_hhcAvailable 1 "AVAILABLE" 0 "NOT_AVAILABLE" ;
VAL_ 160 IPB_ebdFault 1 "FAULT" 0 "NOMAL" ;
VAL_ 160 IPB_ebd_active 1 "Active" 0 "Not active" ;
VAL_ 160 IPB_ESCoffSts 1 "ON" 0 "OFF" ;
VAL_ 160 IPB_escFault 1 "FAULT" 0 "NOMAL" ;
VAL_ 160 IPB_haz_active 1 "ACTIVE" 0 "INACTIVE" ;
VAL_ 160 IPB_hazErrorSt 1 "Error" 0 "No error" ;
VAL_ 160 IPB_hba_active 1 "Active" 0 "Not active" ;
VAL_ 160 IPB_dtcActive 1 "ACTIVE" 0 "INACTIVE" ;
VAL_ 160 IPB_esclampdisplay 2 "ESP lamp FLASH" 1 "ESP lamp OFF" 0 "ESP lamp ON" ;
VAL_ 160 IPB_BDWActive 1 "ACTIVE" 0 "INACTIVE" ;
VAL_ 160 IPB_HRBActive 1 "ACTIVE" 0 "INACTIVE" ;
VAL_ 626 IPB_sumOfEdgeFLWSSValid 1 "VALID" 0 "INVALID" ;
VAL_ 626 IPB_sumOfEdgeFRWSSValid 1 "VALID" 0 "INVALID" ;
VAL_ 626 IPB_wheelDirectionFLValid 1 "VALID" 0 "INVALID" ;
VAL_ 626 IPB_wheelDirectionFRValid 1 "VALID" 0 "INVALID" ;
VAL_ 626 IPB_wheelDirectionFL 3 "STOP" 2 "REVERSE" 1 "FORWARD" 0 "INVALID" ;
VAL_ 626 IPB_wheelDirectionFR 3 "STOP" 2 "REVERSE" 1 "FORWARD" 0 "INVALID" ;
VAL_ 626 IPB_vehicleDirection 3 "Backword" 2 "Standstill" 1 "Forward" 0 "Unknown" ;
VAL_ 642 IPB_sumOfEdgeRLWSSValid 1 "VALID" 0 "INVALID" ;
VAL_ 642 IPB_sumOfEdgeRRWSSValid 1 "VALID" 0 "INVALID" ;
VAL_ 642 IPB_wheelDirectionRLValid 1 "VALID" 0 "INVALID" ;
VAL_ 642 IPB_wheelDirectionRRValid 1 "VALID" 0 "INVALID" ;
VAL_ 642 IPB_wheelDirectionRL 3 "STOP" 2 "REVERSE" 1 "FORWARD" 0 "INVALID" ;
VAL_ 642 IPB_wheelDirectionRR 3 "STOP" 2 "REVERSE" 1 "FORWARD" 0 "INVALID" ;
VAL_ 1274 gw_vin_frame 7 "Reserved" 6 "Reserved" 5 "Reserved" 4 "Reserved" 3 "Third Frame" 2 "Second Frame" 1 "First Frame" 0 "Default" ;
VAL_ 1278 tbox_vehicleMode 15 "Invalid" 14 "Reserved" 13 "Reserved" 12 "Reserved" 11 "Reserved" 10 "Reserved" 9 "Reserved" 8 "Reserved" 7 "Reserved" 6 "Reserved" 5 "OTA mode" 4 "Collision mode (Reserved)" 3 "Transportation mode (Reserved)" 2 "Factory mode" 1 "Normal mode" 0 "Initial value" ;
VAL_ 1278 TBOX_OTAEnergyCtl 15 "Reserved" 14 "Reserved" 13 "Reserved" 12 "Reserved" 11 "Reserved" 10 "Reserved" 9 "Reserved" 8 "Reserved" 7 "Reserved" 6 "Reserved" 5 "Reserved" 4 "Reserved" 3 "Reserved" 2 "Power down request" 1 "Power on request" 0 "Inactive" ;
VAL_ 126 tbox_reservationChargeMode 1 "Cycle" 0 "No Cycle" ;
VAL_ 126 tbox_SysErSt 3 "Reserved" 2 "Serious Fault" 1 "Minor Fault" 0 "Noraml" ;
VAL_ 126 TBOX_ChargeContinueSta 3 "RESERVE" 2 "ON" 1 "OFF" 0 "Init" ;
VAL_ 126 TBOX_ChargeStart 1 "START" 0 "NO REQUEST" ;
VAL_ 126 tbox_chargeSetValid_Reserved 1 "VALID" 0 "INVALID" ;
VAL_ 126 tbox_MaxChargeCurrentSet 63 "Invalid" ;
VAL_ 126 tbox_ChargeFormSet 3 "RESERVE_CHRGFORM1" 2 "TIMING_CHARGE" 1 "IMMEDIATE_CHARGE" 0 "NO_REQUEST" ;
VAL_ 126 tbox_ChargeEndTimeHalfDay 1 "AFTERNOON" 0 "MORNING" ;
VAL_ 126 tbox_ChargeEndTimeHour 15 "Invalid" 12 "12" 11 "11" 10 "10" 9 "9" 8 "8" 7 "7" 6 "6" 5 "5" 4 "4" 3 "3" 2 "2" 1 "1" 0 "Reserved" ;
VAL_ 126 tbox_remoteVehicleForbiddenStart 3 "INVALID" 2 "Forbidden Start" 1 "Start" 0 "NO_REQUEST" ;
VAL_ 126 tbox_ChargeEndTimeMinute 63 "Invalid" ;
VAL_ 126 tbox_ChargeCancel 1 "CANCEL" 0 "NO_REQUEST" ;
VAL_ 126 tbox_ChargeEnable 1 "ENABLE" 0 "NO_REQUEST" ;
VAL_ 126 tbox_ChargeStartTimeHalfDay 1 "AFTERNOON" 0 "MORNING" ;
VAL_ 126 tbox_ChargeStartTimeHour 15 "Invalid" 12 "12" 11 "11" 10 "10" 9 "9" 8 "8" 7 "7" 6 "6" 5 "5" 4 "4" 3 "3" 2 "2" 1 "1" 0 "Reserved" ;
VAL_ 126 tbox_EmergencyHvOffReq 1 "REQUEST" 0 "NO_REQUEST" ;
VAL_ 126 tbox_eCallSts 3 "通话失败" 2 "已接听" 1 "拨打中" 0 "通话结束" ;
VAL_ 126 tbox_BatteryCondition_Reserved 1 "ENABLE" 0 "DISABLE" ;
VAL_ 126 tbox_MaxChargeSOCSet 127 "Invalid" ;
VAL_ 126 tbox_ChargeEndTimeValid 1 "VALID" 0 "INVALID" ;
VAL_ 126 tbox_ChargeStartTimeValid 1 "VALID" 0 "INVALID" ;
VAL_ 126 tbox_ChargeSetEnable 1 "Enable" 0 "Disable" ;
VAL_ 126 tbox_remoteengStartCmd 1 "Request" 0 "No Request" ;
VAL_ 126 SENTRY_VedioSwitchSet 2 "CLOSE" 1 "OPEN" 0 "DEFAULT" ;
VAL_ 126 tbox_ultrasocengStartCmd 1 "Authorized" 0 "Unauthorized" ;
VAL_ 714 OBC_ACPlug_Status 7 "Reserved" 6 "V2L 3.6KW Connected" 5 "V2L 2.2KW Connected" 4 "Fault" 3 "Connected；" 2 "Half: Connected；" 1 "Disconnected；" 0 "Init；" ;
VAL_ 714 OBC_CC_MaxCurrent 9 "Fault；" 8 "V2G: 32A；" 7 "V2L: 16A；" 6 "63A；" 5 "32A；" 4 "V2L: 10A；" 3 "16A；" 2 "13A；" 1 "10A；" 0 "Init；" ;
VAL_ 714 OBC_CC_Fault_Status 3 "Reserve；" 2 "Shorted: to: GND；" 1 "Open: Circuit；" 0 "Init；" ;
VAL_ 714 OBC_CC_Resistance 7 "2000R；" 6 "Fault；" 5 "2700R；" 4 "100R；" 3 "220R；" 2 "680R；" 1 "1500R；" 0 "Init；" ;
VAL_ 714 OBC_S2_Status 3 "Fault；" 2 "Closed；" 1 "Open；" 0 "Init；" ;
VAL_ 714 OBC_CP_Duty 127 "Fault；" 126 "Init；" ;
VAL_ 714 OBC_CP_Frequency 255 "Fault；" 254 "Init；" ;
VAL_ 714 OBC_CP_Fault_Status 3 "CP: Out: Of: Range；" 2 "Shorted: to: GND；" 1 "Open: Circuit；" 0 "Init；" ;
VAL_ 714 OBC_CP_Status 7 "CP: Fault；" 6 "Reserve；" 5 "12V；" 4 "6V: PWM；" 3 "6V；" 2 "9V: PWM；" 1 "9V；" 0 "Init" ;
VAL_ 714 OBC_Phase_Mode 3 "Reserve；" 2 "Three_phase；" 1 "Single_phase_L1；" 0 "Init；" ;
VAL_ 716 OBC_Frequency_AC 511 "Invalid" ;
VAL_ 716 OBC_Max_Current_AC 255 "Invalid" ;
VAL_ 716 OBC_AC_Current_L1 1023 "Invalid" ;
VAL_ 716 OBC_AC_Current_L2 1023 "Invalid" ;
VAL_ 716 OBC_AC_Current_L3 1023 "Invalid" ;
VAL_ 719 OBC_ActualCurrent_DC 2047 "Invalid" ;
VAL_ 719 OBC_ActualVoltage_DC 4095 "Invalid" ;
VAL_ 719 OBC_MaxCurrent_Output 2047 "Invalid" ;
VAL_ 719 OBC_Efficiency 1023 "Invalid" ;
VAL_ 719 OBC_Derating 3 "Derating_External；" 2 "Derating_Internal；" 1 "Derating_Tempreture；" 0 "Normal；" ;
VAL_ 719 OBC_AcChgEnergy 2048 "Invalid" ;
VAL_ 736 OBC_AC_PlugTemp_Status_L1 3 "Reserve；" 2 "Shorted: to: GND；" 1 "Open: Circuit；" 0 "Init；" ;
VAL_ 736 OBC_AC_PlugTemp_Status_L2 3 "Reserve；" 2 "Shorted: to: GND；" 1 "Open: Circuit；" 0 "Init；" ;
VAL_ 736 OBC_AC_PlugTemp_Status_L3 3 "Reserve；" 2 "Shorted: to: GND；" 1 "Open: Circuit；" 0 "Init；" ;
VAL_ 736 OBC_AC_PlugTemp_Status_N 3 "Reserve；" 2 "Shorted: to: GND；" 1 "Open: Circuit；" 0 "Init；" ;
VAL_ 736 OBC_AC_Voltage_L1 511 "Fault；" 510 "Init；" ;
VAL_ 736 OBC_AC_Voltage_L2 511 "Fault；" 510 "Init；" ;
VAL_ 736 OBC_AC_Voltage_L3 511 "Fault；" 510 "Init；" ;
VAL_ 736 OBC_Temperature_Internal 255 "Fault；" 254 "Init；" ;
VAL_ 738 OBC_Coolant_Temperature 255 "Fault；" 254 "Init；" ;
VAL_ 738 OBC_Status 15 "Fault；" 8 "Reserve" 7 "Reserve；" 6 "END；" 5 "V2G；" 4 "V2L" 3 "Charging_CV；" 2 "Charging_CC；" 1 "Standby；" 0 "Init；" ;
VAL_ 738 OBC_PlugLock_Action 3 "Reserve；" 2 "Unlock: Action；" 1 "Lock: Action；" 0 "Init；" ;
VAL_ 738 OBC_PlugLock_Status 3 "Fault；" 2 "Unlocked；" 1 "Locked；" 0 "Init；" ;
VAL_ 738 OBC_Message_standard 3 "Reserve；" 2 "CANFD；" 1 "CAN 2.0；" 0 "Init；" ;
VAL_ 738 OBC_HPC_Lock_Status 3 "Fault；" 2 "Unlocked；" 1 "Locked；" 0 "Init；" ;
VAL_ 738 OBC_Standard 3 "Reserve；" 2 "Europe；" 1 "US；" 0 "China；" ;
VAL_ 738 OBC_Fault_Status 1 "Fault；" 0 "No: Fault；" ;
VAL_ 738 OBC_OBD_Lamp_Req 1 "MIL request" 0 "No Request" ;
VAL_ 740 DCDC_Voltage_HV 4095 "Invalid" ;
VAL_ 740 DCDC_Current_HV 1023 "Invalid" ;
VAL_ 740 DCDC_Voltage_LV 255 "Invalid" ;
VAL_ 740 DCDC_Current_LV 1023 "Invalid" ;
VAL_ 865 OBC_AC_PlugTemp_L1 255 "Fault；" 254 "Init；" ;
VAL_ 865 OBC_AC_PlugTemp_L2 255 "Fault；" 254 "Init；" ;
VAL_ 865 OBC_AC_PlugTemp_L3 255 "Fault；" 254 "Init；" ;
VAL_ 865 OBC_AC_PlugTemp_N 255 "Fault；" 254 "Init；" ;
VAL_ 888 BMS_RtmWarn_PackCom 3 "Fault_level_3" 2 "Fault_level_2" 1 "Fault_level_1" 0 "no Fault" ;
VAL_ 888 BMS_RtmWarn_PackOverCharge 3 "Fault_level_3" 2 "Fault_level_2" 1 "Fault_level_1" 0 "no Fault" ;
VAL_ 888 BMS_RtmWarn_SOCHigh 3 "Fault_level_3" 2 "Fault_level_2" 1 "Fault_level_1" 0 "no Fault" ;
VAL_ 888 BMS_RtmWarn_SOCLow 3 "Fault_level_3" 2 "Fault_level_2" 1 "Fault_level_1" 0 "no Fault" ;
VAL_ 888 BMS_RtmWarn_SOCSprung 3 "Fault_level_3" 2 "Fault_level_2" 1 "Fault_level_1" 0 "no Fault" ;
VAL_ 888 BMS_RtmWarn_TempCellDiff 3 "Fault_level_3" 2 "Fault_level_2" 1 "Fault_level_1" 0 "no Fault" ;
VAL_ 888 BMS_RtmWarn_TempCellMax 3 "Fault_level_3" 2 "Fault_level_2" 1 "Fault_level_1" 0 "no Fault" ;
VAL_ 888 BMS_RtmWarn_TempCellMin 3 "Fault_level_3" 2 "Fault_level_2" 1 "Fault_level_1" 0 "no Fault" ;
VAL_ 888 BMS_RtmWarn_OverCurrent 3 "Fault_level_3" 2 "Fault_level_2" 1 "Fault_level_1" 0 "no Fault" ;
VAL_ 888 BMS_RtmWarn_UPackMax 3 "Fault_level_3" 2 "Fault_level_2" 1 "Fault_level_1" 0 "no Fault" ;
VAL_ 888 BMS_RtmWarn_UPackMin 3 "Fault_level_3" 2 "Fault_level_2" 1 "Fault_level_1" 0 "no Fault" ;
VAL_ 888 BMS_RtmWarn_UCellMax 3 "Fault_level_3" 2 "Fault_level_2" 1 "Fault_level_1" 0 "no Fault" ;
VAL_ 888 BMS_RtmWarn_UCellMin 3 "Fault_level_3" 2 "Fault_level_2" 1 "Fault_level_1" 0 "no Fault" ;
VAL_ 888 BMS_RtmWarn_UCellDiff 3 "Fault_level_3" 2 "Fault_level_2" 1 "Fault_level_1" 0 "no Fault" ;
VAL_ 889 BMS_Pack_SN_01 255 "init" ;
VAL_ 889 BMS_Pack_SN_02 255 "init" ;
VAL_ 889 BMS_Pack_SN_03 255 "init" ;
VAL_ 889 BMS_Pack_SN_04 255 "init" ;
VAL_ 889 BMS_Pack_SN_05 255 "init" ;
VAL_ 889 BMS_Pack_SN_06 255 "init" ;
VAL_ 889 BMS_Pack_SN_07 255 "init" ;
VAL_ 889 BMS_Pack_SN_Index 0 "init" ;
VAL_ 922 BMS_SW_Version_VehicleType 1 "PHEV" 0 "EV" ;
VAL_ 922 BMS_SW_Version_ReleaseType 1 "Released Version" 0 "Test Version" ;
VAL_ 923 BMS_FaultCode_Internal 16383 "Invalid" ;
VAL_ 923 BMS_AC_StopReason 16383 "Invalid" ;
VAL_ 923 BMS_HeatingRate 127 "Invalid" ;
VAL_ 923 BMS_Capacity_Max 2047 "Invalid" ;
VAL_ 927 BMS_ProbeTemp1 255 "Invalid" 254 "异常" ;
VAL_ 927 BMS_ProbeTemp2 255 "Invalid" 254 "异常" ;
VAL_ 927 BMS_ProbeTemp3 255 "Invalid" 254 "异常" ;
VAL_ 927 BMS_ProbeTemp4 255 "Invalid" 254 "异常" ;
VAL_ 927 BMS_ProbeTemp5 255 "Invalid" 254 "异常" ;
VAL_ 927 BMS_ProbeTemp6 255 "Invalid" 254 "异常" ;
VAL_ 927 BMS_ProbeTemp7 255 "Invalid" 254 "异常" ;
VAL_ 927 BMS_ProbeTemp8 255 "Invalid" 254 "异常" ;
VAL_ 928 BMS_ProbeTemp9 255 "Invalid" 254 "异常" ;
VAL_ 928 BMS_ProbeTemp10 255 "Invalid" 254 "异常" ;
VAL_ 928 BMS_ProbeTemp11 255 "Invalid" 254 "异常" ;
VAL_ 928 BMS_ProbeTemp12 255 "Invalid" 254 "异常" ;
VAL_ 928 BMS_ProbeTemp13 255 "Invalid" 254 "异常" ;
VAL_ 928 BMS_ProbeTemp14 255 "Invalid" 254 "异常" ;
VAL_ 928 BMS_ProbeTemp15 255 "Invalid" 254 "异常" ;
VAL_ 928 BMS_ProbeTemp16 255 "Invalid" 254 "异常" ;
VAL_ 930 BMS_ProbeTemp17 255 "Invalid" 254 "异常" ;
VAL_ 930 BMS_ProbeTemp18 255 "Invalid" 254 "异常" ;
VAL_ 930 BMS_ProbeTemp19 255 "Invalid" 254 "异常" ;
VAL_ 930 BMS_ProbeTemp20 255 "Invalid" 254 "异常" ;
VAL_ 930 BMS_ProbeTemp21 255 "Invalid" 254 "异常" ;
VAL_ 930 BMS_ProbeTemp22 255 "Invalid" 254 "异常" ;
VAL_ 930 BMS_ProbeTemp23 255 "Invalid" 254 "异常" ;
VAL_ 930 BMS_ProbeTemp24 255 "Invalid" 254 "异常" ;
VAL_ 931 BMS_ProbeTemp25 255 "Invalid" 254 "异常" ;
VAL_ 931 BMS_ProbeTemp26 255 "Invalid" 254 "异常" ;
VAL_ 931 BMS_ProbeTemp27 255 "Invalid" 254 "异常" ;
VAL_ 931 BMS_ProbeTemp28 255 "Invalid" 254 "异常" ;
VAL_ 931 BMS_ProbeTemp29 255 "Invalid" 254 "异常" ;
VAL_ 931 BMS_ProbeTemp30 255 "Invalid" 254 "异常" ;
VAL_ 931 BMS_ProbeTemp31 255 "Invalid" 254 "异常" ;
VAL_ 931 BMS_ProbeTemp32 255 "Invalid" 254 "异常" ;
VAL_ 933 BMS_ProbeTemp33 255 "Invalid" 254 "异常" ;
VAL_ 933 BMS_ProbeTemp34 255 "Invalid" 254 "异常" ;
VAL_ 933 BMS_ProbeTemp35 255 "Invalid" 254 "异常" ;
VAL_ 933 BMS_ProbeTemp36 255 "Invalid" 254 "异常" ;
VAL_ 933 BMS_ProbeTemp37 255 "Invalid" 254 "异常" ;
VAL_ 933 BMS_ProbeTemp38 255 "Invalid" 254 "异常" ;
VAL_ 933 BMS_ProbeTemp39 255 "Invalid" 254 "异常" ;
VAL_ 933 BMS_ProbeTemp40 255 "Invalid" 254 "异常" ;
VAL_ 935 BMS_ProbeTemp41 255 "Invalid" 254 "异常" ;
VAL_ 935 BMS_ProbeTemp42 255 "Invalid" 254 "异常" ;
VAL_ 935 BMS_ProbeTemp43 255 "Invalid" 254 "异常" ;
VAL_ 935 BMS_ProbeTemp44 255 "Invalid" 254 "异常" ;
VAL_ 935 BMS_ProbeTemp45 255 "Invalid" 254 "异常" ;
VAL_ 935 BMS_ProbeTemp46 255 "Invalid" 254 "异常" ;
VAL_ 935 BMS_ProbeTemp47 255 "Invalid" 254 "异常" ;
VAL_ 935 BMS_ProbeTemp48 255 "Invalid" 254 "异常" ;
VAL_ 940 BMS_BattCellVolt1 65535 "Invalid" 65534 "异常" ;
VAL_ 940 BMS_BattCellVolt2 65535 "Invalid" 65534 "异常" ;
VAL_ 940 BMS_BattCellVolt3 65535 "Invalid" 65534 "异常" ;
VAL_ 940 BMS_BattCellVolt4 65535 "Invalid" 65534 "异常" ;
VAL_ 939 BMS_BattCellVolt5 65535 "Invalid" 65534 "异常" ;
VAL_ 939 BMS_BattCellVolt6 65535 "Invalid" 65534 "异常" ;
VAL_ 939 BMS_BattCellVolt7 65535 "Invalid" 65534 "异常" ;
VAL_ 939 BMS_BattCellVolt8 65535 "Invalid" 65534 "异常" ;
VAL_ 943 BMS_BattCellVolt9 65535 "Invalid" 65534 "异常" ;
VAL_ 943 BMS_BattCellVolt10 65535 "Invalid" 65534 "异常" ;
VAL_ 943 BMS_BattCellVolt11 65535 "Invalid" 65534 "异常" ;
VAL_ 943 BMS_BattCellVolt12 65535 "Invalid" 65534 "异常" ;
VAL_ 942 BMS_BattCellVolt13 65535 "Invalid" 65534 "异常" ;
VAL_ 942 BMS_BattCellVolt14 65535 "Invalid" 65534 "异常" ;
VAL_ 942 BMS_BattCellVolt15 65535 "Invalid" 65534 "异常" ;
VAL_ 942 BMS_BattCellVolt16 65535 "Invalid" 65534 "异常" ;
VAL_ 945 BMS_BattCellVolt17 65535 "Invalid" 65534 "异常" ;
VAL_ 945 BMS_BattCellVolt18 65535 "Invalid" 65534 "异常" ;
VAL_ 945 BMS_BattCellVolt19 65535 "Invalid" 65534 "异常" ;
VAL_ 945 BMS_BattCellVolt20 65535 "Invalid" 65534 "异常" ;
VAL_ 947 BMS_BattCellVolt21 65535 "Invalid" 65534 "异常" ;
VAL_ 947 BMS_BattCellVolt22 65535 "Invalid" 65534 "异常" ;
VAL_ 947 BMS_BattCellVolt23 65535 "Invalid" 65534 "异常" ;
VAL_ 947 BMS_BattCellVolt24 65535 "Invalid" 65534 "异常" ;
VAL_ 948 BMS_BattCellVolt25 65535 "Invalid" 65534 "异常" ;
VAL_ 948 BMS_BattCellVolt26 65535 "Invalid" 65534 "异常" ;
VAL_ 948 BMS_BattCellVolt27 65535 "Invalid" 65534 "异常" ;
VAL_ 948 BMS_BattCellVolt28 65535 "Invalid" 65534 "异常" ;
VAL_ 951 BMS_BattCellVolt29 65535 "Invalid" 65534 "异常" ;
VAL_ 951 BMS_BattCellVolt30 65535 "Invalid" 65534 "异常" ;
VAL_ 951 BMS_BattCellVolt31 65535 "Invalid" 65534 "异常" ;
VAL_ 951 BMS_BattCellVolt32 65535 "Invalid" 65534 "异常" ;
VAL_ 953 BMS_BattCellVolt33 65535 "Invalid" 65534 "异常" ;
VAL_ 953 BMS_BattCellVolt34 65535 "Invalid" 65534 "异常" ;
VAL_ 953 BMS_BattCellVolt35 65535 "Invalid" 65534 "异常" ;
VAL_ 953 BMS_BattCellVolt36 65535 "Invalid" 65534 "异常" ;
VAL_ 954 BMS_BattCellVolt37 65535 "Invalid" 65534 "异常" ;
VAL_ 954 BMS_BattCellVolt38 65535 "Invalid" 65534 "异常" ;
VAL_ 954 BMS_BattCellVolt39 65535 "Invalid" 65534 "异常" ;
VAL_ 954 BMS_BattCellVolt40 65535 "Invalid" 65534 "异常" ;
VAL_ 956 BMS_BattCellVolt41 65535 "Invalid" 65534 "异常" ;
VAL_ 956 BMS_BattCellVolt42 65535 "Invalid" 65534 "异常" ;
VAL_ 956 BMS_BattCellVolt43 65535 "Invalid" 65534 "异常" ;
VAL_ 956 BMS_BattCellVolt44 65535 "Invalid" 65534 "异常" ;
VAL_ 958 BMS_BattCellVolt45 65535 "Invalid" 65534 "异常" ;
VAL_ 958 BMS_BattCellVolt46 65535 "Invalid" 65534 "异常" ;
VAL_ 958 BMS_BattCellVolt47 65535 "Invalid" 65534 "异常" ;
VAL_ 958 BMS_BattCellVolt48 65535 "Invalid" 65534 "异常" ;
VAL_ 959 BMS_BattCellVolt49 65535 "Invalid" 65534 "异常" ;
VAL_ 959 BMS_BattCellVolt50 65535 "Invalid" 65534 "异常" ;
VAL_ 959 BMS_BattCellVolt51 65535 "Invalid" 65534 "异常" ;
VAL_ 959 BMS_BattCellVolt52 65535 "Invalid" 65534 "异常" ;
VAL_ 961 BMS_BattCellVolt53 65535 "Invalid" 65534 "异常" ;
VAL_ 961 BMS_BattCellVolt54 65535 "Invalid" 65534 "异常" ;
VAL_ 961 BMS_BattCellVolt55 65535 "Invalid" 65534 "异常" ;
VAL_ 961 BMS_BattCellVolt56 65535 "Invalid" 65534 "异常" ;
VAL_ 963 BMS_BattCellVolt57 65535 "Invalid" 65534 "异常" ;
VAL_ 963 BMS_BattCellVolt58 65535 "Invalid" 65534 "异常" ;
VAL_ 963 BMS_BattCellVolt59 65535 "Invalid" 65534 "异常" ;
VAL_ 963 BMS_BattCellVolt60 65535 "Invalid" 65534 "异常" ;
VAL_ 965 BMS_BattCellVolt61 65535 "Invalid" 65534 "异常" ;
VAL_ 965 BMS_BattCellVolt62 65535 "Invalid" 65534 "异常" ;
VAL_ 965 BMS_BattCellVolt63 65535 "Invalid" 65534 "异常" ;
VAL_ 965 BMS_BattCellVolt64 65535 "Invalid" 65534 "异常" ;
VAL_ 967 BMS_BattCellVolt65 65535 "Invalid" 65534 "异常" ;
VAL_ 967 BMS_BattCellVolt66 65535 "Invalid" 65534 "异常" ;
VAL_ 967 BMS_BattCellVolt67 65535 "Invalid" 65534 "异常" ;
VAL_ 967 BMS_BattCellVolt68 65535 "Invalid" 65534 "异常" ;
VAL_ 969 BMS_BattCellVolt69 65535 "Invalid" 65534 "异常" ;
VAL_ 969 BMS_BattCellVolt70 65535 "Invalid" 65534 "异常" ;
VAL_ 969 BMS_BattCellVolt71 65535 "Invalid" 65534 "异常" ;
VAL_ 969 BMS_BattCellVolt72 65535 "Invalid" 65534 "异常" ;
VAL_ 970 BMS_BattCellVolt73 65535 "Invalid" 65534 "异常" ;
VAL_ 970 BMS_BattCellVolt74 65535 "Invalid" 65534 "异常" ;
VAL_ 970 BMS_BattCellVolt75 65535 "Invalid" 65534 "异常" ;
VAL_ 970 BMS_BattCellVolt76 65535 "Invalid" 65534 "异常" ;
VAL_ 972 BMS_BattCellVolt77 65535 "Invalid" 65534 "异常" ;
VAL_ 972 BMS_BattCellVolt78 65535 "Invalid" 65534 "异常" ;
VAL_ 972 BMS_BattCellVolt79 65535 "Invalid" 65534 "异常" ;
VAL_ 972 BMS_BattCellVolt80 65535 "Invalid" 65534 "异常" ;
VAL_ 974 BMS_BattCellVolt81 65535 "Invalid" 65534 "异常" ;
VAL_ 974 BMS_BattCellVolt82 65535 "Invalid" 65534 "异常" ;
VAL_ 974 BMS_BattCellVolt83 65535 "Invalid" 65534 "异常" ;
VAL_ 974 BMS_BattCellVolt84 65535 "Invalid" 65534 "异常" ;
VAL_ 975 BMS_BattCellVolt85 65535 "Invalid" 65534 "异常" ;
VAL_ 975 BMS_BattCellVolt86 65535 "Invalid" 65534 "异常" ;
VAL_ 975 BMS_BattCellVolt87 65535 "Invalid" 65534 "异常" ;
VAL_ 975 BMS_BattCellVolt88 65535 "Invalid" 65534 "异常" ;
VAL_ 977 BMS_BattCellVolt89 65535 "Invalid" 65534 "异常" ;
VAL_ 977 BMS_BattCellVolt90 65535 "Invalid" 65534 "异常" ;
VAL_ 977 BMS_BattCellVolt91 65535 "Invalid" 65534 "异常" ;
VAL_ 977 BMS_BattCellVolt92 65535 "Invalid" 65534 "异常" ;
VAL_ 979 BMS_BattCellVolt93 65535 "Invalid" 65534 "异常" ;
VAL_ 979 BMS_BattCellVolt94 65535 "Invalid" 65534 "异常" ;
VAL_ 979 BMS_BattCellVolt95 65535 "Invalid" 65534 "异常" ;
VAL_ 979 BMS_BattCellVolt96 65535 "Invalid" 65534 "异常" ;
VAL_ 981 BMS_BattCellVolt97 65535 "Invalid" 65534 "异常" ;
VAL_ 981 BMS_BattCellVolt98 65535 "Invalid" 65534 "异常" ;
VAL_ 981 BMS_BattCellVolt99 65535 "Invalid" 65534 "异常" ;
VAL_ 981 BMS_BattCellVolt100 65535 "Invalid" 65534 "异常" ;
VAL_ 984 BMS_BattCellVolt101 65535 "Invalid" 65534 "异常" ;
VAL_ 984 BMS_BattCellVolt102 65535 "Invalid" 65534 "异常" ;
VAL_ 984 BMS_BattCellVolt103 65535 "Invalid" 65534 "异常" ;
VAL_ 984 BMS_BattCellVolt104 65535 "Invalid" 65534 "异常" ;
VAL_ 989 BMS_BattCellVolt105 65535 "Invalid" 65534 "异常" ;
VAL_ 989 BMS_BattCellVolt106 65535 "Invalid" 65534 "异常" ;
VAL_ 989 BMS_BattCellVolt107 65535 "Invalid" 65534 "异常" ;
VAL_ 989 BMS_BattCellVolt108 65535 "Invalid" 65534 "异常" ;
VAL_ 986 BMS_BattCellVolt109 65535 "Invalid" 65534 "异常" ;
VAL_ 986 BMS_BattCellVolt110 65535 "Invalid" 65534 "异常" ;
VAL_ 986 BMS_BattCellVolt111 65535 "Invalid" 65534 "异常" ;
VAL_ 986 BMS_BattCellVolt112 65535 "Invalid" 65534 "异常" ;
VAL_ 1220 PDCM_BattEnergyAvaliable 2047 "Invalid" ;
VAL_ 1220 PDCM_oilRemainingValue 2047 "Invalid" ;
VAL_ 1220 PDCM_oilPercent 1007 "Invalid" ;
VAL_ 1220 PDCM_oilPercentFail 3 "SHORT_POWER_OR_OPEN_CIRCURT" 2 "OUT_RANGE" 1 "SHORT_GROUND" 0 "NORMAL" ;
VAL_ 1221 PDCM_remainingMileageOil_Standard 2047 "Invalid" ;
VAL_ 1221 PDCM_remainingMileageOil_Real 2047 "Invalid" ;
VAL_ 1222 PDCM_TripADistance 16777215 "Invalid" ;
VAL_ 1222 PDCM_TripAAvgPwrConsum 1023 "Invalid" ;
VAL_ 1222 PDCM_TripAAvgSpeed 511 "Invalid" ;
VAL_ 1222 PDCM_TripAAvgOilConsum 255 "Invalid" ;
VAL_ 1222 PDCM_TripALastingTime 8191 "Invalid" ;
VAL_ 1222 PDCM_TripAOilDistance 16777215 "Invalid" ;
VAL_ 1222 PDCM_TripAPwrDistance 16777215 "Invalid" ;
VAL_ 1223 PDCM_totalMilAvgPwrConsum 1023 "Invalid" ;
VAL_ 1223 PDCM_totalMilAvgSpd 511 "Invalid" ;
VAL_ 1223 PDCM_totalMilAvgOilConsum 255 "Invalid" ;
VAL_ 1223 PDCM_totalMilLastingTime 8191 "Invalid" ;
VAL_ 1224 PDCM_CurrentTripDistance 16777215 "Invalid" ;
VAL_ 1224 PDCM_CurrentTripAvgPwrConsum 1023 "Invalid" ;
VAL_ 1224 PDCM_CurrentTripAvgSpd 511 "Invalid" ;
VAL_ 1224 PDCM_CurrentTripAvgOilConsum 255 "Invalid" ;
VAL_ 1224 PDCM_CurrentTripLastingTime 8191 "Invalid" ;
VAL_ 1225 PDCM_SinceChargeDistance 16777215 "Invalid" ;
VAL_ 1225 PDCM_SinceChargeAvgPwrConsum 1023 "Invalid" ;
VAL_ 1225 PDCM_SinceChargeAvgSpd 511 "Invalid" ;
VAL_ 1225 PDCM_SinceChargeAvgOilConsum 255 "Invalid" ;
VAL_ 1225 PDCM_SinceChargeTime 8191 "Invalid" ;
VAL_ 1226 PDCM_SinceRefulDistance 16777215 "Invalid" ;
VAL_ 1226 PDCM_SinceRefulAvgPwrConsum 1023 "Invalid" ;
VAL_ 1226 PDCM_SinceRefulAvgSpd 511 "Invalid" ;
VAL_ 1226 PDCM_SinceRefulAvgOilConsum 255 "Invalid" ;
VAL_ 1226 PDCM_SinceRefulLastingTime 8191 "Invalid" ;
VAL_ 1227 PDCM_CurrentTripDrvCnsPer 1022 "Invalid" ;
VAL_ 1227 PDCM_CurrentTripCabinSoftCnsPer 1022 "Invalid" ;
VAL_ 1227 PDCM_CurrentTripEleCnsPer 1022 "Invalid" ;
VAL_ 1227 PDCM_CurrentTripFuelCnsPer 1022 "Invalid" ;
VAL_ 1227 PDCM_CurrentTripV2LCnsPer 1022 "Invalid" ;
VAL_ 1227 PDCM_CurrentTripOthCnsPer 1022 "Invalid" ;
VAL_ 1228 PDCM_SinceChargeDrvCnsPer 1022 "Invalid" ;
VAL_ 1228 PDCM_SinceChargeCabinSoftCnsPer 1022 "Invalid" ;
VAL_ 1228 PDCM_SinceChargeEleCnsPer 1022 "Invalid" ;
VAL_ 1228 PDCM_SinceChargeFuelCnsPer 1022 "Invalid" ;
VAL_ 1228 PDCM_SinceChargeV2LCnsPer 1022 "Invalid" ;
VAL_ 1228 PDCM_SinceChargeOthCnsPer 1022 "Invalid" ;
VAL_ 1228 PDCM_SinceChargeEVCnsPer 1022 "Invalid" ;
VAL_ 1229 PDCM_SinceRefulDrvCnsPer 1022 "Invalid" ;
VAL_ 1229 PDCM_SinceRefulCabinSoftCnsPer 1022 "Invalid" ;
VAL_ 1229 PDCM_SinceRefulEleCnsPer 1022 "Invalid" ;
VAL_ 1229 PDCM_SinceRefulFuelCnsPer 1022 "Invalid" ;
VAL_ 1229 PDCM_SinceRefulV2LCnsPer 1022 "Invalid" ;
VAL_ 1229 PDCM_SinceRefulOthCnsPer 1022 "Invalid" ;
VAL_ 1229 PDCM_SinceRefulSeriCnsPer 1022 "Invalid" ;
VAL_ 1229 PDCM_SinceRefulParalCnsPer 1022 "Invalid" ;
VAL_ 1230 PDCM_SinceTripADrvCnsPer 1022 "Invalid" ;
VAL_ 1230 PDCM_SinceTripACabinSoftCnsPer 1022 "Invalid" ;
VAL_ 1230 PDCM_SinceTripAEleCnsPer 1022 "Invalid" ;
VAL_ 1230 PDCM_SinceTripAFuelCnsPer 1022 "Invalid" ;
VAL_ 1230 PDCM_SinceTripAV2LCnsPer 1022 "Invalid" ;
VAL_ 1230 PDCM_SinceTripAOthCnsPer 1022 "Invalid" ;
VAL_ 1230 PDCM_SinceTripAEVCnsPer 1022 "Invalid" ;
VAL_ 1230 PDCM_SinceTripASeriCnsPer 1022 "Invalid" ;
VAL_ 1230 PDCM_SinceTripAParalCnsPer 1022 "Invalid" ;
VAL_ 1231 PDCM_DayAvgOilConsum 255 "Invalid" ;
VAL_ 1231 PDCM_DayAvgPwrConsum 1023 "Invalid" ;
VAL_ 1232 PDCM_ConsumpRatioInstantDrv 1535 "Invalid" ;
VAL_ 1232 PDCM_ConsumpRatioInstantSt 1535 "Invalid" ;
VAL_ 1232 PDCM_FuelConsumpDrv 1023 "Invalid" ;
VAL_ 1232 PDCM_FuelConsumpSt 1023 "Invalid" ;
VAL_ 1233 PDCM_totalMileage 16777215 "Invalid" ;
VAL_ 1233 PDCM_totalMileageValid 1 "VALID" 0 "INVALID" ;
VAL_ 1233 PDCM_totalMileageRev 16777215 "Invalid" ;
VAL_ 1253 PDCM_SOCLowAlarmLamp 3 "reserved" 2 "request_level_2" 1 "request_level_1" 0 "no request" ;
VAL_ 791 PDCM_DischargeOverCurrent_Warn 2 "Discharge Current Normal" 1 "Discharge Over Current Warn" 0 "Init" ;
VAL_ 792 PDCM_ExternalLoadPwr 32767 "Invalid" ;
VAL_ 1242 IC_FuelConsump 1023 "Invalid" ;
VAL_ 1242 IC_ConsumpRatioInstant 1023 "Invalid" ;
VAL_ 1242 ic_oilPercent 255 "Invalid" ;
VAL_ 1242 IC_OilRemainingMileage 1023 "Invalid" ;
VAL_ 1242 IC_OilSensorResistance 511 "Invalid" ;
VAL_ 1242 ic_oilPercentFail 3 "SHORT_POWER_OR_OPEN_CIRCURT" 2 "OUT_RANGE" 1 "SHORT_GROUND" 0 "NORMAL" ;
VAL_ 837 LBMS_CellU1 8191 "Invalid" ;
VAL_ 837 LBMS_CellU2 8191 "Invalid" ;
VAL_ 837 LBMS_CellU3 8191 "Invalid" ;
VAL_ 837 LBMS_CellU4 8191 "Invalid" ;
VAL_ 837 LBMS_Cell1UVld 1 "Valid" 0 "Invalid" ;
VAL_ 837 LBMS_Cell2UVld 1 "Valid" 0 "Invalid" ;
VAL_ 837 LBMS_Cell3UVld 1 "Valid" 0 "Invalid" ;
VAL_ 837 LBMS_Cell4UVld 1 "Valid" 0 "Invalid" ;
VAL_ 837 LBMS_PackCurrent 2097151 "Invalid" ;
VAL_ 837 LBMS_PackIntU 32767 "Invalid" ;
VAL_ 837 LBMS_PackExtU 16383 "Invalid" ;
VAL_ 837 LBMS_PackIntUVld 1 "Valid" 0 "Invalid" ;
VAL_ 837 LBMS_PackExtUVld 1 "Valid" 0 "Invalid" ;
VAL_ 837 LBMS_PackT1 255 "Invalid" ;
VAL_ 837 LBMS_PackT2 255 "Invalid" ;
VAL_ 837 LBMS_PackT3 255 "Invalid" ;
VAL_ 837 LBMS_PackT1Vld 1 "Valid" 0 "Invalid" ;
VAL_ 837 LBMS_DisMOSReq 1 "Valid" 0 "Invalid" ;
VAL_ 837 LBMS_PackIntUCal 32767 "Invalid" ;
VAL_ 837 LBMS_PackIntUCalVld 1 "Valid" 0 "Invalid" ;
VAL_ 837 LBMS_PackCurrentVld 1 "Valid" 0 "Invalid" ;
VAL_ 837 LBMS_AHChrgTotlife 0 "Invalid" ;
VAL_ 837 LBMS_AHDisChrgTotlife 0 "Invalid" ;
VAL_ 837 LBMS_AHChrgVld 1 "Valid" 0 "Invalid" ;
VAL_ 837 LBMS_AHDisChrgVld 1 "Valid" 0 "Invalid" ;
VAL_ 837 LBMS_PackT2Vld 1 "Valid" 0 "Invalid" ;
VAL_ 837 LBMS_PackT3Vld 1 "Valid" 0 "Invalid" ;
VAL_ 837 LBMS_DischrgMOST 255 "Invalid" ;
VAL_ 837 LBMS_ChrgCMOST 255 "Invalid" ;
VAL_ 837 LBMS_BalanceTemp 255 "Invalid" ;
VAL_ 837 LBMS_BuckT 255 "Invalid" ;
VAL_ 838 LBMS_SOCVld 1 "Valid" 0 "Invalid" ;
VAL_ 838 LBMS_SOH 127 "Invalid" ;
VAL_ 838 LBMS_ChrgMosSt 1 "Open" 0 "Close" ;
VAL_ 838 LBMS_DischrgMosSt 1 "Open" 0 "Close" ;
VAL_ 838 LBMS_BuckStatus 1 "Open" 0 "Close" ;
VAL_ 838 LBMS_ReChrgReq 7 "Invalid" 6 "Reserved" 5 "Reserved" 4 "Reserved" 3 "InvalidSOCChar Req" 2 "VoltChar Req" 1 "SOCChar Req" 0 "Initial/Default" ;
VAL_ 838 LBMS_WorkSt 7 "Invalid" 6 "Reserved" 5 "Reserved" 4 "Reserved" 3 "Request Charging" 2 "Discharging" 1 "Normal Charging" 0 "Initial/Default" ;
VAL_ 838 LBMS_RealSOC 127 "Invalid" ;
VAL_ 838 LBMS_MOSForcedControlSt 1 "强控" 0 "未强控" ;
VAL_ 838 LBMS_MaxAllwChrgU 32767 "Invalid" ;
VAL_ 838 LBMS_ReqChrgU 32767 "Invalid" ;
VAL_ 838 LBMS_MaxAllwChrgCurrent 2097151 "Invalid" ;
VAL_ 838 LBMS_MaxAllwDischrgCurrent 2097151 "Invalid" ;
VAL_ 838 LBMS_Cell1BalSt 1 "均衡" 0 "不均衡" ;
VAL_ 838 LBMS_Cell2BalSt 1 "均衡" 0 "不均衡" ;
VAL_ 838 LBMS_Cell3BalSt 1 "均衡" 0 "不均衡" ;
VAL_ 838 LBMS_Cell4BalSt 1 "均衡" 0 "不均衡" ;
VAL_ 838 LBMS_SOCCalMod 7 "Invalid" 6 "Reserved" 5 "Reserved" 4 "OCV Dynamic Cal" 3 "OCV Static Cal" 2 "Full Disharge Cal" 1 "Full Charge Cal" 0 "No Cal" ;
VAL_ 838 LBMS_LowSOCWakeupThre 127 "invalid" 126 "Initial Value" ;
VAL_ 838 LBMS_LowUWakeupThre 32767 "Invalid" ;
VAL_ 838 LBMS_ChrgReqCounter 255 "Invalid" ;
VAL_ 838 LBMS_ChargMOSDriU 255 "Invalid" ;
VAL_ 838 LBMS_DisChargMOSDriU 255 "Invalid" ;
VAL_ 838 LBMS_SOC 255 "Invalid" ;
VAL_ 630 SentryModeSt 15 "Reserved" 14 "Reserved" 13 "Reserved" 12 "Reserved" 11 "Reserved" 10 "Reserved" 9 "Reserved" 8 "Reserved" 7 "Reserved" 6 "Reserved" 5 "Reserved" 4 "Reserved" 3 "Reserved" 2 "Reserved" 1 "ON" 0 "OFF" ;
VAL_ 630 MDC_HighvolReq 1 "Request" 0 "No Request" ;
VAL_ 630 MDC_SysState 15 "Reserved" 14 "Reserved" 13 "Reserved" 12 "Reserved" 11 "CampMode" 10 "MovieMode" 9 "NotPowerOffMode" 8 "WaitingMode" 7 "SelfCarWashMode" 6 "ReceptionMode" 5 "VitalityMode" 4 "RearRightNapMode" 3 "RearLeftNapMode" 2 "RearLeftRighNapMode" 1 "FrontNapMode" ;
VAL_ 630 MDC_CoolantfluidReq 3 "Invalid" 2 "reserved" 1 "Request" 0 "No request" ;
VAL_ 630 MDC_CoolingfluidflowRate 15 "Invalid" 14 "3.5L/min" 13 "3.25L/min" 12 "3.0L/min" 11 "2.75L/min" 10 "2.5L/min" 9 "2.25L/min" 8 "2.0L/min" 7 "1.75L/min" 6 "1.5L/min" 5 "1.25L/min" 4 "1.0L/min" 3 "0.75L/min" 2 "0.5L/min" 1 "0.25L/min" 0 "0.0L/min" ;
VAL_ 630 Mdc_ReadyReq 7 "Reserved" 6 "Reserved" 5 "Reserved" 4 "Reserved" 3 "Reserved" 2 "下Ready（维持高压）" 1 "上Ready" 0 "None" ;
VAL_ 630 Mdc_PwrOnOffReq 7 "Reserved" 6 "Reserved" 5 "Reserved" 4 "Reserved" 3 "Reserved" 2 "Power off  锁车+折叠后视镜+升窗+下电" 1 "Power on 上电" 0 "None" ;
VAL_ 1585 PDCM_PT_RMR 1 "Repeat Message State requested" 0 "Repeat Message State not requested" ;
VAL_ 1585 PDCM_PT_AWB 1 "Node has woken up the network (active Wakeup)" 0 "Node has not woken up the network (passive wakeup)" ;
VAL_ 1616 EPB_PT_RMR 1 "Repeat Message State requested" 0 "Repeat Message State not requested" ;
VAL_ 1616 EPB_PT_AWB 1 "Node has woken up the network (active Wakeup)" 0 "Node has not woken up the network (passive wakeup)" ;
VAL_ 1642 LBMS_RMR 1 "Repeat Message State requested" 0 "Repeat Message State not requested" ;
VAL_ 1642 LBMS_AWB 1 "Node has woken up the network (active Wakeup)" 0 "Node has not woken up the network (passive wakeup)" ;
VAL_ 1642 LBMS_RepeatSts 1 "Stay in the RMS" 0 "Not in the RMS" ;
VAL_ 1642 LBMS_NMReq_NM 1 "Active" 0 "Inactive" ;
VAL_ 1642 LBMS_NMReq_Diag 1 "Active" 0 "Inactive" ;
VAL_ 1642 LBMS_NMReq_Poweron 1 "Active" 0 "Inactive" ;
VAL_ 1642 LBMS_NMReq_LowSOCWakeup 1 "Active" 0 "Inactive" ;
VAL_ 1642 LBMS_NMReq_RechrgWakeup 1 "Active" 0 "Inactive" ;
VAL_ 1614 GW_PT_RMR 1 "Repeat Message State requested" 0 "Repeat Message State not requested" ;
VAL_ 1614 GW_PT_AWB 1 "Node has woken up the network (active Wakeup)" 0 "Node has not woken up the network (passive wakeup)" ;
VAL_ 992 ssm_ssPosition 7 "Uninitialized" 6 "Fully open" 5 "Reversed" 4 "Half open" 3 "Fully close" 2 "Second half of slide" 1 "First half of slide" 0 "Reserved" ;
VAL_ 992 srm_srOpenPosition 127 "Invalid" ;
VAL_ 992 ssm_ssOpenPosition 127 "Invalid" ;
